VERSION ""

NS_ :

BS_:

BU_: CLU H_U CGW

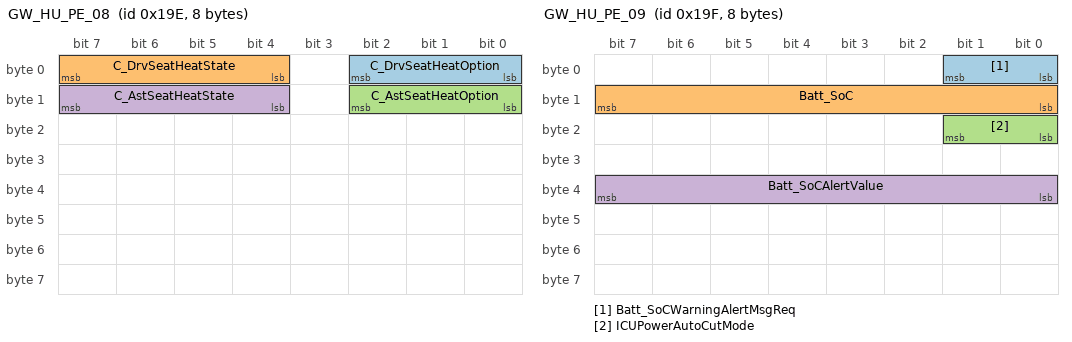
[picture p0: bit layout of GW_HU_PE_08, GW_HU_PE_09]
BO_ 414 GW_HU_PE_08: 8 CGW
 SG_ C_DrvSeatHeatOption : 2|3@0+ (1,0) [0|0] ""  H_U
 SG_ C_DrvSeatHeatState : 7|4@0+ (1,0) [0|0] ""  H_U
 SG_ C_AstSeatHeatOption : 10|3@0+ (1,0) [0|0] ""  H_U
 SG_ C_AstSeatHeatState : 15|4@0+ (1,0) [0|0] ""  H_U

BO_ 415 GW_HU_PE_09: 8 CGW
 SG_ Batt_SoCWarningAlertMsgReq : 1|2@0+ (1,0) [0|0] ""  H_U
 SG_ Batt_SoC : 15|8@0+ (1,0) [0|100] "%"  H_U
 SG_ ICUPowerAutoCutMode : 17|2@0+ (1,0) [0|3] ""  H_U
 SG_ Batt_SoCAlertValue : 39|8@0+ (1,0) [0|100] "%"  H_U

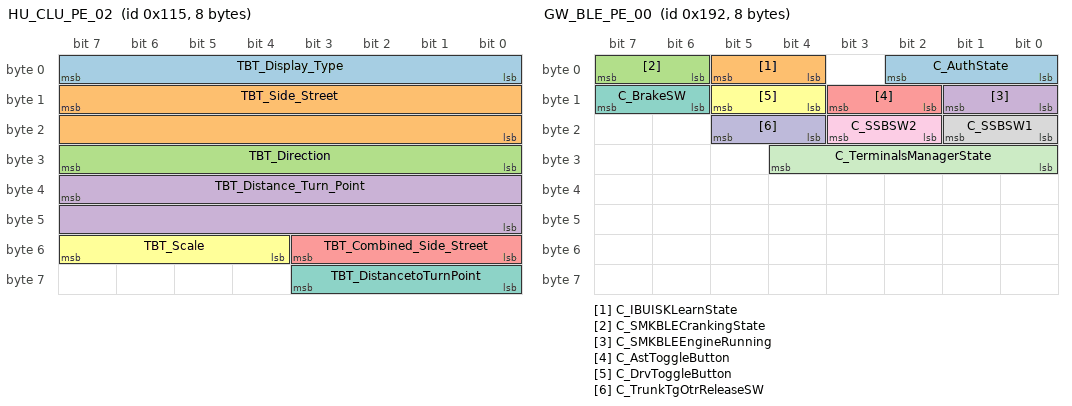
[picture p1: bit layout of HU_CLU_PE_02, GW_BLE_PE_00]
BO_ 277 HU_CLU_PE_02: 8 H_U
 SG_ TBT_Display_Type : 7|8@0+ (1,0) [0|0] ""  CLU
 SG_ TBT_Side_Street : 15|16@0+ (1,0) [0|0] ""  CLU
 SG_ TBT_Direction : 31|8@0+ (7.5,0) [0|352.5] "Degree"  CLU
 SG_ TBT_Distance_Turn_Point : 39|16@0+ (1,0) [0|0] "m"  CLU
 SG_ TBT_Combined_Side_Street : 51|4@0+ (1,0) [0|0] ""  CLU
 SG_ TBT_Scale : 55|4@0+ (1,0) [0|0] ""  CLU
 SG_ TBT_DistancetoTurnPoint : 59|4@0+ (1,0) [0|0] "times"  CLU

BO_ 413 GW_HU_PE_07: 8 CGW
 SG_ C_TSigLhSw : 37|2@0+ (1,0) [0|0] ""  H_U
 SG_ C_TSigRhSw : 39|2@0+ (1,0) [0|0] ""  H_U

BO_ 402 GW_BLE_PE_00: 8 CGW
 SG_ C_AuthState : 2|3@0+ (1,0) [0|0] ""  H_U
 SG_ C_IBUISKLearnState : 5|2@0+ (1,0) [0|0] ""  H_U
 SG_ C_SMKBLECrankingState : 7|2@0+ (1,0) [0|0] ""  H_U
 SG_ C_SMKBLEEngineRunning : 9|2@0+ (1,0) [0|0] ""  H_U
 SG_ C_AstToggleButton : 11|2@0+ (1,0) [0|0] ""  H_U
 SG_ C_DrvToggleButton : 13|2@0+ (1,0) [0|0] ""  H_U
 SG_ C_BrakeSW : 15|2@0+ (1,0) [0|0] ""  H_U
 SG_ C_SSBSW1 : 17|2@0+ (1,0) [0|0] ""  H_U
 SG_ C_SSBSW2 : 19|2@0+ (1,0) [0|0] ""  H_U
 SG_ C_TrunkTgOtrReleaseSW : 21|2@0+ (1,0) [0|0] ""  H_U
 SG_ C_TerminalsManagerState : 28|5@0+ (1,0) [0|0] ""  H_U

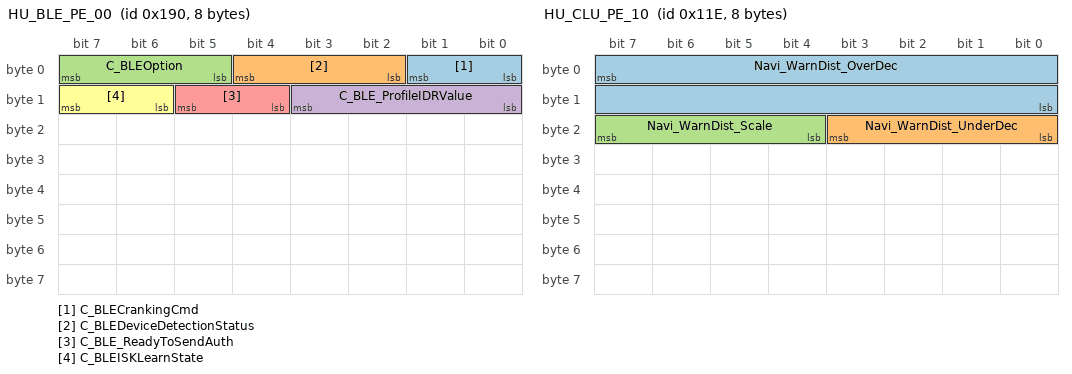
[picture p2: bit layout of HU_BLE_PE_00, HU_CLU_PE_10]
BO_ 400 HU_BLE_PE_00: 8 H_U
 SG_ C_BLECrankingCmd : 1|2@0+ (1,0) [0|0] ""  CGW
 SG_ C_BLEDeviceDetectionStatus : 4|3@0+ (1,0) [0|0] ""  CGW
 SG_ C_BLEOption : 7|3@0+ (1,0) [0|0] ""  CGW
 SG_ C_BLE_ProfileIDRValue : 11|4@0+ (1,0) [0|0] ""  CGW,CLU
 SG_ C_BLE_ReadyToSendAuth : 13|2@0+ (1,0) [0|0] ""  CGW
 SG_ C_BLEISKLearnState : 15|2@0+ (1,0) [0|0] ""  CGW

BO_ 286 HU_CLU_PE_10: 8 H_U
 SG_ Navi_WarnDist_OverDec : 7|16@0+ (1,0) [0|0] ""  CLU
 SG_ Navi_WarnDist_UnderDec : 19|4@0+ (1,0) [0|0] ""  CLU
 SG_ Navi_WarnDist_Scale : 23|4@0+ (1,0) [0|0] ""  CLU

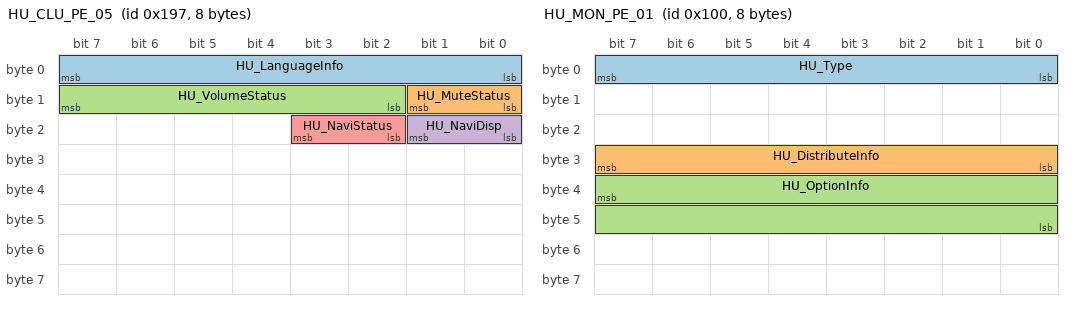
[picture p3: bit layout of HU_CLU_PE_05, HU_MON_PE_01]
BO_ 407 HU_CLU_PE_05: 8 H_U
 SG_ HU_LanguageInfo : 7|8@0+ (1,0) [0|0] ""  CGW,CLU
 SG_ HU_MuteStatus : 9|2@0+ (1,0) [0|0] ""  CLU
 SG_ HU_VolumeStatus : 15|6@0+ (1,0) [0|0] ""  CLU
 SG_ HU_NaviDisp : 17|2@0+ (1,0) [0|0] ""  CLU
 SG_ HU_NaviStatus : 19|2@0+ (1,0) [0|0] ""  CGW,CLU

BO_ 256 HU_MON_PE_01: 8 H_U
 SG_ HU_Type : 7|8@0+ (1,0) [0|0] ""  CGW,CLU
 SG_ HU_DistributeInfo : 31|8@0+ (1,0) [0|0] ""  CGW,CLU
 SG_ HU_OptionInfo : 39|16@0+ (1,0) [0|0] ""  CGW,CLU

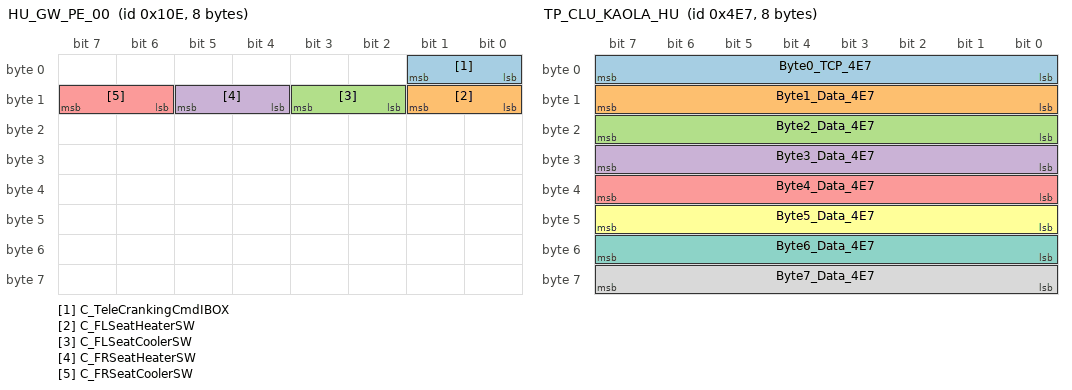
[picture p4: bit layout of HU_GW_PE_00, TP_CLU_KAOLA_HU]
BO_ 270 HU_GW_PE_00: 8 H_U
 SG_ C_TeleCrankingCmdIBOX : 1|2@0+ (1,0) [0|0] ""  CGW
 SG_ C_FLSeatHeaterSW : 9|2@0+ (1,0) [0|0] ""  CGW
 SG_ C_FLSeatCoolerSW : 11|2@0+ (1,0) [0|0] ""  CGW
 SG_ C_FRSeatHeaterSW : 13|2@0+ (1,0) [0|0] ""  CGW
 SG_ C_FRSeatCoolerSW : 15|2@0+ (1,0) [0|0] ""  CGW

BO_ 305 DATC_PE_02: 8 CGW
 SG_ DATC_DrTempDispC : 7|8@0+ (0.5,14) [15|32] "C"  H_U
 SG_ DATC_DrTempDispF : 23|8@0+ (1,56) [58|90] "F"  H_U

BO_ 1255 TP_CLU_KAOLA_HU: 8 CLU
 SG_ Byte0_TCP_4E7 : 7|8@0+ (1,0) [0|0] ""  H_U
 SG_ Byte1_Data_4E7 : 15|8@0+ (1,0) [0|0] ""  H_U
 SG_ Byte2_Data_4E7 : 23|8@0+ (1,0) [0|0] ""  H_U
 SG_ Byte3_Data_4E7 : 31|8@0+ (1,0) [0|0] ""  H_U
 SG_ Byte4_Data_4E7 : 39|8@0+ (1,0) [0|0] ""  H_U
 SG_ Byte5_Data_4E7 : 47|8@0+ (1,0) [0|0] ""  H_U
 SG_ Byte6_Data_4E7 : 55|8@0+ (1,0) [0|0] ""  H_U
 SG_ Byte7_Data_4E7 : 63|8@0+ (1,0) [0|0] ""  H_U

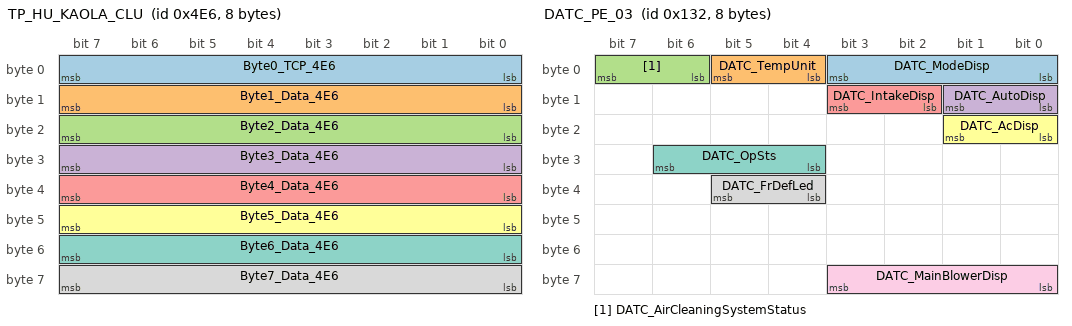
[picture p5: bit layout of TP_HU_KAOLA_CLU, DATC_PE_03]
BO_ 1254 TP_HU_KAOLA_CLU: 8 H_U
 SG_ Byte0_TCP_4E6 : 7|8@0+ (1,0) [0|0] ""  CLU
 SG_ Byte1_Data_4E6 : 15|8@0+ (1,0) [0|0] ""  CLU
 SG_ Byte2_Data_4E6 : 23|8@0+ (1,0) [0|0] ""  CLU
 SG_ Byte3_Data_4E6 : 31|8@0+ (1,0) [0|0] ""  CLU
 SG_ Byte4_Data_4E6 : 39|8@0+ (1,0) [0|0] ""  CLU
 SG_ Byte5_Data_4E6 : 47|8@0+ (1,0) [0|0] ""  CLU
 SG_ Byte6_Data_4E6 : 55|8@0+ (1,0) [0|0] ""  CLU
 SG_ Byte7_Data_4E6 : 63|8@0+ (1,0) [0|0] ""  CLU

BO_ 307 DATC_PE_04: 8 CGW
 SG_ DATC_SelfDiagDisp : 15|8@0+ (1,0) [0|0] ""  H_U
 SG_ DATC_Variant : 63|8@0+ (1,0) [0|0] ""  H_U

BO_ 306 DATC_PE_03: 8 CGW
 SG_ DATC_ModeDisp : 3|4@0+ (1,0) [0|0] ""  H_U
 SG_ DATC_TempUnit : 5|2@0+ (1,0) [0|0] ""  H_U
 SG_ DATC_AirCleaningSystemStatus : 7|2@0+ (1,0) [0|3] ""  H_U
 SG_ DATC_AutoDisp : 9|2@0+ (1,0) [0|0] ""  H_U
 SG_ DATC_IntakeDisp : 11|2@0+ (1,0) [0|0] ""  H_U
 SG_ DATC_AcDisp : 17|2@0+ (1,0) [0|0] ""  H_U
 SG_ DATC_OpSts : 30|3@0+ (1,0) [0|0] ""  H_U
 SG_ DATC_FrDefLed : 37|2@0+ (1,0) [0|0] ""  H_U
 SG_ DATC_MainBlowerDisp : 59|4@0+ (1,0) [0|0] ""  H_U

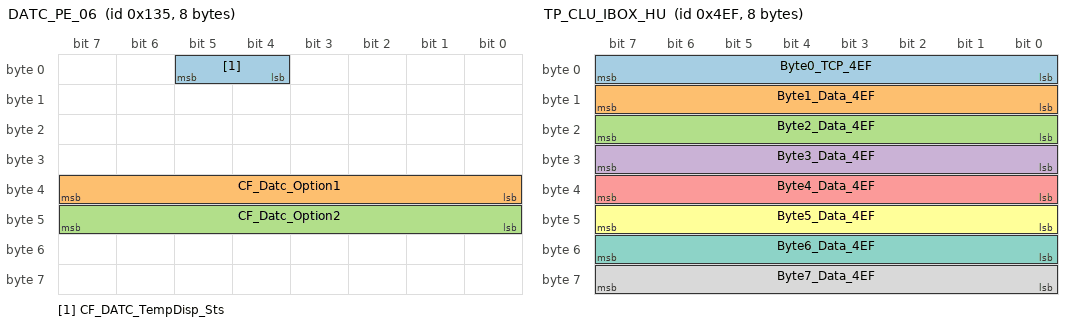
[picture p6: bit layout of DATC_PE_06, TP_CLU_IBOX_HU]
BO_ 309 DATC_PE_06: 8 CGW
 SG_ CF_DATC_TempDisp_Sts : 5|2@0+ (1,0) [0|0] ""  H_U
 SG_ CF_Datc_Option1 : 39|8@0+ (1,0) [0|0] ""  H_U
 SG_ CF_Datc_Option2 : 47|8@0+ (1,0) [0|0] ""  H_U

BO_ 1263 TP_CLU_IBOX_HU: 8 CLU
 SG_ Byte0_TCP_4EF : 7|8@0+ (1,0) [0|0] ""  H_U
 SG_ Byte1_Data_4EF : 15|8@0+ (1,0) [0|0] ""  H_U
 SG_ Byte2_Data_4EF : 23|8@0+ (1,0) [0|0] ""  H_U
 SG_ Byte3_Data_4EF : 31|8@0+ (1,0) [0|0] ""  H_U
 SG_ Byte4_Data_4EF : 39|8@0+ (1,0) [0|0] ""  H_U
 SG_ Byte5_Data_4EF : 47|8@0+ (1,0) [0|0] ""  H_U
 SG_ Byte6_Data_4EF : 55|8@0+ (1,0) [0|0] ""  H_U
 SG_ Byte7_Data_4EF : 63|8@0+ (1,0) [0|0] ""  H_U

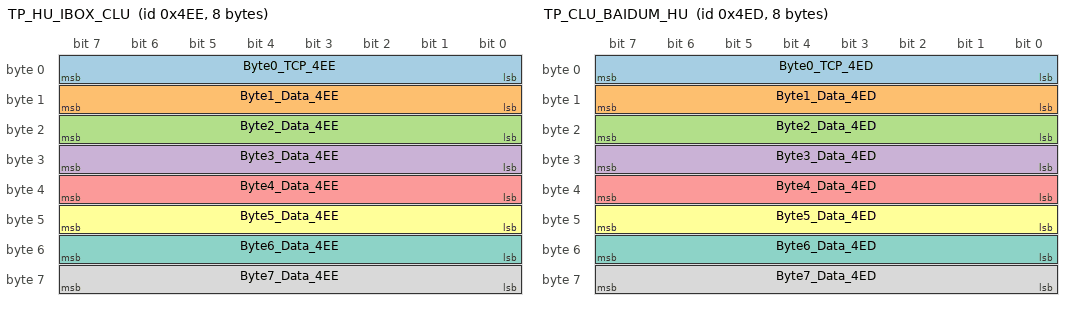
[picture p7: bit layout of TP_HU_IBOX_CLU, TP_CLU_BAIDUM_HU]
BO_ 1262 TP_HU_IBOX_CLU: 8 H_U
 SG_ Byte0_TCP_4EE : 7|8@0+ (1,0) [0|0] ""  CLU
 SG_ Byte1_Data_4EE : 15|8@0+ (1,0) [0|0] ""  CLU
 SG_ Byte2_Data_4EE : 23|8@0+ (1,0) [0|0] ""  CLU
 SG_ Byte3_Data_4EE : 31|8@0+ (1,0) [0|0] ""  CLU
 SG_ Byte4_Data_4EE : 39|8@0+ (1,0) [0|0] ""  CLU
 SG_ Byte5_Data_4EE : 47|8@0+ (1,0) [0|0] ""  CLU
 SG_ Byte6_Data_4EE : 55|8@0+ (1,0) [0|0] ""  CLU
 SG_ Byte7_Data_4EE : 63|8@0+ (1,0) [0|0] ""  CLU

BO_ 1261 TP_CLU_BAIDUM_HU: 8 CLU
 SG_ Byte0_TCP_4ED : 7|8@0+ (1,0) [0|0] ""  H_U
 SG_ Byte1_Data_4ED : 15|8@0+ (1,0) [0|0] ""  H_U
 SG_ Byte2_Data_4ED : 23|8@0+ (1,0) [0|0] ""  H_U
 SG_ Byte3_Data_4ED : 31|8@0+ (1,0) [0|0] ""  H_U
 SG_ Byte4_Data_4ED : 39|8@0+ (1,0) [0|0] ""  H_U
 SG_ Byte5_Data_4ED : 47|8@0+ (1,0) [0|0] ""  H_U
 SG_ Byte6_Data_4ED : 55|8@0+ (1,0) [0|0] ""  H_U
 SG_ Byte7_Data_4ED : 63|8@0+ (1,0) [0|0] ""  H_U

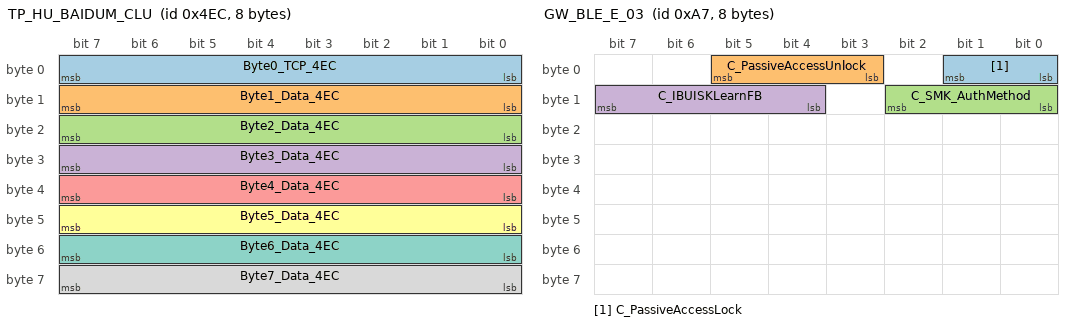
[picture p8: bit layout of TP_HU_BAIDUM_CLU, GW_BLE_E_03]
BO_ 1260 TP_HU_BAIDUM_CLU: 8 H_U
 SG_ Byte0_TCP_4EC : 7|8@0+ (1,0) [0|0] ""  CLU
 SG_ Byte1_Data_4EC : 15|8@0+ (1,0) [0|0] ""  CLU
 SG_ Byte2_Data_4EC : 23|8@0+ (1,0) [0|0] ""  CLU
 SG_ Byte3_Data_4EC : 31|8@0+ (1,0) [0|0] ""  CLU
 SG_ Byte4_Data_4EC : 39|8@0+ (1,0) [0|0] ""  CLU
 SG_ Byte5_Data_4EC : 47|8@0+ (1,0) [0|0] ""  CLU
 SG_ Byte6_Data_4EC : 55|8@0+ (1,0) [0|0] ""  CLU
 SG_ Byte7_Data_4EC : 63|8@0+ (1,0) [0|0] ""  CLU

BO_ 167 GW_BLE_E_03: 8 CGW
 SG_ C_PassiveAccessLock : 1|2@0+ (1,0) [0|0] ""  H_U
 SG_ C_PassiveAccessUnlock : 5|3@0+ (1,0) [0|0] ""  H_U
 SG_ C_SMK_AuthMethod : 10|3@0+ (1,0) [0|0] ""  H_U
 SG_ C_IBUISKLearnFB : 15|4@0+ (1,0) [0|0] ""  H_U

BO_ 166 GW_BLE_E_02: 8 CGW
 SG_ C_SMK_AuthReq : 2|3@0+ (1,0) [0|0] ""  H_U
 SG_ C_SMK_Random : 23|48@0+ (1,0) [0|0] ""  H_U

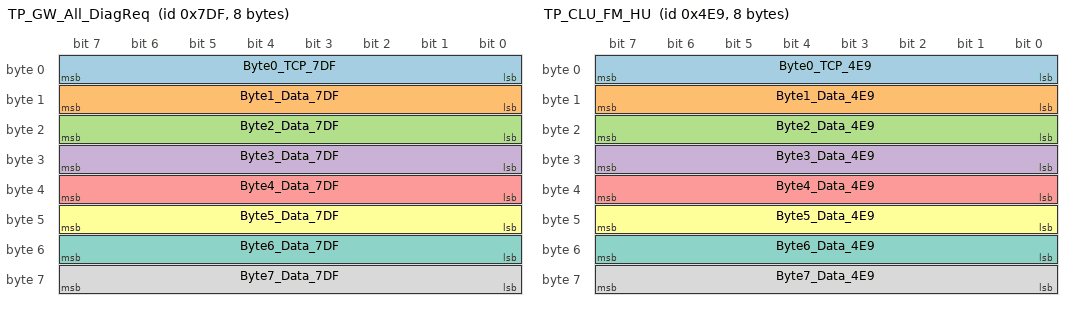
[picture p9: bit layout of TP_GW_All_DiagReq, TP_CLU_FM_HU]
BO_ 2015 TP_GW_All_DiagReq: 8 CGW
 SG_ Byte0_TCP_7DF : 7|8@0+ (1,0) [0|0] ""  CLU,H_U
 SG_ Byte1_Data_7DF : 15|8@0+ (1,0) [0|0] ""  CLU,H_U
 SG_ Byte2_Data_7DF : 23|8@0+ (1,0) [0|0] ""  CLU,H_U
 SG_ Byte3_Data_7DF : 31|8@0+ (1,0) [0|0] ""  CLU,H_U
 SG_ Byte4_Data_7DF : 39|8@0+ (1,0) [0|0] ""  CLU,H_U
 SG_ Byte5_Data_7DF : 47|8@0+ (1,0) [0|0] ""  CLU,H_U
 SG_ Byte6_Data_7DF : 55|8@0+ (1,0) [0|0] ""  CLU,H_U
 SG_ Byte7_Data_7DF : 63|8@0+ (1,0) [0|0] ""  CLU,H_U

BO_ 165 GW_BLE_E_01: 8 CGW
 SG_ C_SMK_Encrypted_Result2 : 7|64@0+ (1,0) [0|0] ""  H_U

BO_ 1257 TP_CLU_FM_HU: 8 CLU
 SG_ Byte0_TCP_4E9 : 7|8@0+ (1,0) [0|0] ""  H_U
 SG_ Byte1_Data_4E9 : 15|8@0+ (1,0) [0|0] ""  H_U
 SG_ Byte2_Data_4E9 : 23|8@0+ (1,0) [0|0] ""  H_U
 SG_ Byte3_Data_4E9 : 31|8@0+ (1,0) [0|0] ""  H_U
 SG_ Byte4_Data_4E9 : 39|8@0+ (1,0) [0|0] ""  H_U
 SG_ Byte5_Data_4E9 : 47|8@0+ (1,0) [0|0] ""  H_U
 SG_ Byte6_Data_4E9 : 55|8@0+ (1,0) [0|0] ""  H_U
 SG_ Byte7_Data_4E9 : 63|8@0+ (1,0) [0|0] ""  H_U

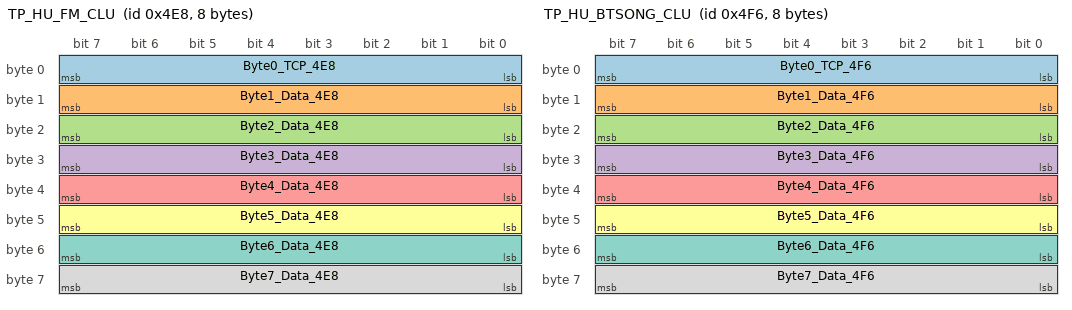
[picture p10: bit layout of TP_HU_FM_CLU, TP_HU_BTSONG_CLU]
BO_ 1256 TP_HU_FM_CLU: 8 H_U
 SG_ Byte0_TCP_4E8 : 7|8@0+ (1,0) [0|0] ""  CLU
 SG_ Byte1_Data_4E8 : 15|8@0+ (1,0) [0|0] ""  CLU
 SG_ Byte2_Data_4E8 : 23|8@0+ (1,0) [0|0] ""  CLU
 SG_ Byte3_Data_4E8 : 31|8@0+ (1,0) [0|0] ""  CLU
 SG_ Byte4_Data_4E8 : 39|8@0+ (1,0) [0|0] ""  CLU
 SG_ Byte5_Data_4E8 : 47|8@0+ (1,0) [0|0] ""  CLU
 SG_ Byte6_Data_4E8 : 55|8@0+ (1,0) [0|0] ""  CLU
 SG_ Byte7_Data_4E8 : 63|8@0+ (1,0) [0|0] ""  CLU

BO_ 164 GW_BLE_E_00: 8 CGW
 SG_ C_SMK_Encrypted_Result1 : 7|64@0+ (1,0) [0|0] ""  H_U

BO_ 1270 TP_HU_BTSONG_CLU: 8 H_U
 SG_ Byte0_TCP_4F6 : 7|8@0+ (1,0) [0|0] ""  CLU
 SG_ Byte1_Data_4F6 : 15|8@0+ (1,0) [0|0] ""  CLU
 SG_ Byte2_Data_4F6 : 23|8@0+ (1,0) [0|0] ""  CLU
 SG_ Byte3_Data_4F6 : 31|8@0+ (1,0) [0|0] ""  CLU
 SG_ Byte4_Data_4F6 : 39|8@0+ (1,0) [0|0] ""  CLU
 SG_ Byte5_Data_4F6 : 47|8@0+ (1,0) [0|0] ""  CLU
 SG_ Byte6_Data_4F6 : 55|8@0+ (1,0) [0|0] ""  CLU
 SG_ Byte7_Data_4F6 : 63|8@0+ (1,0) [0|0] ""  CLU

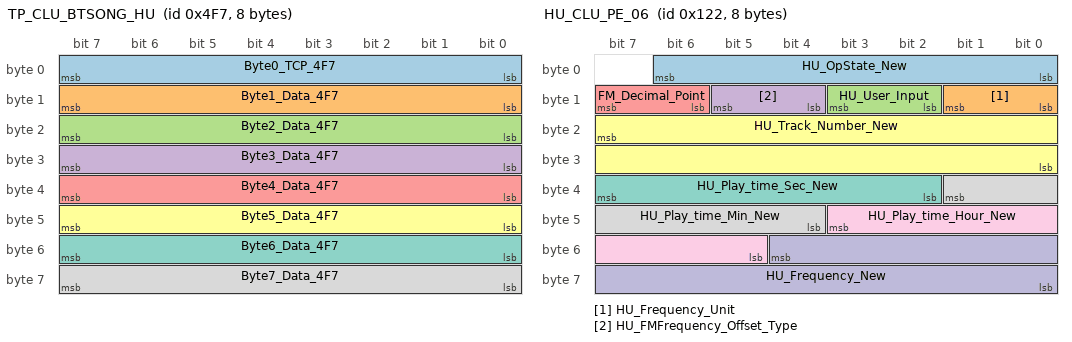
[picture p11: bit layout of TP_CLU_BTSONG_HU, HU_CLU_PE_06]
BO_ 1271 TP_CLU_BTSONG_HU: 8 CLU
 SG_ Byte0_TCP_4F7 : 7|8@0+ (1,0) [0|0] ""  H_U
 SG_ Byte1_Data_4F7 : 15|8@0+ (1,0) [0|0] ""  H_U
 SG_ Byte2_Data_4F7 : 23|8@0+ (1,0) [0|0] ""  H_U
 SG_ Byte3_Data_4F7 : 31|8@0+ (1,0) [0|0] ""  H_U
 SG_ Byte4_Data_4F7 : 39|8@0+ (1,0) [0|0] ""  H_U
 SG_ Byte5_Data_4F7 : 47|8@0+ (1,0) [0|0] ""  H_U
 SG_ Byte6_Data_4F7 : 55|8@0+ (1,0) [0|0] ""  H_U
 SG_ Byte7_Data_4F7 : 63|8@0+ (1,0) [0|0] ""  H_U

BO_ 290 HU_CLU_PE_06: 8 H_U
 SG_ HU_OpState_New : 6|7@0+ (1,0) [0|0] ""  CLU
 SG_ HU_Frequency_Unit : 9|2@0+ (1,0) [0|0] ""  CLU
 SG_ HU_User_Input : 11|2@0+ (1,0) [0|0] ""  CLU
 SG_ HU_FMFrequency_Offset_Type : 13|2@0+ (1,0) [0|0] ""  CLU
 SG_ FM_Decimal_Point : 15|2@0+ (1,0) [0|0] ""  CLU
 SG_ HU_Track_Number_New : 23|16@0+ (1,0) [0|0] ""  CLU
 SG_ HU_Play_time_Sec_New : 39|6@0+ (1,0) [0|0] ""  CLU
 SG_ HU_Play_time_Min_New : 33|6@0+ (1,0) [0|0] ""  CLU
 SG_ HU_Play_time_Hour_New : 43|7@0+ (1,0) [0|0] ""  CLU
 SG_ HU_Frequency_New : 52|13@0+ (1,0) [0|0] ""  CLU

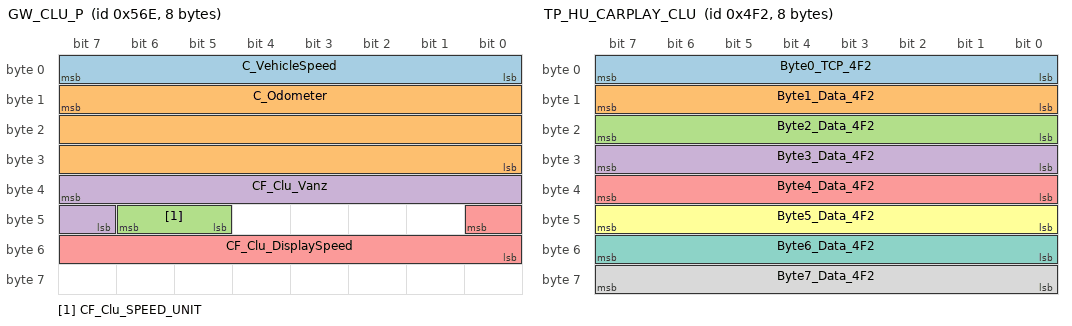
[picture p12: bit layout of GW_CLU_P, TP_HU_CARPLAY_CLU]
BO_ 1390 GW_CLU_P: 8 CGW
 SG_ C_VehicleSpeed : 7|8@0+ (1,0) [0|254] ""  H_U
 SG_ C_Odometer : 15|24@0+ (0.1,0) [0|1677721.4] ""  H_U
 SG_ CF_Clu_SPEED_UNIT : 46|2@0+ (1,0) [0|0] ""  H_U
 SG_ CF_Clu_Vanz : 39|9@0+ (0.5,0) [0|0] ""  H_U
 SG_ CF_Clu_DisplaySpeed : 40|9@0+ (1,0) [0|510] "km/h or MPH"  H_U

BO_ 291 HU_CLU_PE_07: 8 H_U
 SG_ NV_Display_TG : 31|2@0+ (1,0) [0|0] ""  CLU
 SG_ TBT_BarGraph100Level : 63|8@0+ (1,0) [0|100] "%"  CLU

BO_ 1266 TP_HU_CARPLAY_CLU: 8 H_U
 SG_ Byte0_TCP_4F2 : 7|8@0+ (1,0) [0|0] ""  CLU
 SG_ Byte1_Data_4F2 : 15|8@0+ (1,0) [0|0] ""  CLU
 SG_ Byte2_Data_4F2 : 23|8@0+ (1,0) [0|0] ""  CLU
 SG_ Byte3_Data_4F2 : 31|8@0+ (1,0) [0|0] ""  CLU
 SG_ Byte4_Data_4F2 : 39|8@0+ (1,0) [0|0] ""  CLU
 SG_ Byte5_Data_4F2 : 47|8@0+ (1,0) [0|0] ""  CLU
 SG_ Byte6_Data_4F2 : 55|8@0+ (1,0) [0|0] ""  CLU
 SG_ Byte7_Data_4F2 : 63|8@0+ (1,0) [0|0] ""  CLU

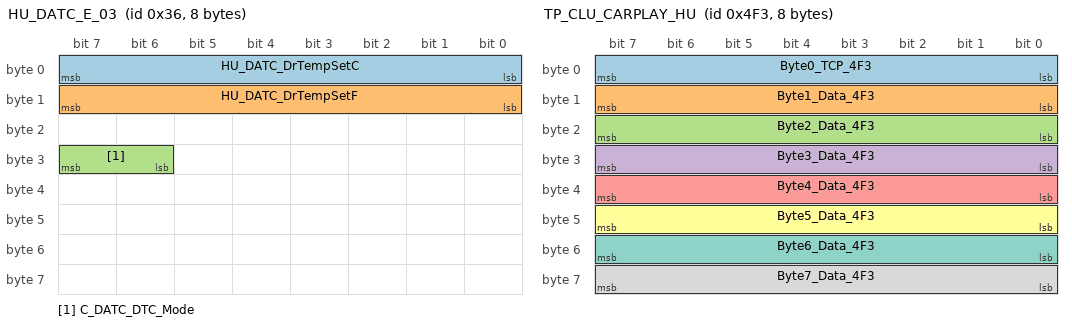
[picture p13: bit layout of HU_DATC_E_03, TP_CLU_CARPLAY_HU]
BO_ 54 HU_DATC_E_03: 8 H_U
 SG_ HU_DATC_DrTempSetC : 7|8@0+ (0.5,14) [15|32] "℃"  CGW,CLU
 SG_ HU_DATC_DrTempSetF : 15|8@0+ (1,56) [58|90] "℉"  CGW,CLU
 SG_ C_DATC_DTC_Mode : 31|2@0+ (1,0) [0|0] ""  CGW

BO_ 1267 TP_CLU_CARPLAY_HU: 8 CLU
 SG_ Byte0_TCP_4F3 : 7|8@0+ (1,0) [0|0] ""  H_U
 SG_ Byte1_Data_4F3 : 15|8@0+ (1,0) [0|0] ""  H_U
 SG_ Byte2_Data_4F3 : 23|8@0+ (1,0) [0|0] ""  H_U
 SG_ Byte3_Data_4F3 : 31|8@0+ (1,0) [0|0] ""  H_U
 SG_ Byte4_Data_4F3 : 39|8@0+ (1,0) [0|0] ""  H_U
 SG_ Byte5_Data_4F3 : 47|8@0+ (1,0) [0|0] ""  H_U
 SG_ Byte6_Data_4F3 : 55|8@0+ (1,0) [0|0] ""  H_U
 SG_ Byte7_Data_4F3 : 63|8@0+ (1,0) [0|0] ""  H_U

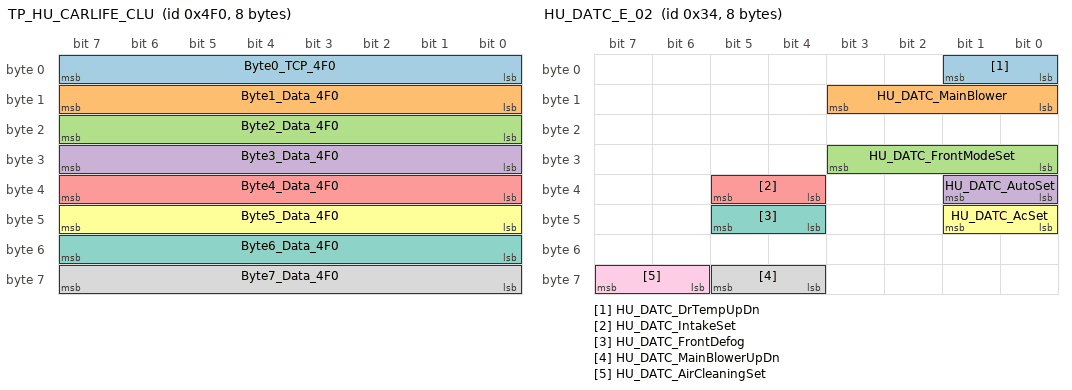
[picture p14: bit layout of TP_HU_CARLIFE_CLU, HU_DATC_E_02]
BO_ 1264 TP_HU_CARLIFE_CLU: 8 H_U
 SG_ Byte0_TCP_4F0 : 7|8@0+ (1,0) [0|0] ""  CLU
 SG_ Byte1_Data_4F0 : 15|8@0+ (1,0) [0|0] ""  CLU
 SG_ Byte2_Data_4F0 : 23|8@0+ (1,0) [0|0] ""  CLU
 SG_ Byte3_Data_4F0 : 31|8@0+ (1,0) [0|0] ""  CLU
 SG_ Byte4_Data_4F0 : 39|8@0+ (1,0) [0|0] ""  CLU
 SG_ Byte5_Data_4F0 : 47|8@0+ (1,0) [0|0] ""  CLU
 SG_ Byte6_Data_4F0 : 55|8@0+ (1,0) [0|0] ""  CLU
 SG_ Byte7_Data_4F0 : 63|8@0+ (1,0) [0|0] ""  CLU

BO_ 294 GW_RVM_PE_00: 8 CGW
 SG_ CAM_Status : 9|2@0+ (1,0) [0|0] ""  H_U

BO_ 52 HU_DATC_E_02: 8 H_U
 SG_ HU_DATC_DrTempUpDn : 1|2@0+ (1,0) [0|0] ""  CGW,CLU
 SG_ HU_DATC_MainBlower : 11|4@0+ (1,0) [0|0] ""  CGW,CLU
 SG_ HU_DATC_FrontModeSet : 27|4@0+ (1,0) [0|0] ""  CGW,CLU
 SG_ HU_DATC_AutoSet : 33|2@0+ (1,0) [0|0] ""  CGW,CLU
 SG_ HU_DATC_IntakeSet : 37|2@0+ (1,0) [0|0] ""  CGW,CLU
 SG_ HU_DATC_AcSet : 41|2@0+ (1,0) [0|0] ""  CGW,CLU
 SG_ HU_DATC_FrontDefog : 45|2@0+ (1,0) [0|0] ""  CGW,CLU
 SG_ HU_DATC_MainBlowerUpDn : 61|2@0+ (1,0) [0|0] ""  CGW,CLU
 SG_ HU_DATC_AirCleaningSet : 63|2@0+ (1,0) [0|0] ""  CGW,CLU

CM_ BO_ 305 "[PE] Periodic and On Event";
CM_ SG_ 305 DATC_DrTempDispC "Temperature of Driver seat (C)";
CM_ SG_ 305 DATC_DrTempDispF "Temperature of Driver seat (F)";
CM_ BO_ 306 "[PE] Periodic and On Event";
CM_ SG_ 306 DATC_ModeDisp "Display DATC Mode of Driver side



Basic Modes

- Defog : Defog

- Vent : Upper

- Def : Middle

- Floor : Lower



Mixed Modes

- Auto Defog : Defog + Auto 

- Max Defog : Defog + Seat



* Compatabilityfor old value table 

- Vent/Floor : same with old B/L 

- Defog/Floor : same with old MIX 

- Max Defog : same with old DEF";
CM_ SG_ 306 DATC_TempUnit "Unit of Temperature";
CM_ SG_ 306 DATC_AirCleaningSystemStatus "Air Cleaning System Operate Status";
CM_ SG_ 306 DATC_AutoDisp "Display AUTO";
CM_ SG_ 306 DATC_IntakeDisp "Display INTAKE";
CM_ SG_ 306 DATC_AcDisp "Display A/C";
CM_ SG_ 306 DATC_OpSts "Display DATC Operation Status";
CM_ SG_ 306 DATC_FrDefLed "Front Defo LED light status";
CM_ SG_ 306 DATC_MainBlowerDisp "Display Level of Main Blower";
CM_ BO_ 307 "[PE] Periodic and On Event";
CM_ SG_ 307 DATC_SelfDiagDisp "Inform HVAC Controller or Sensor error";
CM_ SG_ 307 DATC_Variant "Bit0 (FR CTRL) : 0 - ATC / 1 - MTC
Bit1~2 (Temp) : 00 - Single / 01 - Dual / 10 - 3 Zone / 11 - 4 Zone
Bit3~4 (Mode) : 00 - Single / 01 - Dual / 10 - 3 Zone / 11 - 4 Zone 
Bit5 (Rear Control) : 0 - (None or MTC) / 1 - ATC
Bit6 (RHD) : 0 - LHD / 1 - RHD
Bit7 (EU) : 0 - Others / 1 - EU";
CM_ BO_ 309 "[PE] Periodic and On Event";
CM_ SG_ 309 CF_DATC_TempDisp_Sts "This signal is an information display of the set temperature range of DATC.";
CM_ SG_ 309 CF_Datc_Option1 "This signal indicates Option of HEATER SYSTEM

Bit0 (ADS)? : 0 - Non ADS / 1 - ADS
 Bit1 (AQS) : 0 - Non AQS /? 1 ? AQS=
 Bit2 (MAX AC) : 0 - Non MAX AC / 1 - MAX AC
 Bit3 (SYNC) : 0 - Non SYNC /? 1 - SYNC 
 Bit4 (DUST) : 0 - Non AIR PURIFIER /? 1 - AIR PURIFIER 
 Bit5 : (Smart_Vent) : 0 - Non SMART VENT / 1 ? SMART VENT
 Bit6 : (CO2) : 0 - Non CO2 / 1 - CO2
 Bit7 : (REAR LOCK) : 0 - NON REAR LOCK / 1 ? REAR LOCK 
 0xFF : invalid";
CM_ SG_ 309 CF_Datc_Option2 "Bit0 (FRONT BLOWER) : 0 ? SINGLE BLOWER / 1 ? DUAL BLOWER
 Bit1 (FRONT AUTO ZONE) : 0 ? SINGLE AUTO / 1 - DUAL AUTO
 Bit2 (LCD / NON LCD TYPE) : 0- NON LCD / 1- LCD TYPE?
 Bit3 : Reserved 
 Bit4 : Reserved 
 Bit5 : Reserved 
 Bit6 : Reserved 
 Bit7 : Reserved
0xFF : Invalid";
CM_ BO_ 164 "[EC] On Event and On Change";
CM_ SG_ 164 C_SMK_Encrypted_Result1 "This signal is for a send encrypted result of IBU.";
CM_ BO_ 165 "[EC] On Event and On Change";
CM_ SG_ 165 C_SMK_Encrypted_Result2 "This signal is for a send encrypted result of IBU.";
CM_ BO_ 166 "[EC] On Event and On Change";
CM_ SG_ 166 C_SMK_AuthReq "Request BLE authentication";
CM_ SG_ 166 C_SMK_Random "Random number";
CM_ BO_ 167 "[EC] On Event and On Change";
CM_ SG_ 167 C_PassiveAccessLock "BLE passive lock command response";
CM_ SG_ 167 C_PassiveAccessUnlock "BLE passive unlock command response";
CM_ SG_ 167 C_SMK_AuthMethod "This signal is for a send Authentication result and authentication method.
- Fob, TP, Fingerprint, NFC, BLE";
CM_ SG_ 167 C_IBUISKLearnFB "This signal is Learning Feedback";
CM_ BO_ 402 "[PE] Periodic and On Event";
CM_ SG_ 402 C_AuthState "This signal is status of IBU auth";
CM_ SG_ 402 C_IBUISKLearnState "This signal is State of IBU Learning";
CM_ SG_ 402 C_SMKBLECrankingState "BLE cranking response";
CM_ SG_ 402 C_SMKBLEEngineRunning "This signal is state of engine running, for BLE engine start command.";
CM_ SG_ 402 C_AstToggleButton "This signal is for assist door handle button";
CM_ SG_ 402 C_DrvToggleButton "This signal is for driver door handle button.";
CM_ SG_ 402 C_BrakeSW "SMK+ Brake SW input state";
CM_ SG_ 402 C_SSBSW1 "StartStop button switch #1 status";
CM_ SG_ 402 C_SSBSW2 "StartStop button switch #2 status";
CM_ SG_ 402 C_TrunkTgOtrReleaseSW "Trunk/Tailgate Outter Release SW";
CM_ SG_ 402 C_TerminalsManagerState "Mirror value of TerminalsManager Stat";
CM_ BO_ 1390 "[P] Periodic";
CM_ SG_ 1390 C_VehicleSpeed "Information for Vehicle speed
* For ASD Option Vehicle, Use ASD_VehicleSpeed (@0x500) instead *";
CM_ SG_ 1390 C_Odometer "Information for Odometer in kilometer";
CM_ SG_ 1390 CF_Clu_SPEED_UNIT "This signal is unit of display speed in cluster";
CM_ SG_ 1390 CF_Clu_Vanz "This signal is display speed in cluster.";
CM_ SG_ 1390 CF_Clu_DisplaySpeed "The Display Speed which is indicated in the speedometer has to be sent to CGW, HUD. This signal should be sent in km/h or MPH according to the 'SPEED_UNIT' signal.  
SPEED_UNIT = 0 : [km/h]
SPEED_UNIT = 1 : [MPH]";
CM_ BO_ 413 "[PE] Periodic and On Event";
CM_ SG_ 413 C_TSigLhSw "Status of Left Turn Signal On/Off";
CM_ SG_ 413 C_TSigRhSw "Status of Right Turn Signal On/Off";
CM_ BO_ 414 "[PE] Periodic and On Event";
CM_ SG_ 414 C_DrvSeatHeatOption "Seat Option information for Remote Seat Heat/Vent control (Driver)";
CM_ SG_ 414 C_DrvSeatHeatState "Current Seat State information for Remote Seat Heat/Vent control (Driver)";
CM_ SG_ 414 C_AstSeatHeatOption "Seat Option information for Remote Seat Heat/Vent control (Passenger)";
CM_ SG_ 414 C_AstSeatHeatState "Current Seat State information for Remote Seat Heat/Vent control (Passenger)";
CM_ BO_ 415 "[PE] Periodic and On Event";
CM_ SG_ 415 Batt_SoCWarningAlertMsgReq "Determine if soc level is warning or alert.";
CM_ SG_ 415 Batt_SoC "State of Charge.";
CM_ SG_ 415 ICUPowerAutoCutMode "ICU Delivery Mode State";
CM_ SG_ 415 Batt_SoCAlertValue "Value of SoC alert level";
CM_ BO_ 294 "[PE] Periodic and On Event";
CM_ SG_ 294 CAM_Status "AHD(Analog High Definition) camera status for HU";
CM_ BO_ 2015 "[TP] TP Message";
CM_ SG_ 2015 Byte0_TCP_7DF "TP";
CM_ SG_ 2015 Byte1_Data_7DF "TP";
CM_ SG_ 2015 Byte2_Data_7DF "TP";
CM_ SG_ 2015 Byte3_Data_7DF "TP";
CM_ SG_ 2015 Byte4_Data_7DF "TP";
CM_ SG_ 2015 Byte5_Data_7DF "TP";
CM_ SG_ 2015 Byte6_Data_7DF "TP";
CM_ SG_ 2015 Byte7_Data_7DF "TP";
CM_ BO_ 1261 "[TP] TP Message";
CM_ SG_ 1261 Byte0_TCP_4ED "Contents releted with Baidu Music";
CM_ SG_ 1261 Byte1_Data_4ED "Contents releted with Baidu Music";
CM_ SG_ 1261 Byte2_Data_4ED "Contents releted with Baidu Music";
CM_ SG_ 1261 Byte3_Data_4ED "Contents releted with Baidu Music";
CM_ SG_ 1261 Byte4_Data_4ED "Contents releted with Baidu Music";
CM_ SG_ 1261 Byte5_Data_4ED "Contents releted with Baidu Music";
CM_ SG_ 1261 Byte6_Data_4ED "Contents releted with Baidu Music";
CM_ SG_ 1261 Byte7_Data_4ED "Contents releted with Baidu Music";
CM_ BO_ 1271 "[TP] TP Message";
CM_ BO_ 1267 "[TP] TP Message";
CM_ BO_ 1257 "[TP] TP Message";
CM_ SG_ 1257 Byte0_TCP_4E9 "TP from CLU to HU (FM Station Name)";
CM_ SG_ 1257 Byte1_Data_4E9 "TP from CLU to HU (FM Station Name)";
CM_ SG_ 1257 Byte2_Data_4E9 "TP from CLU to HU (FM Station Name)";
CM_ SG_ 1257 Byte3_Data_4E9 "TP from CLU to HU (FM Station Name)";
CM_ SG_ 1257 Byte4_Data_4E9 "TP from CLU to HU (FM Station Name)";
CM_ SG_ 1257 Byte5_Data_4E9 "TP from CLU to HU (FM Station Name)";
CM_ SG_ 1257 Byte6_Data_4E9 "TP from CLU to HU (FM Station Name)";
CM_ SG_ 1257 Byte7_Data_4E9 "TP from CLU to HU (FM Station Name)";
CM_ BO_ 1263 "[TP] TP Message";
CM_ SG_ 1263 Byte0_TCP_4EF "Flow Control message for TP_HU_IBOX_CLU";
CM_ SG_ 1263 Byte1_Data_4EF "Flow Control message for TP_HU_IBOX_CLU";
CM_ SG_ 1263 Byte2_Data_4EF "Flow Control message for TP_HU_IBOX_CLU";
CM_ SG_ 1263 Byte3_Data_4EF "Flow Control message for TP_HU_IBOX_CLU";
CM_ SG_ 1263 Byte4_Data_4EF "Flow Control message for TP_HU_IBOX_CLU";
CM_ SG_ 1263 Byte5_Data_4EF "Flow Control message for TP_HU_IBOX_CLU";
CM_ SG_ 1263 Byte6_Data_4EF "Flow Control message for TP_HU_IBOX_CLU";
CM_ SG_ 1263 Byte7_Data_4EF "Flow Control message for TP_HU_IBOX_CLU";
CM_ BO_ 1255 "[TP] TP Message";
CM_ SG_ 1255 Byte0_TCP_4E7 "Contents related with Kaola FM";
CM_ SG_ 1255 Byte1_Data_4E7 "Contents related with Kaola FM";
CM_ SG_ 1255 Byte2_Data_4E7 "Contents related with Kaola FM";
CM_ SG_ 1255 Byte3_Data_4E7 "Contents related with Kaola FM";
CM_ SG_ 1255 Byte4_Data_4E7 "Contents related with Kaola FM";
CM_ SG_ 1255 Byte5_Data_4E7 "Contents related with Kaola FM";
CM_ SG_ 1255 Byte6_Data_4E7 "Contents related with Kaola FM";
CM_ SG_ 1255 Byte7_Data_4E7 "Contents related with Kaola FM";
CM_ BO_ 400 "[PE] Periodic and On Event";
CM_ SG_ 400 C_BLECrankingCmd "For BLE Remote Cranking Command";
CM_ SG_ 400 C_BLEDeviceDetectionStatus "BLE Device Detection Status (Door Handle, SSB)";
CM_ SG_ 400 C_BLEOption "BLE Option Info(NFC, FP, BLE, etc)";
CM_ SG_ 400 C_BLE_ProfileIDRValue "This signal Indicate the Current detected Profile ID by BLE";
CM_ SG_ 400 C_BLE_ReadyToSendAuth "This signal is sent when BLE is ready to send Authentication data";
CM_ SG_ 400 C_BLEISKLearnState "This signal is State of BLE Learning";
CM_ BO_ 277 "[PE] Periodic and On Event";
CM_ SG_ 277 TBT_Display_Type "Information for NAVI TBT Display type";
CM_ SG_ 277 TBT_Side_Street "Information for whole directions of street
(Using according to display type definition)
15 directions (except backward) are assigned to each 15 bits";
CM_ SG_ 277 TBT_Direction "Information for direction defined at TBT_Display_Type
- 48 directions (7.5 deg. Interval)
- Vehicles following HUD/Cluster Interface Spec (ES-96560-22) use only 16 directions (22.5 deg. Interval)";
CM_ SG_ 277 TBT_Distance_Turn_Point "Remaining distance to turn point (over Decimal Point)";
CM_ SG_ 277 TBT_Combined_Side_Street "Information for direction of combined side street (in front of turn point)
(Using according to display type definition)";
CM_ SG_ 277 TBT_Scale "Information for Scale unit (m, km, mile, feet)";
CM_ SG_ 277 TBT_DistancetoTurnPoint "Information for remaining distance from turn point (under Decimal Point)";
CM_ BO_ 407 "[PE] Periodic and On Event";
CM_ SG_ 407 HU_LanguageInfo "Information for System Language (for Display Font)";
CM_ SG_ 407 HU_MuteStatus "Information for System Mute Display";
CM_ SG_ 407 HU_VolumeStatus "Information for AVN Volume";
CM_ SG_ 407 HU_NaviDisp "Information for Navi Display status on Front Monitor";
CM_ SG_ 407 HU_NaviStatus "Information for Navigation Status (Booting, Normal Operation, No SD card)
-AVN NAVI Transmission Signal";
CM_ BO_ 290 "[PE] Periodic and On Event";
CM_ SG_ 290 HU_OpState_New "Information for AV Operation mode";
CM_ SG_ 290 HU_Frequency_Unit "Information for Frequency unit display";
CM_ SG_ 290 HU_User_Input "User Input (Seek Up/Dn, Mode Change)
# Singnal Trigger Condition
1. DiscCD/MP3CD/VCD
 - Track Up/Dn (by SoftKey)
 - Track Up/Dn (by HardKey)
 - Song Change (by List)
 - Song Cjamge (by Tune Enter)
2. DVD (No TP)
 - Track Up/Dn (by SoftKey)
 - Track Up/Dn (by HardKey)
 - Song Change (by List)
 - Song Cjamge (by Tune Enter)
3. DMB/DAB
 - Track Up/Dn (by HardKey)
 - Song Change (by List)
 - Song Cjamge (by Tune Enter)
4. FM/AM/SXM
 - Track Up/Dn (by HardKey)
 - Song Change (by List)
5. ITM(FM/DAB)
 - Track Up/Dn (by HardKey)
 - Song Change (by List)
 - Song Cjamge (by Tune Enter)
6. USB Music/Video/My Music/JukeBox/iPod/Pandora
 - Track Up/Dn (by SoftKey)
 - Track Up/Dn (by HardKey)
 - Song Change (by List)
 - Song Cjamge (by Tune Enter)
7. Bluetooth Audio
 - Track Up/Dn (by SoftKey)
 - Track Up/Dn (by HardKey)
8. CarPlay/Android Auto
 - Track Up/Dn (by HardKey)";
CM_ SG_ 290 HU_FMFrequency_Offset_Type "Information for FM frequency offset type";
CM_ SG_ 290 FM_Decimal_Point "Information for Frequency decimal point";
CM_ SG_ 290 HU_Track_Number_New "Information for Number of Track / Chapter / Playlist";
CM_ SG_ 290 HU_Play_time_Sec_New "Information for Play time in Second unit";
CM_ SG_ 290 HU_Play_time_Min_New "Information for Play time in Minute unit";
CM_ SG_ 290 HU_Play_time_Hour_New "Information for Play time in Hour unit";
CM_ SG_ 290 HU_Frequency_New "Information for Radio Frequency";
CM_ BO_ 291 "[PE] Periodic and On Event";
CM_ SG_ 291 NV_Display_TG "Information for Toll Gate Display";
CM_ SG_ 291 TBT_BarGraph100Level "Information for Bar Graph Level (0 ~ 100%, 10% interval), 

if your system develop after 2012-09-10, you must not use TBT_Bar_Level(@0x115)";
CM_ BO_ 286 "[PE] Periodic and On Event";
CM_ SG_ 286 Navi_WarnDist_OverDec "Remaining distance to warning information (over decimal point)";
CM_ SG_ 286 Navi_WarnDist_UnderDec "Remaining distance to warning information (under decimal point)";
CM_ SG_ 286 Navi_WarnDist_Scale "Scale unit of warning distance";
CM_ BO_ 52 "[EC] On Event and On Change";
CM_ SG_ 52 HU_DATC_DrTempUpDn "Temperature control of Driver side";
CM_ SG_ 52 HU_DATC_MainBlower "Main Blower control";
CM_ SG_ 52 HU_DATC_FrontModeSet "DATC Mode control";
CM_ SG_ 52 HU_DATC_AutoSet "DATC Auto control";
CM_ SG_ 52 HU_DATC_IntakeSet "DATC Intake control";
CM_ SG_ 52 HU_DATC_AcSet "DATC A/C control";
CM_ SG_ 52 HU_DATC_FrontDefog "Front window Defog";
CM_ SG_ 52 HU_DATC_MainBlowerUpDn "Main Blower Up/Down control";
CM_ SG_ 52 HU_DATC_AirCleaningSet "Air Cleaning System set";
CM_ BO_ 54 "[EC] On Event and On Change";
CM_ SG_ 54 HU_DATC_DrTempSetC "In single type DATC, set temperature of front side directly(Centigrade).
In dual type DATC, set temperature of front left side directly(Centigrade).";
CM_ SG_ 54 HU_DATC_DrTempSetF "In single type DATC, set temperature of front side directly (Fahrenheit).
In dual type DATC, set temperature of front left side directly (Fahrenheit).";
CM_ SG_ 54 C_DATC_DTC_Mode "HU diagnosis request to DATC";
CM_ BO_ 270 "[PE] Periodic and On Event";
CM_ SG_ 270 C_TeleCrankingCmdIBOX "Command for Remote Cranking
(C_SMKTeleEngineRunning@0x15E is feedback signal)";
CM_ SG_ 270 C_FLSeatHeaterSW "HU touch command for seat heat control (For driver seat)";
CM_ SG_ 270 C_FLSeatCoolerSW "HU touch command for seat vent control (For driver seat)";
CM_ SG_ 270 C_FRSeatHeaterSW "HU touch command for seat heat control (For passenger seat)";
CM_ SG_ 270 C_FRSeatCoolerSW "HU touch command for seat vent control  (For passenger seat)";
CM_ BO_ 256 "[PE] Periodic and On Event";
CM_ SG_ 256 HU_Type "Information for H/U Platform type
- Integrated AVN 1.0 use different value depends on development company (Mobis:0x68/LG:0x70)
- Integrated AVN 1.0 Mobis is developed based on Display Audio
- Integrated AVN 1.0 LG is developed based on Compact AVN

Information for China OPIO Platform
- 0xFC: China OPIO w/o CLU interface (most of phase1)
- 0xFD: China OPIO w/CLU interface (parts of phase1, phase2)

Information for Audio Platform Type
- 0x43 : Audio 4.0 Value";
CM_ SG_ 256 HU_DistributeInfo "Region :Europe/North America/
Vehicle Type : RHD/LHD
Positionning information";
CM_ SG_ 256 HU_OptionInfo "Information of H/U functions";
CM_ BO_ 1260 "[TP] TP Message";
CM_ SG_ 1260 Byte0_TCP_4EC "Contents releted with Baidu Music";
CM_ SG_ 1260 Byte1_Data_4EC "Contents releted with Baidu Music";
CM_ SG_ 1260 Byte2_Data_4EC "Contents releted with Baidu Music";
CM_ SG_ 1260 Byte3_Data_4EC "Contents releted with Baidu Music";
CM_ SG_ 1260 Byte4_Data_4EC "Contents releted with Baidu Music";
CM_ SG_ 1260 Byte5_Data_4EC "Contents releted with Baidu Music";
CM_ SG_ 1260 Byte6_Data_4EC "Contents releted with Baidu Music";
CM_ SG_ 1260 Byte7_Data_4EC "Contents releted with Baidu Music";
CM_ BO_ 1270 "[TP] TP Message";
CM_ BO_ 1264 "[TP] TP Message";
CM_ BO_ 1266 "[TP] TP Message";
CM_ BO_ 1256 "[TP] TP Message";
CM_ SG_ 1256 Byte0_TCP_4E8 "TP from HU to CLU (FM Station Name)";
CM_ SG_ 1256 Byte1_Data_4E8 "TP from HU to CLU (FM Station Name)";
CM_ SG_ 1256 Byte2_Data_4E8 "TP from HU to CLU (FM Station Name)";
CM_ SG_ 1256 Byte3_Data_4E8 "TP from HU to CLU (FM Station Name)";
CM_ SG_ 1256 Byte4_Data_4E8 "TP from HU to CLU (FM Station Name)";
CM_ SG_ 1256 Byte5_Data_4E8 "TP from HU to CLU (FM Station Name)";
CM_ SG_ 1256 Byte6_Data_4E8 "TP from HU to CLU (FM Station Name)";
CM_ SG_ 1256 Byte7_Data_4E8 "TP from HU to CLU (FM Station Name)";
CM_ BO_ 1262 "[TP] TP Message";
CM_ BO_ 1262 "[TP] TP Message";
CM_ SG_ 1262 Byte0_TCP_4EE "Song Name, Artist, File Name, Play Time of iBox player";
CM_ SG_ 1262 Byte1_Data_4EE "Song Name, Artist, File Name, Play Time of iBox player";
CM_ SG_ 1262 Byte2_Data_4EE "Song Name, Artist, File Name, Play Time of iBox player";
CM_ SG_ 1262 Byte3_Data_4EE "Song Name, Artist, File Name, Play Time of iBox player";
CM_ SG_ 1262 Byte4_Data_4EE "Song Name, Artist, File Name, Play Time of iBox player";
CM_ SG_ 1262 Byte5_Data_4EE "Song Name, Artist, File Name, Play Time of iBox player";
CM_ SG_ 1262 Byte6_Data_4EE "Song Name, Artist, File Name, Play Time of iBox player";
CM_ SG_ 1262 Byte7_Data_4EE "Song Name, Artist, File Name, Play Time of iBox player";
CM_ BO_ 1254 "[TP] TP Message";
CM_ SG_ 1254 Byte0_TCP_4E6 "Contents related with Kaola FM";
CM_ SG_ 1254 Byte1_Data_4E6 "Contents related with Kaola FM";
CM_ SG_ 1254 Byte2_Data_4E6 "Contents related with Kaola FM";
CM_ SG_ 1254 Byte3_Data_4E6 "Contents related with Kaola FM";
CM_ SG_ 1254 Byte4_Data_4E6 "Contents related with Kaola FM";
CM_ SG_ 1254 Byte5_Data_4E6 "Contents related with Kaola FM";
CM_ SG_ 1254 Byte6_Data_4E6 "Contents related with Kaola FM";
CM_ SG_ 1254 Byte7_Data_4E6 "Contents related with Kaola FM";
BA_DEF_ SG_ "Gatewaysignal" ENUM "No","M-B","B-M","M-C","C-M","M-C-B" ;
BA_DEF_ SG_ "GenSigEnvVarType" ENUM "Int","Float","undef" ;
BA_DEF_ SG_ "GenSigSendType" ENUM "Cyclic","OnWrite","OnWriteWithRepetition","OnChange","OnChangeWithRepetition","IfActive","IfActiveWithRepetition","NoSigSendType" ;
BA_DEF_ SG_ "GenSigStartValue" INT 0 0 ;
BA_DEF_ SG_ "GwSigLatencyTime" INT 0 65535 ;
BA_DEF_ SG_ "GwSigMissingSourceType" ENUM "Undef","OldValue","DefaultValue","InitialValue" ;
BA_DEF_ SG_ "NmNetworkRequest" ENUM "No","Yes" ;
BA_DEF_ SG_ "NmNetworkRequestHoldingTime" INT 0 65535 ;
BA_DEF_ SG_ "Purpose" ENUM "<t.b.d.>","Function","Diagnostic","Development","NM" ;
BA_DEF_ SG_ "SignalCategory" HEX 10 15 ;
BA_DEF_ SG_ "TimeoutValue" STRING ;
BA_DEF_ SG_ "UpdateRateMax" INT 0 0 ;
BA_DEF_ SG_ "UpdateRateMin" INT 0 0 ;
BA_DEF_ SG_ "Validity" ENUM "B+","ACC","IGN1","IGN2" ;
BA_DEF_ BO_ "DiagRequest" ENUM "No","Yes" ;
BA_DEF_ BO_ "DiagResponse" ENUM "No","Yes" ;
BA_DEF_ BO_ "DiagState" ENUM "No","Yes" ;
BA_DEF_ BO_ "GenMsgCycleTime" INT 0 100000 ;
BA_DEF_ BO_ "GenMsgCycleTimeFast" INT 0 500 ;
BA_DEF_ BO_ "GenMsgDelayTime" INT 0 20 ;
BA_DEF_ BO_ "GenMsgEVName" STRING ;
BA_DEF_ BO_ "GenMsgILSupport" ENUM "No","Yes" ;
BA_DEF_ BO_ "GenMsgNrOfRepetition" INT 0 3 ;
BA_DEF_ BO_ "GenMsgSendType" ENUM "Cyclic","not_used","not_used","not_used","not_used","not_used","not_used","not_used","NoMsgSendType" ;
BA_DEF_ BO_ "GenMsgStartDelayTime" INT 0 2000 ;
BA_DEF_ BO_ "NmMessage" ENUM "No","Yes" ;
BA_DEF_ BO_ "RoutingType" ENUM "<n.a.>","Direct","Indirect" ;
BA_DEF_ BO_ "TpMessage" ENUM "No","Yes" ;
BA_DEF_ BO_ "TpTxIndex" INT 0 255 ;
BA_DEF_ BU_ "GenNodSleepTime" INT 1375 1650 ;
BA_DEF_ BU_ "ILUsed" ENUM "No","Yes" ;
BA_DEF_ BU_ "NmCAN" INT 1 2 ;
BA_DEF_ BU_ "NmNode" ENUM "No","Yes" ;
BA_DEF_ BU_ "NmStationAddress" HEX 0 255 ;
BA_DEF_ BU_ "NodeLayerModules" STRING ;
BA_DEF_ "Baudrate" INT 50000 500000 ;
BA_DEF_ "BusType" STRING ;
BA_DEF_ "GenEnvVarEndingDsp" STRING ;
BA_DEF_ "GenEnvVarEndingSnd" STRING ;
BA_DEF_ "GenEnvVarPrefix" STRING ;
BA_DEF_ "GenNWMApBusSleep" STRING ;
BA_DEF_ "GenNWMApCanNormal" STRING ;
BA_DEF_ "GenNWMApCanOff" STRING ;
BA_DEF_ "GenNWMApCanOn" STRING ;
BA_DEF_ "GenNWMApCanSleep" STRING ;
BA_DEF_ "GenNWMApCanWakeUp" STRING ;
BA_DEF_ "GenNWMGotoMode_Awake" STRING ;
BA_DEF_ "GenNWMGotoMode_BusSleep" STRING ;
BA_DEF_ "GenNWMSleepTime" INT 1375 1650 ;
BA_DEF_ "GenNWMTalkNM" STRING ;
BA_DEF_ "Manufacturer" STRING ;
BA_DEF_ "NmBaseAddress" HEX 0 2047 ;
BA_DEF_ "NmMessageCount" INT 0 128 ;
BA_DEF_ "NmType" STRING ;
BA_DEF_ "SamplePointMax" INT 50 85 ;
BA_DEF_ "SamplePointMin" INT 55 85 ;
BA_DEF_ "SyncJumpWidthMax" INT 1 8 ;
BA_DEF_ "SyncJumpWidthMin" INT 1 4 ;
BA_DEF_ "VersionDay" INT 1 31 ;
BA_DEF_ "VersionMonth" INT 1 12 ;
BA_DEF_ "VersionNumber" INT 0 999999 ;
BA_DEF_ "VersionWeek" INT 1 53 ;
BA_DEF_ "VersionYear" INT 0 9999 ;
BA_DEF_ SG_ "SigDescription" STRING ;
BA_DEF_ SG_ "Platform" STRING ;
BA_DEF_ SG_ "SigOldType" ENUM "No","Yes" ;
BA_DEF_REL_ BU_SG_REL_ "GenSigTimeoutTime" INT 0 7000 ;
BA_DEF_DEF_ "Gatewaysignal" "No" ;
BA_DEF_DEF_ "GenSigEnvVarType" "undef" ;
BA_DEF_DEF_ "GenSigSendType" "NoSigSendType" ;
BA_DEF_DEF_ "GenSigStartValue" 0 ;
BA_DEF_DEF_ "GwSigLatencyTime" 40 ;
BA_DEF_DEF_ "GwSigMissingSourceType" "Undef" ;
BA_DEF_DEF_ "NmNetworkRequest" "No" ;
BA_DEF_DEF_ "NmNetworkRequestHoldingTime" 0 ;
BA_DEF_DEF_ "Purpose" "<t.b.d.>" ;
BA_DEF_DEF_ "SignalCategory" 12 ;
BA_DEF_DEF_ "TimeoutValue" "" ;
BA_DEF_DEF_ "UpdateRateMax" 0 ;
BA_DEF_DEF_ "UpdateRateMin" 0 ;
BA_DEF_DEF_ "Validity" "ACC" ;
BA_DEF_DEF_ "DiagRequest" "No" ;
BA_DEF_DEF_ "DiagResponse" "No" ;
BA_DEF_DEF_ "DiagState" "No" ;
BA_DEF_DEF_ "GenMsgCycleTime" 0 ;
BA_DEF_DEF_ "GenMsgCycleTimeFast" 0 ;
BA_DEF_DEF_ "GenMsgDelayTime" 20 ;
BA_DEF_DEF_ "GenMsgEVName" "@Signame" ;
BA_DEF_DEF_ "GenMsgILSupport" "Yes" ;
BA_DEF_DEF_ "GenMsgNrOfRepetition" 0 ;
BA_DEF_DEF_ "GenMsgSendType" "NoMsgSendType" ;
BA_DEF_DEF_ "GenMsgStartDelayTime" 0 ;
BA_DEF_DEF_ "NmMessage" "No" ;
BA_DEF_DEF_ "RoutingType" "<n.a.>" ;
BA_DEF_DEF_ "TpMessage" "No" ;
BA_DEF_DEF_ "TpTxIndex" 0 ;
BA_DEF_DEF_ "GenNodSleepTime" 1500 ;
BA_DEF_DEF_ "ILUsed" "Yes" ;
BA_DEF_DEF_ "NmCAN" 1 ;
BA_DEF_DEF_ "NmNode" "Yes" ;
BA_DEF_DEF_ "NmStationAddress" 0 ;
BA_DEF_DEF_ "NodeLayerModules" "oseknm01.dll" ;
BA_DEF_DEF_ "Baudrate" 100000 ;
BA_DEF_DEF_ "BusType" "CAN" ;
BA_DEF_DEF_ "GenEnvVarEndingDsp" "Dsp_" ;
BA_DEF_DEF_ "GenEnvVarEndingSnd" "_" ;
BA_DEF_DEF_ "GenEnvVarPrefix" "Env" ;
BA_DEF_DEF_ "GenNWMApBusSleep" "ApplNmCanBusSleep()" ;
BA_DEF_DEF_ "GenNWMApCanNormal" "ApplNmCanNormal()" ;
BA_DEF_DEF_ "GenNWMApCanOff" "ApplCanOffline()" ;
BA_DEF_DEF_ "GenNWMApCanOn" "ApplCanOnline()" ;
BA_DEF_DEF_ "GenNWMApCanSleep" "ApplNmCanSleep()" ;
BA_DEF_DEF_ "GenNWMApCanWakeUp" "ApplCanWakeUp()" ;
BA_DEF_DEF_ "GenNWMGotoMode_Awake" "GotoMode_Awake()" ;
BA_DEF_DEF_ "GenNWMGotoMode_BusSleep" "GotoMode_BusSleep()" ;
BA_DEF_DEF_ "GenNWMSleepTime" 1500 ;
BA_DEF_DEF_ "GenNWMTalkNM" "TalkNM()" ;
BA_DEF_DEF_ "Manufacturer" "HMC" ;
BA_DEF_DEF_ "NmBaseAddress" 1024 ;
BA_DEF_DEF_ "NmMessageCount" 128 ;
BA_DEF_DEF_ "NmType" "Vector" ;
BA_DEF_DEF_ "SamplePointMax" 82 ;
BA_DEF_DEF_ "SamplePointMin" 75 ;
BA_DEF_DEF_ "SyncJumpWidthMax" 3 ;
BA_DEF_DEF_ "SyncJumpWidthMin" 2 ;
BA_DEF_DEF_ "VersionDay" 1 ;
BA_DEF_DEF_ "VersionMonth" 1 ;
BA_DEF_DEF_ "VersionNumber" 0 ;
BA_DEF_DEF_ "VersionWeek" 1 ;
BA_DEF_DEF_ "VersionYear" 2010 ;
BA_DEF_DEF_ "SigDescription" "" ;
BA_DEF_DEF_ "Platform" "Standard AVN 4.0,Standard Audio 3.0,Premium AVN 3.0" ;
BA_DEF_DEF_ "SigOldType" "No" ;
BA_DEF_DEF_REL_ "GenSigTimeoutTime" 700 ;
BA_ "VersionNumber" 180801;
BA_ "NmStationAddress" BU_ CGW 85;
BA_ "GenMsgSendType" BO_ 305 0;
BA_ "GenMsgCycleTime" BO_ 305 1000;
BA_ "GenMsgStartDelayTime" BO_ 305 480;
BA_ "NmStationAddress" BU_ H_U 64;
BA_REL_ "GenSigTimeoutTime" BU_SG_REL_ H_U SG_ 305 DATC_DrTempDispC 3500;
BA_ "SigDescription" SG_ 305 DATC_DrTempDispC "1. OLD Temp Display Ragne
 - KR/US/ME/CH
 (PHY MIN: 17.0, PHY MAX: 32.0)
 - EU :(PHY MIN: 15.0, PHY MAX: 30.0)
2. NEW Temp Display Ragne
- All Region :(PHY MIN: 15.0, PHY MAX: 32.0)";
BA_ "Platform" SG_ 305 DATC_DrTempDispC "";
BA_ "GenSigSendType" SG_ 305 DATC_DrTempDispC 3;
BA_ "GenSigStartValue" SG_ 305 DATC_DrTempDispC 255;
BA_ "Gatewaysignal" SG_ 305 DATC_DrTempDispC 4;
BA_ "SignalCategory" SG_ 305 DATC_DrTempDispC 13;
BA_ "TimeoutValue" SG_ 305 DATC_DrTempDispC "Old Value";
BA_ "Validity" SG_ 305 DATC_DrTempDispC 2;
BA_REL_ "GenSigTimeoutTime" BU_SG_REL_ H_U SG_ 305 DATC_DrTempDispF 3500;
BA_ "SigDescription" SG_ 305 DATC_DrTempDispF "1. OLD Temp Display Ragne
KR/US/ME/CH :(PHY MIN: 62, PHY MAX: 90)
EU :(PHY MIN: 60, PHY MAX: 88)
2. NEW Temp Display Ragne
- All Region :(PHY MIN: 58, PHY MAX: 92)";
BA_ "Platform" SG_ 305 DATC_DrTempDispF "";
BA_ "GenSigSendType" SG_ 305 DATC_DrTempDispF 3;
BA_ "GenSigStartValue" SG_ 305 DATC_DrTempDispF 255;
BA_ "Gatewaysignal" SG_ 305 DATC_DrTempDispF 4;
BA_ "SignalCategory" SG_ 305 DATC_DrTempDispF 13;
BA_ "TimeoutValue" SG_ 305 DATC_DrTempDispF "Old Value";
BA_ "Validity" SG_ 305 DATC_DrTempDispF 2;
BA_ "GenMsgSendType" BO_ 306 0;
BA_ "GenMsgCycleTime" BO_ 306 1000;
BA_ "GenMsgStartDelayTime" BO_ 306 470;
BA_REL_ "GenSigTimeoutTime" BU_SG_REL_ H_U SG_ 306 DATC_ModeDisp 3500;
BA_ "SigDescription" SG_ 306 DATC_ModeDisp "Basic Modes
- Defog : Defog
- Vent : Upper
- Def : Middle
- Floor : Lower

Mixed Modes
- Auto Defog : Defog + Auto 
- Max Defog : Defog + Seat

* Compatabilityfor old value table 
- Vent/Floor : same with old B/L 
- Defog/Floor : same with old MIX 
- Max Defog : same with old DEF";
BA_ "Platform" SG_ 306 DATC_ModeDisp "";
BA_ "GenSigSendType" SG_ 306 DATC_ModeDisp 3;
BA_ "GenSigStartValue" SG_ 306 DATC_ModeDisp 15;
BA_ "SignalCategory" SG_ 306 DATC_ModeDisp 13;
BA_ "TimeoutValue" SG_ 306 DATC_ModeDisp "Old Value";
BA_ "Validity" SG_ 306 DATC_ModeDisp 2;
BA_REL_ "GenSigTimeoutTime" BU_SG_REL_ H_U SG_ 306 DATC_TempUnit 3500;
BA_ "Platform" SG_ 306 DATC_TempUnit "";
BA_ "GenSigSendType" SG_ 306 DATC_TempUnit 3;
BA_ "GenSigStartValue" SG_ 306 DATC_TempUnit 3;
BA_ "SignalCategory" SG_ 306 DATC_TempUnit 13;
BA_ "TimeoutValue" SG_ 306 DATC_TempUnit "Old Value";
BA_ "Validity" SG_ 306 DATC_TempUnit 2;
BA_REL_ "GenSigTimeoutTime" BU_SG_REL_ H_U SG_ 306 DATC_AirCleaningSystemStatus 1000;
BA_ "Platform" SG_ 306 DATC_AirCleaningSystemStatus "";
BA_ "GenSigSendType" SG_ 306 DATC_AirCleaningSystemStatus 3;
BA_ "GenSigStartValue" SG_ 306 DATC_AirCleaningSystemStatus 3;
BA_ "Gatewaysignal" SG_ 306 DATC_AirCleaningSystemStatus 4;
BA_ "Validity" SG_ 306 DATC_AirCleaningSystemStatus 2;
BA_REL_ "GenSigTimeoutTime" BU_SG_REL_ H_U SG_ 306 DATC_AutoDisp 3500;
BA_ "Platform" SG_ 306 DATC_AutoDisp "";
BA_ "GenSigSendType" SG_ 306 DATC_AutoDisp 3;
BA_ "GenSigStartValue" SG_ 306 DATC_AutoDisp 3;
BA_ "SignalCategory" SG_ 306 DATC_AutoDisp 13;
BA_ "TimeoutValue" SG_ 306 DATC_AutoDisp "Old Value";
BA_ "Validity" SG_ 306 DATC_AutoDisp 2;
BA_REL_ "GenSigTimeoutTime" BU_SG_REL_ H_U SG_ 306 DATC_IntakeDisp 3500;
BA_ "Platform" SG_ 306 DATC_IntakeDisp "";
BA_ "GenSigSendType" SG_ 306 DATC_IntakeDisp 3;
BA_ "GenSigStartValue" SG_ 306 DATC_IntakeDisp 3;
BA_ "SignalCategory" SG_ 306 DATC_IntakeDisp 13;
BA_ "TimeoutValue" SG_ 306 DATC_IntakeDisp "Old Value";
BA_ "Validity" SG_ 306 DATC_IntakeDisp 2;
BA_REL_ "GenSigTimeoutTime" BU_SG_REL_ H_U SG_ 306 DATC_AcDisp 3500;
BA_ "Platform" SG_ 306 DATC_AcDisp "";
BA_ "GenSigSendType" SG_ 306 DATC_AcDisp 3;
BA_ "GenSigStartValue" SG_ 306 DATC_AcDisp 3;
BA_ "SignalCategory" SG_ 306 DATC_AcDisp 13;
BA_ "TimeoutValue" SG_ 306 DATC_AcDisp "Old Value";
BA_ "Validity" SG_ 306 DATC_AcDisp 2;
BA_REL_ "GenSigTimeoutTime" BU_SG_REL_ H_U SG_ 306 DATC_OpSts 3500;
BA_ "Platform" SG_ 306 DATC_OpSts "";
BA_ "GenSigSendType" SG_ 306 DATC_OpSts 3;
BA_ "GenSigStartValue" SG_ 306 DATC_OpSts 7;
BA_ "SignalCategory" SG_ 306 DATC_OpSts 13;
BA_ "TimeoutValue" SG_ 306 DATC_OpSts "Old Value";
BA_ "Validity" SG_ 306 DATC_OpSts 2;
BA_REL_ "GenSigTimeoutTime" BU_SG_REL_ H_U SG_ 306 DATC_FrDefLed 3500;
BA_ "Platform" SG_ 306 DATC_FrDefLed "";
BA_ "GenSigSendType" SG_ 306 DATC_FrDefLed 3;
BA_ "GenSigStartValue" SG_ 306 DATC_FrDefLed 3;
BA_ "SignalCategory" SG_ 306 DATC_FrDefLed 13;
BA_ "TimeoutValue" SG_ 306 DATC_FrDefLed "Old Value";
BA_ "Validity" SG_ 306 DATC_FrDefLed 2;
BA_REL_ "GenSigTimeoutTime" BU_SG_REL_ H_U SG_ 306 DATC_MainBlowerDisp 3500;
BA_ "Platform" SG_ 306 DATC_MainBlowerDisp "";
BA_ "GenSigSendType" SG_ 306 DATC_MainBlowerDisp 3;
BA_ "GenSigStartValue" SG_ 306 DATC_MainBlowerDisp 15;
BA_ "SignalCategory" SG_ 306 DATC_MainBlowerDisp 13;
BA_ "TimeoutValue" SG_ 306 DATC_MainBlowerDisp "Old Value";
BA_ "Validity" SG_ 306 DATC_MainBlowerDisp 2;
BA_ "GenMsgSendType" BO_ 307 0;
BA_ "GenMsgCycleTime" BO_ 307 200;
BA_ "GenMsgStartDelayTime" BO_ 307 160;
BA_REL_ "GenSigTimeoutTime" BU_SG_REL_ H_U SG_ 307 DATC_SelfDiagDisp 3500;
BA_ "Platform" SG_ 307 DATC_SelfDiagDisp "";
BA_ "GenSigSendType" SG_ 307 DATC_SelfDiagDisp 3;
BA_ "GenSigStartValue" SG_ 307 DATC_SelfDiagDisp 255;
BA_ "TimeoutValue" SG_ 307 DATC_SelfDiagDisp "Old Value";
BA_ "Validity" SG_ 307 DATC_SelfDiagDisp 2;
BA_REL_ "GenSigTimeoutTime" BU_SG_REL_ H_U SG_ 307 DATC_Variant 3500;
BA_ "SigDescription" SG_ 307 DATC_Variant "Bit0 (FR CTRL) : 0 - ATC / 1 - MTC
Bit1~2 (Temp) : 00 - Single / 01 - Dual / 10 - 3 Zone / 11 - 4 Zone
Bit3~4 (Mode) : 00 - Single / 01 - Dual / 10 - 3 Zone / 11 - 4 Zone 
Bit5 (Rear Control) : 0 - (None or MTC) / 1 - ATC
Bit6 (RHD) : 0 - LHD / 1 - RHD
Bit7 (EU) : 0 - Others / 1 - EU

*Harman AMP uses this signal for LHD/RHD information (JS Only)";
BA_ "Platform" SG_ 307 DATC_Variant "";
BA_ "GenSigSendType" SG_ 307 DATC_Variant 3;
BA_ "GenSigStartValue" SG_ 307 DATC_Variant 255;
BA_ "SignalCategory" SG_ 307 DATC_Variant 13;
BA_ "TimeoutValue" SG_ 307 DATC_Variant "Old Value";
BA_ "Validity" SG_ 307 DATC_Variant 2;
BA_ "GenMsgSendType" BO_ 309 0;
BA_ "GenMsgCycleTime" BO_ 309 200;
BA_ "GenMsgStartDelayTime" BO_ 309 110;
BA_ "Platform" SG_ 309 CF_DATC_TempDisp_Sts "Integrated AVN1.0 High,Integrated AVN1.0 Mid,Premium AVN 2.0";
BA_ "GenSigSendType" SG_ 309 CF_DATC_TempDisp_Sts 3;
BA_ "TimeoutValue" SG_ 309 CF_DATC_TempDisp_Sts "Invalid";
BA_ "Validity" SG_ 309 CF_DATC_TempDisp_Sts 2;
BA_REL_ "GenSigTimeoutTime" BU_SG_REL_ H_U SG_ 309 CF_Datc_Option1 1000;
BA_ "SigDescription" SG_ 309 CF_Datc_Option1 "Option of HEATER SYSTEM";
BA_ "Platform" SG_ 309 CF_Datc_Option1 "";
BA_ "GenSigSendType" SG_ 309 CF_Datc_Option1 3;
BA_ "GenSigStartValue" SG_ 309 CF_Datc_Option1 255;
BA_ "Gatewaysignal" SG_ 309 CF_Datc_Option1 4;
BA_ "TimeoutValue" SG_ 309 CF_Datc_Option1 "invalid";
BA_ "Validity" SG_ 309 CF_Datc_Option1 2;
BA_REL_ "GenSigTimeoutTime" BU_SG_REL_ H_U SG_ 309 CF_Datc_Option2 1000;
BA_ "SigDescription" SG_ 309 CF_Datc_Option2 "Option of HEATER SYSTEM";
BA_ "Platform" SG_ 309 CF_Datc_Option2 "";
BA_ "GenSigSendType" SG_ 309 CF_Datc_Option2 3;
BA_ "GenSigStartValue" SG_ 309 CF_Datc_Option2 255;
BA_ "Gatewaysignal" SG_ 309 CF_Datc_Option2 4;
BA_ "TimeoutValue" SG_ 309 CF_Datc_Option2 "invalid";
BA_ "Validity" SG_ 309 CF_Datc_Option2 2;
BA_REL_ "GenSigTimeoutTime" BU_SG_REL_ H_U SG_ 164 C_SMK_Encrypted_Result1 0;
BA_ "Platform" SG_ 164 C_SMK_Encrypted_Result1 "";
BA_ "GenSigSendType" SG_ 164 C_SMK_Encrypted_Result1 3;
BA_ "Gatewaysignal" SG_ 164 C_SMK_Encrypted_Result1 2;
BA_ "Validity" SG_ 164 C_SMK_Encrypted_Result1 0;
BA_REL_ "GenSigTimeoutTime" BU_SG_REL_ H_U SG_ 165 C_SMK_Encrypted_Result2 0;
BA_ "Platform" SG_ 165 C_SMK_Encrypted_Result2 "";
BA_ "GenSigSendType" SG_ 165 C_SMK_Encrypted_Result2 3;
BA_ "Gatewaysignal" SG_ 165 C_SMK_Encrypted_Result2 2;
BA_ "Validity" SG_ 165 C_SMK_Encrypted_Result2 0;
BA_REL_ "GenSigTimeoutTime" BU_SG_REL_ H_U SG_ 166 C_SMK_AuthReq 0;
BA_ "Platform" SG_ 166 C_SMK_AuthReq "";
BA_ "GenSigSendType" SG_ 166 C_SMK_AuthReq 3;
BA_ "Gatewaysignal" SG_ 166 C_SMK_AuthReq 2;
BA_ "Validity" SG_ 166 C_SMK_AuthReq 0;
BA_REL_ "GenSigTimeoutTime" BU_SG_REL_ H_U SG_ 166 C_SMK_Random 0;
BA_ "Platform" SG_ 166 C_SMK_Random "";
BA_ "GenSigSendType" SG_ 166 C_SMK_Random 3;
BA_ "Gatewaysignal" SG_ 166 C_SMK_Random 2;
BA_ "Validity" SG_ 166 C_SMK_Random 0;
BA_REL_ "GenSigTimeoutTime" BU_SG_REL_ H_U SG_ 167 C_PassiveAccessLock 0;
BA_ "Platform" SG_ 167 C_PassiveAccessLock "";
BA_ "GenSigSendType" SG_ 167 C_PassiveAccessLock 3;
BA_ "Gatewaysignal" SG_ 167 C_PassiveAccessLock 2;
BA_ "Validity" SG_ 167 C_PassiveAccessLock 0;
BA_REL_ "GenSigTimeoutTime" BU_SG_REL_ H_U SG_ 167 C_PassiveAccessUnlock 0;
BA_ "Platform" SG_ 167 C_PassiveAccessUnlock "";
BA_ "GenSigSendType" SG_ 167 C_PassiveAccessUnlock 3;
BA_ "Gatewaysignal" SG_ 167 C_PassiveAccessUnlock 2;
BA_ "Validity" SG_ 167 C_PassiveAccessUnlock 0;
BA_REL_ "GenSigTimeoutTime" BU_SG_REL_ H_U SG_ 167 C_SMK_AuthMethod 0;
BA_ "Platform" SG_ 167 C_SMK_AuthMethod "";
BA_ "GenSigSendType" SG_ 167 C_SMK_AuthMethod 3;
BA_ "Gatewaysignal" SG_ 167 C_SMK_AuthMethod 2;
BA_ "Validity" SG_ 167 C_SMK_AuthMethod 0;
BA_REL_ "GenSigTimeoutTime" BU_SG_REL_ H_U SG_ 167 C_IBUISKLearnFB 0;
BA_ "Platform" SG_ 167 C_IBUISKLearnFB "";
BA_ "GenSigSendType" SG_ 167 C_IBUISKLearnFB 3;
BA_ "Gatewaysignal" SG_ 167 C_IBUISKLearnFB 2;
BA_ "Validity" SG_ 167 C_IBUISKLearnFB 0;
BA_ "GenMsgSendType" BO_ 402 0;
BA_ "GenMsgCycleTime" BO_ 402 200;
BA_ "GenMsgStartDelayTime" BO_ 402 130;
BA_REL_ "GenSigTimeoutTime" BU_SG_REL_ H_U SG_ 402 C_AuthState 750;
BA_ "Platform" SG_ 402 C_AuthState "";
BA_ "GenSigSendType" SG_ 402 C_AuthState 3;
BA_ "Gatewaysignal" SG_ 402 C_AuthState 2;
BA_ "TimeoutValue" SG_ 402 C_AuthState "0x0";
BA_ "Validity" SG_ 402 C_AuthState 0;
BA_REL_ "GenSigTimeoutTime" BU_SG_REL_ H_U SG_ 402 C_IBUISKLearnState 750;
BA_ "Platform" SG_ 402 C_IBUISKLearnState "";
BA_ "GenSigSendType" SG_ 402 C_IBUISKLearnState 3;
BA_ "Gatewaysignal" SG_ 402 C_IBUISKLearnState 2;
BA_ "TimeoutValue" SG_ 402 C_IBUISKLearnState "0x2";
BA_ "Validity" SG_ 402 C_IBUISKLearnState 0;
BA_REL_ "GenSigTimeoutTime" BU_SG_REL_ H_U SG_ 402 C_SMKBLECrankingState 750;
BA_ "Platform" SG_ 402 C_SMKBLECrankingState "";
BA_ "GenSigSendType" SG_ 402 C_SMKBLECrankingState 3;
BA_ "Gatewaysignal" SG_ 402 C_SMKBLECrankingState 2;
BA_ "TimeoutValue" SG_ 402 C_SMKBLECrankingState "0x0";
BA_ "Validity" SG_ 402 C_SMKBLECrankingState 0;
BA_REL_ "GenSigTimeoutTime" BU_SG_REL_ H_U SG_ 402 C_SMKBLEEngineRunning 750;
BA_ "Platform" SG_ 402 C_SMKBLEEngineRunning "";
BA_ "GenSigSendType" SG_ 402 C_SMKBLEEngineRunning 3;
BA_ "Gatewaysignal" SG_ 402 C_SMKBLEEngineRunning 2;
BA_ "TimeoutValue" SG_ 402 C_SMKBLEEngineRunning "0x0";
BA_ "Validity" SG_ 402 C_SMKBLEEngineRunning 0;
BA_REL_ "GenSigTimeoutTime" BU_SG_REL_ H_U SG_ 402 C_AstToggleButton 750;
BA_ "Platform" SG_ 402 C_AstToggleButton "";
BA_ "GenSigSendType" SG_ 402 C_AstToggleButton 3;
BA_ "Gatewaysignal" SG_ 402 C_AstToggleButton 2;
BA_ "TimeoutValue" SG_ 402 C_AstToggleButton "0x0";
BA_ "Validity" SG_ 402 C_AstToggleButton 0;
BA_REL_ "GenSigTimeoutTime" BU_SG_REL_ H_U SG_ 402 C_DrvToggleButton 750;
BA_ "Platform" SG_ 402 C_DrvToggleButton "";
BA_ "GenSigSendType" SG_ 402 C_DrvToggleButton 3;
BA_ "Gatewaysignal" SG_ 402 C_DrvToggleButton 2;
BA_ "TimeoutValue" SG_ 402 C_DrvToggleButton "0x0";
BA_ "Validity" SG_ 402 C_DrvToggleButton 0;
BA_REL_ "GenSigTimeoutTime" BU_SG_REL_ H_U SG_ 402 C_BrakeSW 750;
BA_ "Platform" SG_ 402 C_BrakeSW "";
BA_ "GenSigSendType" SG_ 402 C_BrakeSW 3;
BA_ "Gatewaysignal" SG_ 402 C_BrakeSW 2;
BA_ "TimeoutValue" SG_ 402 C_BrakeSW "0x0";
BA_ "Validity" SG_ 402 C_BrakeSW 0;
BA_REL_ "GenSigTimeoutTime" BU_SG_REL_ H_U SG_ 402 C_SSBSW1 750;
BA_ "Platform" SG_ 402 C_SSBSW1 "";
BA_ "GenSigSendType" SG_ 402 C_SSBSW1 3;
BA_ "TimeoutValue" SG_ 402 C_SSBSW1 "0x0";
BA_ "Validity" SG_ 402 C_SSBSW1 0;
BA_REL_ "GenSigTimeoutTime" BU_SG_REL_ H_U SG_ 402 C_SSBSW2 750;
BA_ "Platform" SG_ 402 C_SSBSW2 "";
BA_ "GenSigSendType" SG_ 402 C_SSBSW2 3;
BA_ "Gatewaysignal" SG_ 402 C_SSBSW2 2;
BA_ "TimeoutValue" SG_ 402 C_SSBSW2 "0x0";
BA_ "Validity" SG_ 402 C_SSBSW2 0;
BA_REL_ "GenSigTimeoutTime" BU_SG_REL_ H_U SG_ 402 C_TrunkTgOtrReleaseSW 750;
BA_ "Platform" SG_ 402 C_TrunkTgOtrReleaseSW "";
BA_ "GenSigSendType" SG_ 402 C_TrunkTgOtrReleaseSW 3;
BA_ "Gatewaysignal" SG_ 402 C_TrunkTgOtrReleaseSW 2;
BA_ "TimeoutValue" SG_ 402 C_TrunkTgOtrReleaseSW "0x0";
BA_ "Validity" SG_ 402 C_TrunkTgOtrReleaseSW 0;
BA_REL_ "GenSigTimeoutTime" BU_SG_REL_ H_U SG_ 402 C_TerminalsManagerState 750;
BA_ "Platform" SG_ 402 C_TerminalsManagerState "";
BA_ "GenSigSendType" SG_ 402 C_TerminalsManagerState 3;
BA_ "Gatewaysignal" SG_ 402 C_TerminalsManagerState 2;
BA_ "TimeoutValue" SG_ 402 C_TerminalsManagerState "Old Value";
BA_ "Validity" SG_ 402 C_TerminalsManagerState 0;
BA_ "GenMsgSendType" BO_ 1390 0;
BA_ "GenMsgCycleTime" BO_ 1390 200;
BA_ "GenMsgStartDelayTime" BO_ 1390 110;
BA_ "Platform" SG_ 1390 C_VehicleSpeed "";
BA_ "GenSigStartValue" SG_ 1390 C_VehicleSpeed 255;
BA_ "Gatewaysignal" SG_ 1390 C_VehicleSpeed 4;
BA_ "SignalCategory" SG_ 1390 C_VehicleSpeed 13;
BA_ "TimeoutValue" SG_ 1390 C_VehicleSpeed "Old Value";
BA_ "Validity" SG_ 1390 C_VehicleSpeed 2;
BA_ "Platform" SG_ 1390 C_Odometer "";
BA_ "GenSigStartValue" SG_ 1390 C_Odometer 16777215;
BA_ "Gatewaysignal" SG_ 1390 C_Odometer 4;
BA_ "SignalCategory" SG_ 1390 C_Odometer 13;
BA_ "TimeoutValue" SG_ 1390 C_Odometer "Old Value";
BA_ "Validity" SG_ 1390 C_Odometer 2;
BA_ "Platform" SG_ 1390 CF_Clu_SPEED_UNIT "Compact AVN,DIS 2,Integrated AVN1.0 High,Integrated AVN1.0 Mid,Premium AVN 2.0,Standard AVN 4.0";
BA_ "GenSigStartValue" SG_ 1390 CF_Clu_SPEED_UNIT 3;
BA_ "Validity" SG_ 1390 CF_Clu_SPEED_UNIT 2;
BA_ "Platform" SG_ 1390 CF_Clu_Vanz "Compact AVN,DIS 2,Integrated AVN1.0 High,Integrated AVN1.0 Mid,Premium AVN 2.0,Standard AVN 4.0";
BA_ "GenSigStartValue" SG_ 1390 CF_Clu_Vanz 511;
BA_ "Validity" SG_ 1390 CF_Clu_Vanz 2;
BA_ "Purpose" SG_ 1390 CF_Clu_DisplaySpeed 1;
BA_ "Platform" SG_ 1390 CF_Clu_DisplaySpeed "";
BA_ "Gatewaysignal" SG_ 1390 CF_Clu_DisplaySpeed 4;
BA_ "TimeoutValue" SG_ 1390 CF_Clu_DisplaySpeed "0x1FF";
BA_ "Validity" SG_ 1390 CF_Clu_DisplaySpeed 2;
BA_ "NmStationAddress" BU_ CLU 77;
BA_ "GenMsgSendType" BO_ 413 0;
BA_ "GenMsgCycleTime" BO_ 413 200;
BA_ "GenMsgStartDelayTime" BO_ 413 160;
BA_ "Platform" SG_ 413 C_TSigLhSw "";
BA_ "GenSigSendType" SG_ 413 C_TSigLhSw 3;
BA_ "GenSigStartValue" SG_ 413 C_TSigLhSw 3;
BA_ "Gatewaysignal" SG_ 413 C_TSigLhSw 2;
BA_ "Platform" SG_ 413 C_TSigRhSw "";
BA_ "GenSigSendType" SG_ 413 C_TSigRhSw 3;
BA_ "GenSigStartValue" SG_ 413 C_TSigRhSw 3;
BA_ "Gatewaysignal" SG_ 413 C_TSigRhSw 2;
BA_ "GenMsgSendType" BO_ 414 0;
BA_ "GenMsgCycleTime" BO_ 414 200;
BA_ "GenMsgStartDelayTime" BO_ 414 130;
BA_REL_ "GenSigTimeoutTime" BU_SG_REL_ H_U SG_ 414 C_DrvSeatHeatOption 750;
BA_ "SigDescription" SG_ 414 C_DrvSeatHeatOption "Use for telematics service";
BA_ "Platform" SG_ 414 C_DrvSeatHeatOption "";
BA_ "GenSigSendType" SG_ 414 C_DrvSeatHeatOption 3;
BA_ "TimeoutValue" SG_ 414 C_DrvSeatHeatOption "0x7";
BA_ "Validity" SG_ 414 C_DrvSeatHeatOption 2;
BA_REL_ "GenSigTimeoutTime" BU_SG_REL_ H_U SG_ 414 C_DrvSeatHeatState 750;
BA_ "SigDescription" SG_ 414 C_DrvSeatHeatState "Use for telematics service";
BA_ "Platform" SG_ 414 C_DrvSeatHeatState "";
BA_ "GenSigSendType" SG_ 414 C_DrvSeatHeatState 3;
BA_ "TimeoutValue" SG_ 414 C_DrvSeatHeatState "0xF";
BA_ "Validity" SG_ 414 C_DrvSeatHeatState 2;
BA_REL_ "GenSigTimeoutTime" BU_SG_REL_ H_U SG_ 414 C_AstSeatHeatOption 750;
BA_ "SigDescription" SG_ 414 C_AstSeatHeatOption "Use for telematics service";
BA_ "Platform" SG_ 414 C_AstSeatHeatOption "";
BA_ "GenSigSendType" SG_ 414 C_AstSeatHeatOption 3;
BA_ "TimeoutValue" SG_ 414 C_AstSeatHeatOption "0x7";
BA_ "Validity" SG_ 414 C_AstSeatHeatOption 2;
BA_REL_ "GenSigTimeoutTime" BU_SG_REL_ H_U SG_ 414 C_AstSeatHeatState 750;
BA_ "SigDescription" SG_ 414 C_AstSeatHeatState "Use for telematics service";
BA_ "Platform" SG_ 414 C_AstSeatHeatState "";
BA_ "GenSigSendType" SG_ 414 C_AstSeatHeatState 3;
BA_ "TimeoutValue" SG_ 414 C_AstSeatHeatState "0xF";
BA_ "Validity" SG_ 414 C_AstSeatHeatState 2;
BA_ "GenMsgSendType" BO_ 415 0;
BA_ "GenMsgCycleTime" BO_ 415 1000;
BA_ "GenMsgStartDelayTime" BO_ 415 10;
BA_REL_ "GenSigTimeoutTime" BU_SG_REL_ H_U SG_ 415 Batt_SoCWarningAlertMsgReq 2500;
BA_ "Platform" SG_ 415 Batt_SoCWarningAlertMsgReq "";
BA_ "GenSigSendType" SG_ 415 Batt_SoCWarningAlertMsgReq 3;
BA_ "GenSigStartValue" SG_ 415 Batt_SoCWarningAlertMsgReq 3;
BA_ "TimeoutValue" SG_ 415 Batt_SoCWarningAlertMsgReq "Old Value";
BA_ "Validity" SG_ 415 Batt_SoCWarningAlertMsgReq 0;
BA_ "Purpose" SG_ 415 Batt_SoC 1;
BA_REL_ "GenSigTimeoutTime" BU_SG_REL_ H_U SG_ 415 Batt_SoC 2500;
BA_ "SigDescription" SG_ 415 Batt_SoC "This signal is Battery SOC from battery sensor.";
BA_ "Platform" SG_ 415 Batt_SoC "";
BA_ "GenSigSendType" SG_ 415 Batt_SoC 3;
BA_ "GenSigStartValue" SG_ 415 Batt_SoC 255;
BA_ "TimeoutValue" SG_ 415 Batt_SoC "Old Value";
BA_ "Validity" SG_ 415 Batt_SoC 0;
BA_ "Purpose" SG_ 415 ICUPowerAutoCutMode 1;
BA_REL_ "GenSigTimeoutTime" BU_SG_REL_ H_U SG_ 415 ICUPowerAutoCutMode 2500;
BA_ "Platform" SG_ 415 ICUPowerAutoCutMode "";
BA_ "GenSigSendType" SG_ 415 ICUPowerAutoCutMode 3;
BA_ "GenSigStartValue" SG_ 415 ICUPowerAutoCutMode 3;
BA_ "TimeoutValue" SG_ 415 ICUPowerAutoCutMode "Old Value";
BA_ "Validity" SG_ 415 ICUPowerAutoCutMode 0;
BA_ "Purpose" SG_ 415 Batt_SoCAlertValue 1;
BA_REL_ "GenSigTimeoutTime" BU_SG_REL_ H_U SG_ 415 Batt_SoCAlertValue 2500;
BA_ "SigDescription" SG_ 415 Batt_SoCAlertValue "This signal is Battery SOC from battery sensor.";
BA_ "Platform" SG_ 415 Batt_SoCAlertValue "";
BA_ "GenSigSendType" SG_ 415 Batt_SoCAlertValue 3;
BA_ "GenSigStartValue" SG_ 415 Batt_SoCAlertValue 255;
BA_ "TimeoutValue" SG_ 415 Batt_SoCAlertValue "Old Value";
BA_ "Validity" SG_ 415 Batt_SoCAlertValue 0;
BA_ "GenMsgSendType" BO_ 294 0;
BA_ "GenMsgCycleTime" BO_ 294 600;
BA_ "GenMsgStartDelayTime" BO_ 294 100;
BA_REL_ "GenSigTimeoutTime" BU_SG_REL_ H_U SG_ 294 CAM_Status 2100;
BA_ "SigDescription" SG_ 294 CAM_Status "This signal is used for AHD(Analog High Definition) camera function, and this function is only used on China OEM platform.";
BA_ "Platform" SG_ 294 CAM_Status "";
BA_ "GenSigSendType" SG_ 294 CAM_Status 3;
BA_ "Gatewaysignal" SG_ 294 CAM_Status 4;
BA_ "TimeoutValue" SG_ 294 CAM_Status "Old Value";
BA_ "Validity" SG_ 294 CAM_Status 2;
BA_ "DiagState" BO_ 2015 1;
BA_ "GenMsgILSupport" BO_ 2015 0;
BA_ "TpMessage" BO_ 2015 1;
BA_REL_ "GenSigTimeoutTime" BU_SG_REL_ CLU SG_ 2015 Byte0_TCP_7DF 0;
BA_REL_ "GenSigTimeoutTime" BU_SG_REL_ H_U SG_ 2015 Byte0_TCP_7DF 0;
BA_ "Platform" SG_ 2015 Byte0_TCP_7DF "";
BA_ "DiagState" BO_ 2015 1;
BA_ "GenMsgILSupport" BO_ 2015 0;
BA_ "TpMessage" BO_ 2015 1;
BA_REL_ "GenSigTimeoutTime" BU_SG_REL_ CLU SG_ 2015 Byte1_Data_7DF 0;
BA_REL_ "GenSigTimeoutTime" BU_SG_REL_ H_U SG_ 2015 Byte1_Data_7DF 0;
BA_ "Platform" SG_ 2015 Byte1_Data_7DF "";
BA_ "DiagState" BO_ 2015 1;
BA_ "GenMsgILSupport" BO_ 2015 0;
BA_ "TpMessage" BO_ 2015 1;
BA_REL_ "GenSigTimeoutTime" BU_SG_REL_ CLU SG_ 2015 Byte2_Data_7DF 0;
BA_REL_ "GenSigTimeoutTime" BU_SG_REL_ H_U SG_ 2015 Byte2_Data_7DF 0;
BA_ "Platform" SG_ 2015 Byte2_Data_7DF "";
BA_ "DiagState" BO_ 2015 1;
BA_ "GenMsgILSupport" BO_ 2015 0;
BA_ "TpMessage" BO_ 2015 1;
BA_REL_ "GenSigTimeoutTime" BU_SG_REL_ CLU SG_ 2015 Byte3_Data_7DF 0;
BA_REL_ "GenSigTimeoutTime" BU_SG_REL_ H_U SG_ 2015 Byte3_Data_7DF 0;
BA_ "Platform" SG_ 2015 Byte3_Data_7DF "";
BA_ "DiagState" BO_ 2015 1;
BA_ "GenMsgILSupport" BO_ 2015 0;
BA_ "TpMessage" BO_ 2015 1;
BA_REL_ "GenSigTimeoutTime" BU_SG_REL_ CLU SG_ 2015 Byte4_Data_7DF 0;
BA_REL_ "GenSigTimeoutTime" BU_SG_REL_ H_U SG_ 2015 Byte4_Data_7DF 0;
BA_ "Platform" SG_ 2015 Byte4_Data_7DF "";
BA_ "DiagState" BO_ 2015 1;
BA_ "GenMsgILSupport" BO_ 2015 0;
BA_ "TpMessage" BO_ 2015 1;
BA_REL_ "GenSigTimeoutTime" BU_SG_REL_ CLU SG_ 2015 Byte5_Data_7DF 0;
BA_REL_ "GenSigTimeoutTime" BU_SG_REL_ H_U SG_ 2015 Byte5_Data_7DF 0;
BA_ "Platform" SG_ 2015 Byte5_Data_7DF "";
BA_ "DiagState" BO_ 2015 1;
BA_ "GenMsgILSupport" BO_ 2015 0;
BA_ "TpMessage" BO_ 2015 1;
BA_REL_ "GenSigTimeoutTime" BU_SG_REL_ CLU SG_ 2015 Byte6_Data_7DF 0;
BA_REL_ "GenSigTimeoutTime" BU_SG_REL_ H_U SG_ 2015 Byte6_Data_7DF 0;
BA_ "Platform" SG_ 2015 Byte6_Data_7DF "";
BA_ "DiagState" BO_ 2015 1;
BA_ "GenMsgILSupport" BO_ 2015 0;
BA_ "TpMessage" BO_ 2015 1;
BA_REL_ "GenSigTimeoutTime" BU_SG_REL_ CLU SG_ 2015 Byte7_Data_7DF 0;
BA_REL_ "GenSigTimeoutTime" BU_SG_REL_ H_U SG_ 2015 Byte7_Data_7DF 0;
BA_ "Platform" SG_ 2015 Byte7_Data_7DF "";
BA_ "GenMsgILSupport" BO_ 1261 0;
BA_ "TpMessage" BO_ 1261 1;
BA_ "TpTxIndex" BO_ 1261 6;
BA_REL_ "GenSigTimeoutTime" BU_SG_REL_ H_U SG_ 1261 Byte0_TCP_4ED 0;
BA_ "Platform" SG_ 1261 Byte0_TCP_4ED "";
BA_ "GenMsgILSupport" BO_ 1261 0;
BA_ "TpMessage" BO_ 1261 1;
BA_ "TpTxIndex" BO_ 1261 6;
BA_REL_ "GenSigTimeoutTime" BU_SG_REL_ H_U SG_ 1261 Byte1_Data_4ED 0;
BA_ "Platform" SG_ 1261 Byte1_Data_4ED "";
BA_ "GenMsgILSupport" BO_ 1261 0;
BA_ "TpMessage" BO_ 1261 1;
BA_ "TpTxIndex" BO_ 1261 6;
BA_REL_ "GenSigTimeoutTime" BU_SG_REL_ H_U SG_ 1261 Byte2_Data_4ED 0;
BA_ "Platform" SG_ 1261 Byte2_Data_4ED "";
BA_ "GenMsgILSupport" BO_ 1261 0;
BA_ "TpMessage" BO_ 1261 1;
BA_ "TpTxIndex" BO_ 1261 6;
BA_REL_ "GenSigTimeoutTime" BU_SG_REL_ H_U SG_ 1261 Byte3_Data_4ED 0;
BA_ "Platform" SG_ 1261 Byte3_Data_4ED "";
BA_ "GenMsgILSupport" BO_ 1261 0;
BA_ "TpMessage" BO_ 1261 1;
BA_ "TpTxIndex" BO_ 1261 6;
BA_REL_ "GenSigTimeoutTime" BU_SG_REL_ H_U SG_ 1261 Byte4_Data_4ED 0;
BA_ "Platform" SG_ 1261 Byte4_Data_4ED "";
BA_ "GenMsgILSupport" BO_ 1261 0;
BA_ "TpMessage" BO_ 1261 1;
BA_ "TpTxIndex" BO_ 1261 6;
BA_REL_ "GenSigTimeoutTime" BU_SG_REL_ H_U SG_ 1261 Byte5_Data_4ED 0;
BA_ "Platform" SG_ 1261 Byte5_Data_4ED "";
BA_ "GenMsgILSupport" BO_ 1261 0;
BA_ "TpMessage" BO_ 1261 1;
BA_ "TpTxIndex" BO_ 1261 6;
BA_REL_ "GenSigTimeoutTime" BU_SG_REL_ H_U SG_ 1261 Byte6_Data_4ED 0;
BA_ "Platform" SG_ 1261 Byte6_Data_4ED "";
BA_ "GenMsgILSupport" BO_ 1261 0;
BA_ "TpMessage" BO_ 1261 1;
BA_ "TpTxIndex" BO_ 1261 6;
BA_REL_ "GenSigTimeoutTime" BU_SG_REL_ H_U SG_ 1261 Byte7_Data_4ED 0;
BA_ "Platform" SG_ 1261 Byte7_Data_4ED "";
BA_ "GenMsgILSupport" BO_ 1271 0;
BA_ "TpMessage" BO_ 1271 1;
BA_ "TpTxIndex" BO_ 1271 46;
BA_REL_ "GenSigTimeoutTime" BU_SG_REL_ H_U SG_ 1271 Byte0_TCP_4F7 0;
BA_ "Platform" SG_ 1271 Byte0_TCP_4F7 "";
BA_ "GenMsgILSupport" BO_ 1271 0;
BA_ "TpMessage" BO_ 1271 1;
BA_ "TpTxIndex" BO_ 1271 46;
BA_REL_ "GenSigTimeoutTime" BU_SG_REL_ H_U SG_ 1271 Byte1_Data_4F7 0;
BA_ "Platform" SG_ 1271 Byte1_Data_4F7 "";
BA_ "GenMsgILSupport" BO_ 1271 0;
BA_ "TpMessage" BO_ 1271 1;
BA_ "TpTxIndex" BO_ 1271 46;
BA_REL_ "GenSigTimeoutTime" BU_SG_REL_ H_U SG_ 1271 Byte2_Data_4F7 0;
BA_ "Platform" SG_ 1271 Byte2_Data_4F7 "";
BA_ "GenMsgILSupport" BO_ 1271 0;
BA_ "TpMessage" BO_ 1271 1;
BA_ "TpTxIndex" BO_ 1271 46;
BA_REL_ "GenSigTimeoutTime" BU_SG_REL_ H_U SG_ 1271 Byte3_Data_4F7 0;
BA_ "Platform" SG_ 1271 Byte3_Data_4F7 "";
BA_ "GenMsgILSupport" BO_ 1271 0;
BA_ "TpMessage" BO_ 1271 1;
BA_ "TpTxIndex" BO_ 1271 46;
BA_REL_ "GenSigTimeoutTime" BU_SG_REL_ H_U SG_ 1271 Byte4_Data_4F7 0;
BA_ "Platform" SG_ 1271 Byte4_Data_4F7 "";
BA_ "GenMsgILSupport" BO_ 1271 0;
BA_ "TpMessage" BO_ 1271 1;
BA_ "TpTxIndex" BO_ 1271 46;
BA_REL_ "GenSigTimeoutTime" BU_SG_REL_ H_U SG_ 1271 Byte5_Data_4F7 0;
BA_ "Platform" SG_ 1271 Byte5_Data_4F7 "";
BA_ "GenMsgILSupport" BO_ 1271 0;
BA_ "TpMessage" BO_ 1271 1;
BA_ "TpTxIndex" BO_ 1271 46;
BA_REL_ "GenSigTimeoutTime" BU_SG_REL_ H_U SG_ 1271 Byte6_Data_4F7 0;
BA_ "Platform" SG_ 1271 Byte6_Data_4F7 "";
BA_ "GenMsgILSupport" BO_ 1271 0;
BA_ "TpMessage" BO_ 1271 1;
BA_ "TpTxIndex" BO_ 1271 46;
BA_REL_ "GenSigTimeoutTime" BU_SG_REL_ H_U SG_ 1271 Byte7_Data_4F7 0;
BA_ "Platform" SG_ 1271 Byte7_Data_4F7 "";
BA_ "GenMsgILSupport" BO_ 1267 0;
BA_ "TpMessage" BO_ 1267 1;
BA_ "TpTxIndex" BO_ 1267 44;
BA_REL_ "GenSigTimeoutTime" BU_SG_REL_ H_U SG_ 1267 Byte0_TCP_4F3 0;
BA_ "Platform" SG_ 1267 Byte0_TCP_4F3 "";
BA_ "GenMsgILSupport" BO_ 1267 0;
BA_ "TpMessage" BO_ 1267 1;
BA_ "TpTxIndex" BO_ 1267 44;
BA_REL_ "GenSigTimeoutTime" BU_SG_REL_ H_U SG_ 1267 Byte1_Data_4F3 0;
BA_ "Platform" SG_ 1267 Byte1_Data_4F3 "";
BA_ "GenMsgILSupport" BO_ 1267 0;
BA_ "TpMessage" BO_ 1267 1;
BA_ "TpTxIndex" BO_ 1267 44;
BA_REL_ "GenSigTimeoutTime" BU_SG_REL_ H_U SG_ 1267 Byte2_Data_4F3 0;
BA_ "Platform" SG_ 1267 Byte2_Data_4F3 "";
BA_ "GenMsgILSupport" BO_ 1267 0;
BA_ "TpMessage" BO_ 1267 1;
BA_ "TpTxIndex" BO_ 1267 44;
BA_REL_ "GenSigTimeoutTime" BU_SG_REL_ H_U SG_ 1267 Byte3_Data_4F3 0;
BA_ "Platform" SG_ 1267 Byte3_Data_4F3 "";
BA_ "GenMsgILSupport" BO_ 1267 0;
BA_ "TpMessage" BO_ 1267 1;
BA_ "TpTxIndex" BO_ 1267 44;
BA_REL_ "GenSigTimeoutTime" BU_SG_REL_ H_U SG_ 1267 Byte4_Data_4F3 0;
BA_ "Platform" SG_ 1267 Byte4_Data_4F3 "";
BA_ "GenMsgILSupport" BO_ 1267 0;
BA_ "TpMessage" BO_ 1267 1;
BA_ "TpTxIndex" BO_ 1267 44;
BA_REL_ "GenSigTimeoutTime" BU_SG_REL_ H_U SG_ 1267 Byte5_Data_4F3 0;
BA_ "Platform" SG_ 1267 Byte5_Data_4F3 "";
BA_ "GenMsgILSupport" BO_ 1267 0;
BA_ "TpMessage" BO_ 1267 1;
BA_ "TpTxIndex" BO_ 1267 44;
BA_REL_ "GenSigTimeoutTime" BU_SG_REL_ H_U SG_ 1267 Byte6_Data_4F3 0;
BA_ "Platform" SG_ 1267 Byte6_Data_4F3 "";
BA_ "GenMsgILSupport" BO_ 1267 0;
BA_ "TpMessage" BO_ 1267 1;
BA_ "TpTxIndex" BO_ 1267 44;
BA_REL_ "GenSigTimeoutTime" BU_SG_REL_ H_U SG_ 1267 Byte7_Data_4F3 0;
BA_ "Platform" SG_ 1267 Byte7_Data_4F3 "";
BA_ "GenMsgILSupport" BO_ 1257 0;
BA_ "TpMessage" BO_ 1257 1;
BA_ "TpTxIndex" BO_ 1257 36;
BA_REL_ "GenSigTimeoutTime" BU_SG_REL_ H_U SG_ 1257 Byte0_TCP_4E9 0;
BA_ "Platform" SG_ 1257 Byte0_TCP_4E9 "";
BA_ "GenMsgILSupport" BO_ 1257 0;
BA_ "TpMessage" BO_ 1257 1;
BA_ "TpTxIndex" BO_ 1257 36;
BA_REL_ "GenSigTimeoutTime" BU_SG_REL_ H_U SG_ 1257 Byte1_Data_4E9 0;
BA_ "Platform" SG_ 1257 Byte1_Data_4E9 "";
BA_ "GenMsgILSupport" BO_ 1257 0;
BA_ "TpMessage" BO_ 1257 1;
BA_ "TpTxIndex" BO_ 1257 36;
BA_REL_ "GenSigTimeoutTime" BU_SG_REL_ H_U SG_ 1257 Byte2_Data_4E9 0;
BA_ "Platform" SG_ 1257 Byte2_Data_4E9 "";
BA_ "GenMsgILSupport" BO_ 1257 0;
BA_ "TpMessage" BO_ 1257 1;
BA_ "TpTxIndex" BO_ 1257 36;
BA_REL_ "GenSigTimeoutTime" BU_SG_REL_ H_U SG_ 1257 Byte3_Data_4E9 0;
BA_ "Platform" SG_ 1257 Byte3_Data_4E9 "";
BA_ "GenMsgILSupport" BO_ 1257 0;
BA_ "TpMessage" BO_ 1257 1;
BA_ "TpTxIndex" BO_ 1257 36;
BA_REL_ "GenSigTimeoutTime" BU_SG_REL_ H_U SG_ 1257 Byte4_Data_4E9 0;
BA_ "Platform" SG_ 1257 Byte4_Data_4E9 "";
BA_ "GenMsgILSupport" BO_ 1257 0;
BA_ "TpMessage" BO_ 1257 1;
BA_ "TpTxIndex" BO_ 1257 36;
BA_REL_ "GenSigTimeoutTime" BU_SG_REL_ H_U SG_ 1257 Byte5_Data_4E9 0;
BA_ "Platform" SG_ 1257 Byte5_Data_4E9 "";
BA_ "GenMsgILSupport" BO_ 1257 0;
BA_ "TpMessage" BO_ 1257 1;
BA_ "TpTxIndex" BO_ 1257 36;
BA_REL_ "GenSigTimeoutTime" BU_SG_REL_ H_U SG_ 1257 Byte6_Data_4E9 0;
BA_ "Platform" SG_ 1257 Byte6_Data_4E9 "";
BA_ "GenMsgILSupport" BO_ 1257 0;
BA_ "TpMessage" BO_ 1257 1;
BA_ "TpTxIndex" BO_ 1257 36;
BA_REL_ "GenSigTimeoutTime" BU_SG_REL_ H_U SG_ 1257 Byte7_Data_4E9 0;
BA_ "Platform" SG_ 1257 Byte7_Data_4E9 "";
BA_ "GenMsgILSupport" BO_ 1263 0;
BA_ "TpMessage" BO_ 1263 1;
BA_ "TpTxIndex" BO_ 1263 39;
BA_REL_ "GenSigTimeoutTime" BU_SG_REL_ H_U SG_ 1263 Byte0_TCP_4EF 0;
BA_ "Platform" SG_ 1263 Byte0_TCP_4EF "";
BA_ "GenMsgILSupport" BO_ 1263 0;
BA_ "TpMessage" BO_ 1263 1;
BA_ "TpTxIndex" BO_ 1263 39;
BA_REL_ "GenSigTimeoutTime" BU_SG_REL_ H_U SG_ 1263 Byte1_Data_4EF 0;
BA_ "Platform" SG_ 1263 Byte1_Data_4EF "";
BA_ "GenMsgILSupport" BO_ 1263 0;
BA_ "TpMessage" BO_ 1263 1;
BA_ "TpTxIndex" BO_ 1263 39;
BA_REL_ "GenSigTimeoutTime" BU_SG_REL_ H_U SG_ 1263 Byte2_Data_4EF 0;
BA_ "Platform" SG_ 1263 Byte2_Data_4EF "";
BA_ "GenMsgILSupport" BO_ 1263 0;
BA_ "TpMessage" BO_ 1263 1;
BA_ "TpTxIndex" BO_ 1263 39;
BA_REL_ "GenSigTimeoutTime" BU_SG_REL_ H_U SG_ 1263 Byte3_Data_4EF 0;
BA_ "Platform" SG_ 1263 Byte3_Data_4EF "";
BA_ "GenMsgILSupport" BO_ 1263 0;
BA_ "TpMessage" BO_ 1263 1;
BA_ "TpTxIndex" BO_ 1263 39;
BA_REL_ "GenSigTimeoutTime" BU_SG_REL_ H_U SG_ 1263 Byte4_Data_4EF 0;
BA_ "Platform" SG_ 1263 Byte4_Data_4EF "";
BA_ "GenMsgILSupport" BO_ 1263 0;
BA_ "TpMessage" BO_ 1263 1;
BA_ "TpTxIndex" BO_ 1263 39;
BA_REL_ "GenSigTimeoutTime" BU_SG_REL_ H_U SG_ 1263 Byte5_Data_4EF 0;
BA_ "Platform" SG_ 1263 Byte5_Data_4EF "";
BA_ "GenMsgILSupport" BO_ 1263 0;
BA_ "TpMessage" BO_ 1263 1;
BA_ "TpTxIndex" BO_ 1263 39;
BA_REL_ "GenSigTimeoutTime" BU_SG_REL_ H_U SG_ 1263 Byte6_Data_4EF 0;
BA_ "Platform" SG_ 1263 Byte6_Data_4EF "";
BA_ "GenMsgILSupport" BO_ 1263 0;
BA_ "TpMessage" BO_ 1263 1;
BA_ "TpTxIndex" BO_ 1263 39;
BA_REL_ "GenSigTimeoutTime" BU_SG_REL_ H_U SG_ 1263 Byte7_Data_4EF 0;
BA_ "Platform" SG_ 1263 Byte7_Data_4EF "";
BA_ "GenMsgILSupport" BO_ 1255 0;
BA_ "TpMessage" BO_ 1255 1;
BA_ "TpTxIndex" BO_ 1255 12;
BA_REL_ "GenSigTimeoutTime" BU_SG_REL_ H_U SG_ 1255 Byte0_TCP_4E7 0;
BA_ "Platform" SG_ 1255 Byte0_TCP_4E7 "";
BA_ "GenMsgILSupport" BO_ 1255 0;
BA_ "TpMessage" BO_ 1255 1;
BA_ "TpTxIndex" BO_ 1255 12;
BA_REL_ "GenSigTimeoutTime" BU_SG_REL_ H_U SG_ 1255 Byte1_Data_4E7 0;
BA_ "Platform" SG_ 1255 Byte1_Data_4E7 "";
BA_ "GenMsgILSupport" BO_ 1255 0;
BA_ "TpMessage" BO_ 1255 1;
BA_ "TpTxIndex" BO_ 1255 12;
BA_REL_ "GenSigTimeoutTime" BU_SG_REL_ H_U SG_ 1255 Byte2_Data_4E7 0;
BA_ "Platform" SG_ 1255 Byte2_Data_4E7 "";
BA_ "GenMsgILSupport" BO_ 1255 0;
BA_ "TpMessage" BO_ 1255 1;
BA_ "TpTxIndex" BO_ 1255 12;
BA_REL_ "GenSigTimeoutTime" BU_SG_REL_ H_U SG_ 1255 Byte3_Data_4E7 0;
BA_ "Platform" SG_ 1255 Byte3_Data_4E7 "";
BA_ "GenMsgILSupport" BO_ 1255 0;
BA_ "TpMessage" BO_ 1255 1;
BA_ "TpTxIndex" BO_ 1255 12;
BA_REL_ "GenSigTimeoutTime" BU_SG_REL_ H_U SG_ 1255 Byte4_Data_4E7 0;
BA_ "Platform" SG_ 1255 Byte4_Data_4E7 "";
BA_ "GenMsgILSupport" BO_ 1255 0;
BA_ "TpMessage" BO_ 1255 1;
BA_ "TpTxIndex" BO_ 1255 12;
BA_REL_ "GenSigTimeoutTime" BU_SG_REL_ H_U SG_ 1255 Byte5_Data_4E7 0;
BA_ "Platform" SG_ 1255 Byte5_Data_4E7 "";
BA_ "GenMsgILSupport" BO_ 1255 0;
BA_ "TpMessage" BO_ 1255 1;
BA_ "TpTxIndex" BO_ 1255 12;
BA_REL_ "GenSigTimeoutTime" BU_SG_REL_ H_U SG_ 1255 Byte6_Data_4E7 0;
BA_ "Platform" SG_ 1255 Byte6_Data_4E7 "";
BA_ "GenMsgILSupport" BO_ 1255 0;
BA_ "TpMessage" BO_ 1255 1;
BA_ "TpTxIndex" BO_ 1255 12;
BA_REL_ "GenSigTimeoutTime" BU_SG_REL_ H_U SG_ 1255 Byte7_Data_4E7 0;
BA_ "Platform" SG_ 1255 Byte7_Data_4E7 "";
BA_ "GenMsgSendType" BO_ 400 0;
BA_ "GenMsgCycleTime" BO_ 400 200;
BA_ "GenMsgStartDelayTime" BO_ 400 110;
BA_REL_ "GenSigTimeoutTime" BU_SG_REL_ CGW SG_ 400 C_BLECrankingCmd 750;
BA_ "Platform" SG_ 400 C_BLECrankingCmd "";
BA_ "GenSigSendType" SG_ 400 C_BLECrankingCmd 3;
BA_ "Gatewaysignal" SG_ 400 C_BLECrankingCmd 1;
BA_ "TimeoutValue" SG_ 400 C_BLECrankingCmd "0x3";
BA_ "Validity" SG_ 400 C_BLECrankingCmd 0;
BA_REL_ "GenSigTimeoutTime" BU_SG_REL_ CGW SG_ 400 C_BLEDeviceDetectionStatus 750;
BA_ "Platform" SG_ 400 C_BLEDeviceDetectionStatus "";
BA_ "GenSigSendType" SG_ 400 C_BLEDeviceDetectionStatus 3;
BA_ "Gatewaysignal" SG_ 400 C_BLEDeviceDetectionStatus 1;
BA_ "TimeoutValue" SG_ 400 C_BLEDeviceDetectionStatus "0x7";
BA_ "Validity" SG_ 400 C_BLEDeviceDetectionStatus 0;
BA_REL_ "GenSigTimeoutTime" BU_SG_REL_ CGW SG_ 400 C_BLEOption 750;
BA_ "Platform" SG_ 400 C_BLEOption "";
BA_ "GenSigSendType" SG_ 400 C_BLEOption 3;
BA_ "Gatewaysignal" SG_ 400 C_BLEOption 1;
BA_ "TimeoutValue" SG_ 400 C_BLEOption "0x7";
BA_ "Validity" SG_ 400 C_BLEOption 0;
BA_REL_ "GenSigTimeoutTime" BU_SG_REL_ CGW SG_ 400 C_BLE_ProfileIDRValue 750;
BA_REL_ "GenSigTimeoutTime" BU_SG_REL_ CLU SG_ 400 C_BLE_ProfileIDRValue 750;
BA_ "Platform" SG_ 400 C_BLE_ProfileIDRValue "";
BA_ "GenSigSendType" SG_ 400 C_BLE_ProfileIDRValue 3;
BA_ "Gatewaysignal" SG_ 400 C_BLE_ProfileIDRValue 1;
BA_ "TimeoutValue" SG_ 400 C_BLE_ProfileIDRValue "0xF";
BA_ "Validity" SG_ 400 C_BLE_ProfileIDRValue 0;
BA_REL_ "GenSigTimeoutTime" BU_SG_REL_ CGW SG_ 400 C_BLE_ReadyToSendAuth 750;
BA_ "Platform" SG_ 400 C_BLE_ReadyToSendAuth "";
BA_ "GenSigSendType" SG_ 400 C_BLE_ReadyToSendAuth 3;
BA_ "Gatewaysignal" SG_ 400 C_BLE_ReadyToSendAuth 1;
BA_ "TimeoutValue" SG_ 400 C_BLE_ReadyToSendAuth "0x0";
BA_ "Validity" SG_ 400 C_BLE_ReadyToSendAuth 0;
BA_REL_ "GenSigTimeoutTime" BU_SG_REL_ CGW SG_ 400 C_BLEISKLearnState 750;
BA_ "Platform" SG_ 400 C_BLEISKLearnState "";
BA_ "GenSigSendType" SG_ 400 C_BLEISKLearnState 3;
BA_ "Gatewaysignal" SG_ 400 C_BLEISKLearnState 1;
BA_ "TimeoutValue" SG_ 400 C_BLEISKLearnState "0x2";
BA_ "Validity" SG_ 400 C_BLEISKLearnState 0;
BA_ "GenMsgSendType" BO_ 277 0;
BA_ "GenMsgCycleTime" BO_ 277 200;
BA_ "GenMsgCycleTimeFast" BO_ 277 40;
BA_ "GenMsgNrOfRepetition" BO_ 277 3;
BA_ "GenMsgStartDelayTime" BO_ 277 170;
BA_REL_ "GenSigTimeoutTime" BU_SG_REL_ CLU SG_ 277 TBT_Display_Type 750;
BA_ "SigDescription" SG_ 277 TBT_Display_Type "Signal value table description abbreviation reference
C : Center
R : Right
M : Middle
L : Left
WP : Way Point";
BA_ "Platform" SG_ 277 TBT_Display_Type "";
BA_ "GenSigSendType" SG_ 277 TBT_Display_Type 4;
BA_ "GenSigStartValue" SG_ 277 TBT_Display_Type 255;
BA_ "NmNetworkRequest" SG_ 277 TBT_Display_Type 1;
BA_ "TimeoutValue" SG_ 277 TBT_Display_Type "Old Value";
BA_ "Platform" SG_ 277 TBT_Side_Street "";
BA_ "GenSigSendType" SG_ 277 TBT_Side_Street 4;
BA_ "GenSigStartValue" SG_ 277 TBT_Side_Street 65535;
BA_ "NmNetworkRequest" SG_ 277 TBT_Side_Street 1;
BA_ "TimeoutValue" SG_ 277 TBT_Side_Street "Old value";
BA_ "Platform" SG_ 277 TBT_Direction "";
BA_ "GenSigSendType" SG_ 277 TBT_Direction 4;
BA_ "GenSigStartValue" SG_ 277 TBT_Direction 255;
BA_ "NmNetworkRequest" SG_ 277 TBT_Direction 1;
BA_ "TimeoutValue" SG_ 277 TBT_Direction "Old value";
BA_ "Platform" SG_ 277 TBT_Distance_Turn_Point "";
BA_ "GenSigSendType" SG_ 277 TBT_Distance_Turn_Point 4;
BA_ "GenSigStartValue" SG_ 277 TBT_Distance_Turn_Point 65535;
BA_ "NmNetworkRequest" SG_ 277 TBT_Distance_Turn_Point 1;
BA_ "TimeoutValue" SG_ 277 TBT_Distance_Turn_Point "Old value";
BA_ "Platform" SG_ 277 TBT_Combined_Side_Street "";
BA_ "GenSigSendType" SG_ 277 TBT_Combined_Side_Street 4;
BA_ "GenSigStartValue" SG_ 277 TBT_Combined_Side_Street 15;
BA_ "NmNetworkRequest" SG_ 277 TBT_Combined_Side_Street 1;
BA_ "TimeoutValue" SG_ 277 TBT_Combined_Side_Street "Old value";
BA_ "Platform" SG_ 277 TBT_Scale "";
BA_ "GenSigSendType" SG_ 277 TBT_Scale 4;
BA_ "GenSigStartValue" SG_ 277 TBT_Scale 15;
BA_ "NmNetworkRequest" SG_ 277 TBT_Scale 1;
BA_ "TimeoutValue" SG_ 277 TBT_Scale "Old value";
BA_ "Platform" SG_ 277 TBT_DistancetoTurnPoint "";
BA_ "GenSigSendType" SG_ 277 TBT_DistancetoTurnPoint 4;
BA_ "GenSigStartValue" SG_ 277 TBT_DistancetoTurnPoint 15;
BA_ "NmNetworkRequest" SG_ 277 TBT_DistancetoTurnPoint 1;
BA_ "TimeoutValue" SG_ 277 TBT_DistancetoTurnPoint "Old value";
BA_ "GenMsgSendType" BO_ 407 0;
BA_ "GenMsgCycleTime" BO_ 407 1000;
BA_ "GenMsgCycleTimeFast" BO_ 407 40;
BA_ "GenMsgNrOfRepetition" BO_ 407 3;
BA_ "GenMsgStartDelayTime" BO_ 407 560;
BA_REL_ "GenSigTimeoutTime" BU_SG_REL_ CGW SG_ 407 HU_LanguageInfo 3500;
BA_REL_ "GenSigTimeoutTime" BU_SG_REL_ CLU SG_ 407 HU_LanguageInfo 3500;
BA_ "SigDescription" SG_ 407 HU_LanguageInfo "Hungarian (0x1C) 수정 (For AE)";
BA_ "Platform" SG_ 407 HU_LanguageInfo "";
BA_ "GenSigSendType" SG_ 407 HU_LanguageInfo 4;
BA_ "GenSigStartValue" SG_ 407 HU_LanguageInfo 255;
BA_ "NmNetworkRequest" SG_ 407 HU_LanguageInfo 1;
BA_ "TimeoutValue" SG_ 407 HU_LanguageInfo "Old Value";
BA_REL_ "GenSigTimeoutTime" BU_SG_REL_ CLU SG_ 407 HU_MuteStatus 3500;
BA_ "Platform" SG_ 407 HU_MuteStatus "";
BA_ "GenSigSendType" SG_ 407 HU_MuteStatus 4;
BA_ "GenSigStartValue" SG_ 407 HU_MuteStatus 3;
BA_ "NmNetworkRequest" SG_ 407 HU_MuteStatus 1;
BA_ "TimeoutValue" SG_ 407 HU_MuteStatus "Old Value";
BA_REL_ "GenSigTimeoutTime" BU_SG_REL_ CLU SG_ 407 HU_VolumeStatus 3500;
BA_ "Platform" SG_ 407 HU_VolumeStatus "";
BA_ "GenSigSendType" SG_ 407 HU_VolumeStatus 4;
BA_ "GenSigStartValue" SG_ 407 HU_VolumeStatus 63;
BA_ "NmNetworkRequest" SG_ 407 HU_VolumeStatus 1;
BA_ "TimeoutValue" SG_ 407 HU_VolumeStatus "Old Value";
BA_REL_ "GenSigTimeoutTime" BU_SG_REL_ CLU SG_ 407 HU_NaviDisp 3500;
BA_ "Platform" SG_ 407 HU_NaviDisp "";
BA_ "GenSigSendType" SG_ 407 HU_NaviDisp 4;
BA_ "GenSigStartValue" SG_ 407 HU_NaviDisp 3;
BA_ "NmNetworkRequest" SG_ 407 HU_NaviDisp 1;
BA_ "TimeoutValue" SG_ 407 HU_NaviDisp "Old Value";
BA_REL_ "GenSigTimeoutTime" BU_SG_REL_ CGW SG_ 407 HU_NaviStatus 3500;
BA_REL_ "GenSigTimeoutTime" BU_SG_REL_ CLU SG_ 407 HU_NaviStatus 3500;
BA_ "Platform" SG_ 407 HU_NaviStatus "";
BA_ "GenSigSendType" SG_ 407 HU_NaviStatus 4;
BA_ "GenSigStartValue" SG_ 407 HU_NaviStatus 3;
BA_ "Gatewaysignal" SG_ 407 HU_NaviStatus 5;
BA_ "NmNetworkRequest" SG_ 407 HU_NaviStatus 1;
BA_ "TimeoutValue" SG_ 407 HU_NaviStatus "Old Value";
BA_ "GenMsgSendType" BO_ 290 0;
BA_ "GenMsgCycleTime" BO_ 290 200;
BA_ "GenMsgCycleTimeFast" BO_ 290 40;
BA_ "GenMsgNrOfRepetition" BO_ 290 3;
BA_ "GenMsgStartDelayTime" BO_ 290 180;
BA_REL_ "GenSigTimeoutTime" BU_SG_REL_ CLU SG_ 290 HU_OpState_New 2000;
BA_ "Platform" SG_ 290 HU_OpState_New "";
BA_ "GenSigSendType" SG_ 290 HU_OpState_New 4;
BA_ "GenSigStartValue" SG_ 290 HU_OpState_New 127;
BA_ "NmNetworkRequest" SG_ 290 HU_OpState_New 1;
BA_ "TimeoutValue" SG_ 290 HU_OpState_New "0x7F";
BA_ "Platform" SG_ 290 HU_Frequency_Unit "";
BA_ "GenSigSendType" SG_ 290 HU_Frequency_Unit 3;
BA_ "GenSigStartValue" SG_ 290 HU_Frequency_Unit 3;
BA_ "Platform" SG_ 290 HU_User_Input "Compact AVN,D-Audio,Economic Audio 3.0,Integrated AVN1.0 High,Integrated AVN1.0 Mid,Premium AVN 2.0,Standard AVN 4.0,Standard Audio 3.0,Standard Audio 4.0";
BA_ "GenSigSendType" SG_ 290 HU_User_Input 3;
BA_ "TimeoutValue" SG_ 290 HU_User_Input "Invalid";
BA_REL_ "GenSigTimeoutTime" BU_SG_REL_ CLU SG_ 290 HU_FMFrequency_Offset_Type 2000;
BA_ "SigDescription" SG_ 290 HU_FMFrequency_Offset_Type "Case 1) Offset Type==1(8750) : 'HU_Frequency_New' signal offset value is 8750

Case 2) Offset Type==2(6000) : 'HU_Frequency_New' signal offset value is 6000
 - In case FM frequency minimum value is less than 8750, offset type 2 is applied. (Brazil, Japan, etc...)";
BA_ "Platform" SG_ 290 HU_FMFrequency_Offset_Type "D-Audio,Integrated AVN1.0 High,Integrated AVN1.0 Mid,Premium AVN 2.0,Standard Audio 4.0";
BA_ "GenSigSendType" SG_ 290 HU_FMFrequency_Offset_Type 3;
BA_ "TimeoutValue" SG_ 290 HU_FMFrequency_Offset_Type "Invalid";
BA_ "Platform" SG_ 290 FM_Decimal_Point "";
BA_ "GenSigSendType" SG_ 290 FM_Decimal_Point 4;
BA_ "GenSigStartValue" SG_ 290 FM_Decimal_Point 3;
BA_ "NmNetworkRequest" SG_ 290 FM_Decimal_Point 1;
BA_ "TimeoutValue" SG_ 290 FM_Decimal_Point "0x3";
BA_ "Platform" SG_ 290 HU_Track_Number_New "";
BA_ "GenSigSendType" SG_ 290 HU_Track_Number_New 4;
BA_ "GenSigStartValue" SG_ 290 HU_Track_Number_New 65535;
BA_ "NmNetworkRequest" SG_ 290 HU_Track_Number_New 1;
BA_ "TimeoutValue" SG_ 290 HU_Track_Number_New "0xFFFF";
BA_ "Platform" SG_ 290 HU_Play_time_Sec_New "";
BA_ "GenSigSendType" SG_ 290 HU_Play_time_Sec_New 4;
BA_ "GenSigStartValue" SG_ 290 HU_Play_time_Sec_New 63;
BA_ "NmNetworkRequest" SG_ 290 HU_Play_time_Sec_New 1;
BA_ "TimeoutValue" SG_ 290 HU_Play_time_Sec_New "0x3F";
BA_ "Platform" SG_ 290 HU_Play_time_Min_New "";
BA_ "GenSigSendType" SG_ 290 HU_Play_time_Min_New 4;
BA_ "GenSigStartValue" SG_ 290 HU_Play_time_Min_New 63;
BA_ "NmNetworkRequest" SG_ 290 HU_Play_time_Min_New 1;
BA_ "TimeoutValue" SG_ 290 HU_Play_time_Min_New "0x3F";
BA_ "Platform" SG_ 290 HU_Play_time_Hour_New "";
BA_ "GenSigSendType" SG_ 290 HU_Play_time_Hour_New 4;
BA_ "GenSigStartValue" SG_ 290 HU_Play_time_Hour_New 127;
BA_ "NmNetworkRequest" SG_ 290 HU_Play_time_Hour_New 1;
BA_ "TimeoutValue" SG_ 290 HU_Play_time_Hour_New "0x7F";
BA_REL_ "GenSigTimeoutTime" BU_SG_REL_ CLU SG_ 290 HU_Frequency_New 2000;
BA_ "SigDescription" SG_ 290 HU_Frequency_New "AM : Frequency = Signal value (ignore Decimal_Point value)
FM : Frequency = (Signal value (in decimal) + Offset Type) / 100
Case 1) 'HU_FMFrequency_Offset_Type'==8750 (Hex==0x0)
            : 'HU_Frequency_New' signal offset value is 8750
Case 2) 'HU_FMFrequency_Offset_Type'==6000 (Hex==0x1)
            : 'HU_Frequency_New' signal offset value is 6000";
BA_ "Platform" SG_ 290 HU_Frequency_New "D-Audio,Integrated AVN1.0 High,Integrated AVN1.0 Mid,Premium AVN 2.0,Standard Audio 4.0";
BA_ "GenSigSendType" SG_ 290 HU_Frequency_New 4;
BA_ "GenSigStartValue" SG_ 290 HU_Frequency_New 8191;
BA_ "NmNetworkRequest" SG_ 290 HU_Frequency_New 1;
BA_ "TimeoutValue" SG_ 290 HU_Frequency_New "0x1FFF";
BA_ "GenMsgSendType" BO_ 291 0;
BA_ "GenMsgCycleTime" BO_ 291 200;
BA_ "GenMsgCycleTimeFast" BO_ 291 40;
BA_ "GenMsgNrOfRepetition" BO_ 291 3;
BA_ "GenMsgStartDelayTime" BO_ 291 170;
BA_ "Platform" SG_ 291 NV_Display_TG "";
BA_ "GenSigSendType" SG_ 291 NV_Display_TG 4;
BA_ "GenSigStartValue" SG_ 291 NV_Display_TG 3;
BA_ "NmNetworkRequest" SG_ 291 NV_Display_TG 1;
BA_REL_ "GenSigTimeoutTime" BU_SG_REL_ CLU SG_ 291 TBT_BarGraph100Level 750;
BA_ "Platform" SG_ 291 TBT_BarGraph100Level "";
BA_ "GenSigSendType" SG_ 291 TBT_BarGraph100Level 3;
BA_ "GenSigStartValue" SG_ 291 TBT_BarGraph100Level 255;
BA_ "TimeoutValue" SG_ 291 TBT_BarGraph100Level "old vaule";
BA_ "Validity" SG_ 291 TBT_BarGraph100Level 2;
BA_ "GenMsgSendType" BO_ 286 0;
BA_ "GenMsgCycleTime" BO_ 286 200;
BA_ "GenMsgStartDelayTime" BO_ 286 190;
BA_ "Platform" SG_ 286 Navi_WarnDist_OverDec "Compact AVN,DIS 2,Integrated AVN1.0 High,Integrated AVN1.0 Mid,Premium AVN 2.0,Standard AVN 4.0";
BA_ "GenSigSendType" SG_ 286 Navi_WarnDist_OverDec 3;
BA_ "GenSigStartValue" SG_ 286 Navi_WarnDist_OverDec 65535;
BA_ "TimeoutValue" SG_ 286 Navi_WarnDist_OverDec "Old value";
BA_ "Platform" SG_ 286 Navi_WarnDist_UnderDec "Compact AVN,DIS 2,Integrated AVN1.0 High,Integrated AVN1.0 Mid,Premium AVN 2.0,Standard AVN 4.0";
BA_ "GenSigSendType" SG_ 286 Navi_WarnDist_UnderDec 3;
BA_ "GenSigStartValue" SG_ 286 Navi_WarnDist_UnderDec 15;
BA_ "TimeoutValue" SG_ 286 Navi_WarnDist_UnderDec "Old value";
BA_ "Platform" SG_ 286 Navi_WarnDist_Scale "Compact AVN,DIS 2,Integrated AVN1.0 High,Integrated AVN1.0 Mid,Premium AVN 2.0,Standard AVN 4.0";
BA_ "GenSigSendType" SG_ 286 Navi_WarnDist_Scale 3;
BA_ "GenSigStartValue" SG_ 286 Navi_WarnDist_Scale 15;
BA_ "TimeoutValue" SG_ 286 Navi_WarnDist_Scale "Old value";
BA_REL_ "GenSigTimeoutTime" BU_SG_REL_ CGW SG_ 52 HU_DATC_DrTempUpDn 0;
BA_REL_ "GenSigTimeoutTime" BU_SG_REL_ CLU SG_ 52 HU_DATC_DrTempUpDn 0;
BA_ "Platform" SG_ 52 HU_DATC_DrTempUpDn "";
BA_ "GenSigSendType" SG_ 52 HU_DATC_DrTempUpDn 3;
BA_ "GenSigStartValue" SG_ 52 HU_DATC_DrTempUpDn 3;
BA_ "Gatewaysignal" SG_ 52 HU_DATC_DrTempUpDn 3;
BA_ "Validity" SG_ 52 HU_DATC_DrTempUpDn 2;
BA_REL_ "GenSigTimeoutTime" BU_SG_REL_ CGW SG_ 52 HU_DATC_MainBlower 0;
BA_REL_ "GenSigTimeoutTime" BU_SG_REL_ CLU SG_ 52 HU_DATC_MainBlower 0;
BA_ "Platform" SG_ 52 HU_DATC_MainBlower "";
BA_ "GenSigSendType" SG_ 52 HU_DATC_MainBlower 3;
BA_ "GenSigStartValue" SG_ 52 HU_DATC_MainBlower 15;
BA_ "Gatewaysignal" SG_ 52 HU_DATC_MainBlower 3;
BA_ "Validity" SG_ 52 HU_DATC_MainBlower 2;
BA_REL_ "GenSigTimeoutTime" BU_SG_REL_ CGW SG_ 52 HU_DATC_FrontModeSet 0;
BA_REL_ "GenSigTimeoutTime" BU_SG_REL_ CLU SG_ 52 HU_DATC_FrontModeSet 0;
BA_ "Platform" SG_ 52 HU_DATC_FrontModeSet "";
BA_ "GenSigSendType" SG_ 52 HU_DATC_FrontModeSet 3;
BA_ "GenSigStartValue" SG_ 52 HU_DATC_FrontModeSet 15;
BA_ "Gatewaysignal" SG_ 52 HU_DATC_FrontModeSet 3;
BA_ "Validity" SG_ 52 HU_DATC_FrontModeSet 2;
BA_REL_ "GenSigTimeoutTime" BU_SG_REL_ CGW SG_ 52 HU_DATC_AutoSet 0;
BA_REL_ "GenSigTimeoutTime" BU_SG_REL_ CLU SG_ 52 HU_DATC_AutoSet 0;
BA_ "Platform" SG_ 52 HU_DATC_AutoSet "";
BA_ "GenSigSendType" SG_ 52 HU_DATC_AutoSet 3;
BA_ "GenSigStartValue" SG_ 52 HU_DATC_AutoSet 3;
BA_ "Gatewaysignal" SG_ 52 HU_DATC_AutoSet 3;
BA_ "Validity" SG_ 52 HU_DATC_AutoSet 2;
BA_REL_ "GenSigTimeoutTime" BU_SG_REL_ CGW SG_ 52 HU_DATC_IntakeSet 0;
BA_REL_ "GenSigTimeoutTime" BU_SG_REL_ CLU SG_ 52 HU_DATC_IntakeSet 0;
BA_ "Platform" SG_ 52 HU_DATC_IntakeSet "";
BA_ "GenSigSendType" SG_ 52 HU_DATC_IntakeSet 3;
BA_ "GenSigStartValue" SG_ 52 HU_DATC_IntakeSet 3;
BA_ "Gatewaysignal" SG_ 52 HU_DATC_IntakeSet 3;
BA_ "Validity" SG_ 52 HU_DATC_IntakeSet 2;
BA_REL_ "GenSigTimeoutTime" BU_SG_REL_ CGW SG_ 52 HU_DATC_AcSet 0;
BA_REL_ "GenSigTimeoutTime" BU_SG_REL_ CLU SG_ 52 HU_DATC_AcSet 0;
BA_ "Platform" SG_ 52 HU_DATC_AcSet "";
BA_ "GenSigSendType" SG_ 52 HU_DATC_AcSet 3;
BA_ "GenSigStartValue" SG_ 52 HU_DATC_AcSet 3;
BA_ "Gatewaysignal" SG_ 52 HU_DATC_AcSet 3;
BA_ "Validity" SG_ 52 HU_DATC_AcSet 2;
BA_REL_ "GenSigTimeoutTime" BU_SG_REL_ CGW SG_ 52 HU_DATC_FrontDefog 0;
BA_REL_ "GenSigTimeoutTime" BU_SG_REL_ CLU SG_ 52 HU_DATC_FrontDefog 0;
BA_ "Platform" SG_ 52 HU_DATC_FrontDefog "";
BA_ "GenSigSendType" SG_ 52 HU_DATC_FrontDefog 3;
BA_ "GenSigStartValue" SG_ 52 HU_DATC_FrontDefog 3;
BA_ "Gatewaysignal" SG_ 52 HU_DATC_FrontDefog 3;
BA_ "Validity" SG_ 52 HU_DATC_FrontDefog 2;
BA_REL_ "GenSigTimeoutTime" BU_SG_REL_ CGW SG_ 52 HU_DATC_MainBlowerUpDn 0;
BA_REL_ "GenSigTimeoutTime" BU_SG_REL_ CLU SG_ 52 HU_DATC_MainBlowerUpDn 0;
BA_ "Platform" SG_ 52 HU_DATC_MainBlowerUpDn "";
BA_ "GenSigSendType" SG_ 52 HU_DATC_MainBlowerUpDn 3;
BA_ "GenSigStartValue" SG_ 52 HU_DATC_MainBlowerUpDn 3;
BA_ "Validity" SG_ 52 HU_DATC_MainBlowerUpDn 2;
BA_REL_ "GenSigTimeoutTime" BU_SG_REL_ CGW SG_ 52 HU_DATC_AirCleaningSet 0;
BA_REL_ "GenSigTimeoutTime" BU_SG_REL_ CLU SG_ 52 HU_DATC_AirCleaningSet 0;
BA_ "Platform" SG_ 52 HU_DATC_AirCleaningSet "";
BA_ "GenSigSendType" SG_ 52 HU_DATC_AirCleaningSet 3;
BA_ "GenSigStartValue" SG_ 52 HU_DATC_AirCleaningSet 3;
BA_ "Validity" SG_ 52 HU_DATC_AirCleaningSet 2;
BA_REL_ "GenSigTimeoutTime" BU_SG_REL_ CGW SG_ 54 HU_DATC_DrTempSetC 0;
BA_REL_ "GenSigTimeoutTime" BU_SG_REL_ CLU SG_ 54 HU_DATC_DrTempSetC 0;
BA_ "Platform" SG_ 54 HU_DATC_DrTempSetC "";
BA_ "GenSigSendType" SG_ 54 HU_DATC_DrTempSetC 3;
BA_ "GenSigStartValue" SG_ 54 HU_DATC_DrTempSetC 255;
BA_ "Validity" SG_ 54 HU_DATC_DrTempSetC 2;
BA_REL_ "GenSigTimeoutTime" BU_SG_REL_ CGW SG_ 54 HU_DATC_DrTempSetF 0;
BA_REL_ "GenSigTimeoutTime" BU_SG_REL_ CLU SG_ 54 HU_DATC_DrTempSetF 0;
BA_ "Platform" SG_ 54 HU_DATC_DrTempSetF "";
BA_ "GenSigSendType" SG_ 54 HU_DATC_DrTempSetF 3;
BA_ "GenSigStartValue" SG_ 54 HU_DATC_DrTempSetF 255;
BA_ "Validity" SG_ 54 HU_DATC_DrTempSetF 2;
BA_REL_ "GenSigTimeoutTime" BU_SG_REL_ CGW SG_ 54 C_DATC_DTC_Mode 0;
BA_ "SigDescription" SG_ 54 C_DATC_DTC_Mode "This signal is only used on China OEM platform";
BA_ "Platform" SG_ 54 C_DATC_DTC_Mode "";
BA_ "GenSigSendType" SG_ 54 C_DATC_DTC_Mode 3;
BA_ "GenSigStartValue" SG_ 54 C_DATC_DTC_Mode 3;
BA_ "Validity" SG_ 54 C_DATC_DTC_Mode 2;
BA_ "GenMsgSendType" BO_ 270 0;
BA_ "GenMsgCycleTime" BO_ 270 200;
BA_ "GenMsgCycleTimeFast" BO_ 270 40;
BA_ "GenMsgNrOfRepetition" BO_ 270 3;
BA_ "GenMsgStartDelayTime" BO_ 270 100;
BA_REL_ "GenSigTimeoutTime" BU_SG_REL_ CGW SG_ 270 C_TeleCrankingCmdIBOX 1500;
BA_ "SigDescription" SG_ 270 C_TeleCrankingCmdIBOX "Remote COntrol Message";
BA_ "Platform" SG_ 270 C_TeleCrankingCmdIBOX "";
BA_ "GenSigSendType" SG_ 270 C_TeleCrankingCmdIBOX 4;
BA_ "GenSigStartValue" SG_ 270 C_TeleCrankingCmdIBOX 3;
BA_ "Gatewaysignal" SG_ 270 C_TeleCrankingCmdIBOX 1;
BA_ "NmNetworkRequest" SG_ 270 C_TeleCrankingCmdIBOX 1;
BA_ "NmNetworkRequestHoldingTime" SG_ 270 C_TeleCrankingCmdIBOX 2;
BA_ "TimeoutValue" SG_ 270 C_TeleCrankingCmdIBOX "0x0";
BA_ "Validity" SG_ 270 C_TeleCrankingCmdIBOX 0;
BA_REL_ "GenSigTimeoutTime" BU_SG_REL_ CGW SG_ 270 C_FLSeatHeaterSW 1500;
BA_ "Platform" SG_ 270 C_FLSeatHeaterSW "";
BA_ "GenSigSendType" SG_ 270 C_FLSeatHeaterSW 3;
BA_ "Gatewaysignal" SG_ 270 C_FLSeatHeaterSW 1;
BA_ "TimeoutValue" SG_ 270 C_FLSeatHeaterSW "0x0";
BA_ "Validity" SG_ 270 C_FLSeatHeaterSW 2;
BA_REL_ "GenSigTimeoutTime" BU_SG_REL_ CGW SG_ 270 C_FLSeatCoolerSW 1500;
BA_ "Platform" SG_ 270 C_FLSeatCoolerSW "";
BA_ "GenSigSendType" SG_ 270 C_FLSeatCoolerSW 3;
BA_ "Gatewaysignal" SG_ 270 C_FLSeatCoolerSW 1;
BA_ "TimeoutValue" SG_ 270 C_FLSeatCoolerSW "0x0";
BA_ "Validity" SG_ 270 C_FLSeatCoolerSW 2;
BA_REL_ "GenSigTimeoutTime" BU_SG_REL_ CGW SG_ 270 C_FRSeatHeaterSW 1500;
BA_ "Platform" SG_ 270 C_FRSeatHeaterSW "";
BA_ "GenSigSendType" SG_ 270 C_FRSeatHeaterSW 3;
BA_ "Gatewaysignal" SG_ 270 C_FRSeatHeaterSW 1;
BA_ "TimeoutValue" SG_ 270 C_FRSeatHeaterSW "0x0";
BA_ "Validity" SG_ 270 C_FRSeatHeaterSW 2;
BA_REL_ "GenSigTimeoutTime" BU_SG_REL_ CGW SG_ 270 C_FRSeatCoolerSW 1500;
BA_ "Platform" SG_ 270 C_FRSeatCoolerSW "";
BA_ "GenSigSendType" SG_ 270 C_FRSeatCoolerSW 3;
BA_ "Gatewaysignal" SG_ 270 C_FRSeatCoolerSW 1;
BA_ "TimeoutValue" SG_ 270 C_FRSeatCoolerSW "0x0";
BA_ "Validity" SG_ 270 C_FRSeatCoolerSW 2;
BA_ "GenMsgSendType" BO_ 256 0;
BA_ "GenMsgCycleTime" BO_ 256 2000;
BA_ "GenMsgCycleTimeFast" BO_ 256 40;
BA_ "GenMsgNrOfRepetition" BO_ 256 3;
BA_ "GenMsgStartDelayTime" BO_ 256 610;
BA_REL_ "GenSigTimeoutTime" BU_SG_REL_ CGW SG_ 256 HU_Type 3500;
BA_REL_ "GenSigTimeoutTime" BU_SG_REL_ CLU SG_ 256 HU_Type 3500;
BA_ "Platform" SG_ 256 HU_Type "Compact AVN,D-Audio,DIS 2,Economic Audio 3.0,Integrated AVN1.0 High,Integrated AVN1.0 Mid,Premium AVN 2.0,Standard AVN 4.0,Standard Audio 3.0,Standard Audio 4.0,UVO3 (D-Audio Kia)";
BA_ "GenSigSendType" SG_ 256 HU_Type 4;
BA_ "GenSigStartValue" SG_ 256 HU_Type 255;
BA_ "NmNetworkRequest" SG_ 256 HU_Type 1;
BA_ "TimeoutValue" SG_ 256 HU_Type "0xFF";
BA_REL_ "GenSigTimeoutTime" BU_SG_REL_ CGW SG_ 256 HU_DistributeInfo 3500;
BA_REL_ "GenSigTimeoutTime" BU_SG_REL_ CLU SG_ 256 HU_DistributeInfo 3500;
BA_ "Platform" SG_ 256 HU_DistributeInfo "";
BA_ "GenSigSendType" SG_ 256 HU_DistributeInfo 4;
BA_ "GenSigStartValue" SG_ 256 HU_DistributeInfo 255;
BA_ "NmNetworkRequest" SG_ 256 HU_DistributeInfo 1;
BA_ "TimeoutValue" SG_ 256 HU_DistributeInfo "0xFF";
BA_REL_ "GenSigTimeoutTime" BU_SG_REL_ CGW SG_ 256 HU_OptionInfo 3500;
BA_REL_ "GenSigTimeoutTime" BU_SG_REL_ CLU SG_ 256 HU_OptionInfo 3500;
BA_ "SigDescription" SG_ 256 HU_OptionInfo "Bit0 : Navi (0: Not Support / 1: Support)
Bit1 : USM (0: Not Support / 1: Support)
Bit2 : TMS (0: Not Support / 1: Support)
Bit3 : Multi Profile (0: Not Support(No Profile or Single Profile)  / 1: Support)
Bit4 : Camera Guideline (0: Displayed by Camera / 1: Displayed by H/U)
Bit5~Bit14 : Reserved
Bit15 : 1 Invalid";
BA_ "Platform" SG_ 256 HU_OptionInfo "";
BA_ "GenSigSendType" SG_ 256 HU_OptionInfo 3;
BA_ "TimeoutValue" SG_ 256 HU_OptionInfo "0x8000";
BA_ "GenMsgILSupport" BO_ 1260 0;
BA_ "TpMessage" BO_ 1260 1;
BA_ "TpTxIndex" BO_ 1260 6;
BA_REL_ "GenSigTimeoutTime" BU_SG_REL_ CLU SG_ 1260 Byte0_TCP_4EC 0;
BA_ "Platform" SG_ 1260 Byte0_TCP_4EC "";
BA_ "GenMsgILSupport" BO_ 1260 0;
BA_ "TpMessage" BO_ 1260 1;
BA_ "TpTxIndex" BO_ 1260 6;
BA_REL_ "GenSigTimeoutTime" BU_SG_REL_ CLU SG_ 1260 Byte1_Data_4EC 0;
BA_ "Platform" SG_ 1260 Byte1_Data_4EC "";
BA_ "GenMsgILSupport" BO_ 1260 0;
BA_ "TpMessage" BO_ 1260 1;
BA_ "TpTxIndex" BO_ 1260 6;
BA_REL_ "GenSigTimeoutTime" BU_SG_REL_ CLU SG_ 1260 Byte2_Data_4EC 0;
BA_ "Platform" SG_ 1260 Byte2_Data_4EC "";
BA_ "GenMsgILSupport" BO_ 1260 0;
BA_ "TpMessage" BO_ 1260 1;
BA_ "TpTxIndex" BO_ 1260 6;
BA_REL_ "GenSigTimeoutTime" BU_SG_REL_ CLU SG_ 1260 Byte3_Data_4EC 0;
BA_ "Platform" SG_ 1260 Byte3_Data_4EC "";
BA_ "GenMsgILSupport" BO_ 1260 0;
BA_ "TpMessage" BO_ 1260 1;
BA_ "TpTxIndex" BO_ 1260 6;
BA_REL_ "GenSigTimeoutTime" BU_SG_REL_ CLU SG_ 1260 Byte4_Data_4EC 0;
BA_ "Platform" SG_ 1260 Byte4_Data_4EC "";
BA_ "GenMsgILSupport" BO_ 1260 0;
BA_ "TpMessage" BO_ 1260 1;
BA_ "TpTxIndex" BO_ 1260 6;
BA_REL_ "GenSigTimeoutTime" BU_SG_REL_ CLU SG_ 1260 Byte5_Data_4EC 0;
BA_ "Platform" SG_ 1260 Byte5_Data_4EC "";
BA_ "GenMsgILSupport" BO_ 1260 0;
BA_ "TpMessage" BO_ 1260 1;
BA_ "TpTxIndex" BO_ 1260 6;
BA_REL_ "GenSigTimeoutTime" BU_SG_REL_ CLU SG_ 1260 Byte6_Data_4EC 0;
BA_ "Platform" SG_ 1260 Byte6_Data_4EC "";
BA_ "GenMsgILSupport" BO_ 1260 0;
BA_ "TpMessage" BO_ 1260 1;
BA_ "TpTxIndex" BO_ 1260 6;
BA_REL_ "GenSigTimeoutTime" BU_SG_REL_ CLU SG_ 1260 Byte7_Data_4EC 0;
BA_ "Platform" SG_ 1260 Byte7_Data_4EC "";
BA_ "GenMsgILSupport" BO_ 1270 0;
BA_ "TpMessage" BO_ 1270 1;
BA_ "TpTxIndex" BO_ 1270 46;
BA_REL_ "GenSigTimeoutTime" BU_SG_REL_ CLU SG_ 1270 Byte0_TCP_4F6 0;
BA_ "Platform" SG_ 1270 Byte0_TCP_4F6 "";
BA_ "GenMsgILSupport" BO_ 1270 0;
BA_ "TpMessage" BO_ 1270 1;
BA_ "TpTxIndex" BO_ 1270 46;
BA_REL_ "GenSigTimeoutTime" BU_SG_REL_ CLU SG_ 1270 Byte1_Data_4F6 0;
BA_ "Platform" SG_ 1270 Byte1_Data_4F6 "";
BA_ "GenMsgILSupport" BO_ 1270 0;
BA_ "TpMessage" BO_ 1270 1;
BA_ "TpTxIndex" BO_ 1270 46;
BA_REL_ "GenSigTimeoutTime" BU_SG_REL_ CLU SG_ 1270 Byte2_Data_4F6 0;
BA_ "Platform" SG_ 1270 Byte2_Data_4F6 "";
BA_ "GenMsgILSupport" BO_ 1270 0;
BA_ "TpMessage" BO_ 1270 1;
BA_ "TpTxIndex" BO_ 1270 46;
BA_REL_ "GenSigTimeoutTime" BU_SG_REL_ CLU SG_ 1270 Byte3_Data_4F6 0;
BA_ "Platform" SG_ 1270 Byte3_Data_4F6 "";
BA_ "GenMsgILSupport" BO_ 1270 0;
BA_ "TpMessage" BO_ 1270 1;
BA_ "TpTxIndex" BO_ 1270 46;
BA_REL_ "GenSigTimeoutTime" BU_SG_REL_ CLU SG_ 1270 Byte4_Data_4F6 0;
BA_ "Platform" SG_ 1270 Byte4_Data_4F6 "";
BA_ "GenMsgILSupport" BO_ 1270 0;
BA_ "TpMessage" BO_ 1270 1;
BA_ "TpTxIndex" BO_ 1270 46;
BA_REL_ "GenSigTimeoutTime" BU_SG_REL_ CLU SG_ 1270 Byte5_Data_4F6 0;
BA_ "Platform" SG_ 1270 Byte5_Data_4F6 "";
BA_ "GenMsgILSupport" BO_ 1270 0;
BA_ "TpMessage" BO_ 1270 1;
BA_ "TpTxIndex" BO_ 1270 46;
BA_REL_ "GenSigTimeoutTime" BU_SG_REL_ CLU SG_ 1270 Byte6_Data_4F6 0;
BA_ "Platform" SG_ 1270 Byte6_Data_4F6 "";
BA_ "GenMsgILSupport" BO_ 1270 0;
BA_ "TpMessage" BO_ 1270 1;
BA_ "TpTxIndex" BO_ 1270 46;
BA_REL_ "GenSigTimeoutTime" BU_SG_REL_ CLU SG_ 1270 Byte7_Data_4F6 0;
BA_ "Platform" SG_ 1270 Byte7_Data_4F6 "";
BA_ "GenMsgILSupport" BO_ 1264 0;
BA_ "TpMessage" BO_ 1264 1;
BA_ "TpTxIndex" BO_ 1264 38;
BA_REL_ "GenSigTimeoutTime" BU_SG_REL_ CLU SG_ 1264 Byte0_TCP_4F0 0;
BA_ "Platform" SG_ 1264 Byte0_TCP_4F0 "";
BA_ "GenMsgILSupport" BO_ 1264 0;
BA_ "TpMessage" BO_ 1264 1;
BA_ "TpTxIndex" BO_ 1264 38;
BA_REL_ "GenSigTimeoutTime" BU_SG_REL_ CLU SG_ 1264 Byte1_Data_4F0 0;
BA_ "Platform" SG_ 1264 Byte1_Data_4F0 "";
BA_ "GenMsgILSupport" BO_ 1264 0;
BA_ "TpMessage" BO_ 1264 1;
BA_ "TpTxIndex" BO_ 1264 38;
BA_REL_ "GenSigTimeoutTime" BU_SG_REL_ CLU SG_ 1264 Byte2_Data_4F0 0;
BA_ "Platform" SG_ 1264 Byte2_Data_4F0 "";
BA_ "GenMsgILSupport" BO_ 1264 0;
BA_ "TpMessage" BO_ 1264 1;
BA_ "TpTxIndex" BO_ 1264 38;
BA_REL_ "GenSigTimeoutTime" BU_SG_REL_ CLU SG_ 1264 Byte3_Data_4F0 0;
BA_ "Platform" SG_ 1264 Byte3_Data_4F0 "";
BA_ "GenMsgILSupport" BO_ 1264 0;
BA_ "TpMessage" BO_ 1264 1;
BA_ "TpTxIndex" BO_ 1264 38;
BA_REL_ "GenSigTimeoutTime" BU_SG_REL_ CLU SG_ 1264 Byte4_Data_4F0 0;
BA_ "Platform" SG_ 1264 Byte4_Data_4F0 "";
BA_ "GenMsgILSupport" BO_ 1264 0;
BA_ "TpMessage" BO_ 1264 1;
BA_ "TpTxIndex" BO_ 1264 38;
BA_REL_ "GenSigTimeoutTime" BU_SG_REL_ CLU SG_ 1264 Byte5_Data_4F0 0;
BA_ "Platform" SG_ 1264 Byte5_Data_4F0 "";
BA_ "GenMsgILSupport" BO_ 1264 0;
BA_ "TpMessage" BO_ 1264 1;
BA_ "TpTxIndex" BO_ 1264 38;
BA_REL_ "GenSigTimeoutTime" BU_SG_REL_ CLU SG_ 1264 Byte6_Data_4F0 0;
BA_ "Platform" SG_ 1264 Byte6_Data_4F0 "";
BA_ "GenMsgILSupport" BO_ 1264 0;
BA_ "TpMessage" BO_ 1264 1;
BA_ "TpTxIndex" BO_ 1264 38;
BA_REL_ "GenSigTimeoutTime" BU_SG_REL_ CLU SG_ 1264 Byte7_Data_4F0 0;
BA_ "Platform" SG_ 1264 Byte7_Data_4F0 "";
BA_ "GenMsgILSupport" BO_ 1266 0;
BA_ "TpMessage" BO_ 1266 1;
BA_ "TpTxIndex" BO_ 1266 44;
BA_REL_ "GenSigTimeoutTime" BU_SG_REL_ CLU SG_ 1266 Byte0_TCP_4F2 0;
BA_ "Platform" SG_ 1266 Byte0_TCP_4F2 "";
BA_ "GenMsgILSupport" BO_ 1266 0;
BA_ "TpMessage" BO_ 1266 1;
BA_ "TpTxIndex" BO_ 1266 44;
BA_REL_ "GenSigTimeoutTime" BU_SG_REL_ CLU SG_ 1266 Byte1_Data_4F2 0;
BA_ "Platform" SG_ 1266 Byte1_Data_4F2 "";
BA_ "GenMsgILSupport" BO_ 1266 0;
BA_ "TpMessage" BO_ 1266 1;
BA_ "TpTxIndex" BO_ 1266 44;
BA_REL_ "GenSigTimeoutTime" BU_SG_REL_ CLU SG_ 1266 Byte2_Data_4F2 0;
BA_ "Platform" SG_ 1266 Byte2_Data_4F2 "";
BA_ "GenMsgILSupport" BO_ 1266 0;
BA_ "TpMessage" BO_ 1266 1;
BA_ "TpTxIndex" BO_ 1266 44;
BA_REL_ "GenSigTimeoutTime" BU_SG_REL_ CLU SG_ 1266 Byte3_Data_4F2 0;
BA_ "Platform" SG_ 1266 Byte3_Data_4F2 "";
BA_ "GenMsgILSupport" BO_ 1266 0;
BA_ "TpMessage" BO_ 1266 1;
BA_ "TpTxIndex" BO_ 1266 44;
BA_REL_ "GenSigTimeoutTime" BU_SG_REL_ CLU SG_ 1266 Byte4_Data_4F2 0;
BA_ "Platform" SG_ 1266 Byte4_Data_4F2 "";
BA_ "GenMsgILSupport" BO_ 1266 0;
BA_ "TpMessage" BO_ 1266 1;
BA_ "TpTxIndex" BO_ 1266 44;
BA_REL_ "GenSigTimeoutTime" BU_SG_REL_ CLU SG_ 1266 Byte5_Data_4F2 0;
BA_ "Platform" SG_ 1266 Byte5_Data_4F2 "";
BA_ "GenMsgILSupport" BO_ 1266 0;
BA_ "TpMessage" BO_ 1266 1;
BA_ "TpTxIndex" BO_ 1266 44;
BA_REL_ "GenSigTimeoutTime" BU_SG_REL_ CLU SG_ 1266 Byte6_Data_4F2 0;
BA_ "Platform" SG_ 1266 Byte6_Data_4F2 "";
BA_ "GenMsgILSupport" BO_ 1266 0;
BA_ "TpMessage" BO_ 1266 1;
BA_ "TpTxIndex" BO_ 1266 44;
BA_REL_ "GenSigTimeoutTime" BU_SG_REL_ CLU SG_ 1266 Byte7_Data_4F2 0;
BA_ "Platform" SG_ 1266 Byte7_Data_4F2 "";
BA_ "GenMsgILSupport" BO_ 1256 0;
BA_ "TpMessage" BO_ 1256 1;
BA_ "TpTxIndex" BO_ 1256 36;
BA_REL_ "GenSigTimeoutTime" BU_SG_REL_ CLU SG_ 1256 Byte0_TCP_4E8 0;
BA_ "Platform" SG_ 1256 Byte0_TCP_4E8 "";
BA_ "GenMsgILSupport" BO_ 1256 0;
BA_ "TpMessage" BO_ 1256 1;
BA_ "TpTxIndex" BO_ 1256 36;
BA_REL_ "GenSigTimeoutTime" BU_SG_REL_ CLU SG_ 1256 Byte1_Data_4E8 0;
BA_ "Platform" SG_ 1256 Byte1_Data_4E8 "";
BA_ "GenMsgILSupport" BO_ 1256 0;
BA_ "TpMessage" BO_ 1256 1;
BA_ "TpTxIndex" BO_ 1256 36;
BA_REL_ "GenSigTimeoutTime" BU_SG_REL_ CLU SG_ 1256 Byte2_Data_4E8 0;
BA_ "Platform" SG_ 1256 Byte2_Data_4E8 "";
BA_ "GenMsgILSupport" BO_ 1256 0;
BA_ "TpMessage" BO_ 1256 1;
BA_ "TpTxIndex" BO_ 1256 36;
BA_REL_ "GenSigTimeoutTime" BU_SG_REL_ CLU SG_ 1256 Byte3_Data_4E8 0;
BA_ "Platform" SG_ 1256 Byte3_Data_4E8 "";
BA_ "GenMsgILSupport" BO_ 1256 0;
BA_ "TpMessage" BO_ 1256 1;
BA_ "TpTxIndex" BO_ 1256 36;
BA_REL_ "GenSigTimeoutTime" BU_SG_REL_ CLU SG_ 1256 Byte4_Data_4E8 0;
BA_ "Platform" SG_ 1256 Byte4_Data_4E8 "";
BA_ "GenMsgILSupport" BO_ 1256 0;
BA_ "TpMessage" BO_ 1256 1;
BA_ "TpTxIndex" BO_ 1256 36;
BA_REL_ "GenSigTimeoutTime" BU_SG_REL_ CLU SG_ 1256 Byte5_Data_4E8 0;
BA_ "Platform" SG_ 1256 Byte5_Data_4E8 "";
BA_ "GenMsgILSupport" BO_ 1256 0;
BA_ "TpMessage" BO_ 1256 1;
BA_ "TpTxIndex" BO_ 1256 36;
BA_REL_ "GenSigTimeoutTime" BU_SG_REL_ CLU SG_ 1256 Byte6_Data_4E8 0;
BA_ "Platform" SG_ 1256 Byte6_Data_4E8 "";
BA_ "GenMsgILSupport" BO_ 1256 0;
BA_ "TpMessage" BO_ 1256 1;
BA_ "TpTxIndex" BO_ 1256 36;
BA_REL_ "GenSigTimeoutTime" BU_SG_REL_ CLU SG_ 1256 Byte7_Data_4E8 0;
BA_ "Platform" SG_ 1256 Byte7_Data_4E8 "";
BA_ "GenMsgILSupport" BO_ 1262 0;
BA_ "TpMessage" BO_ 1262 1;
BA_ "TpTxIndex" BO_ 1262 39;
BA_REL_ "GenSigTimeoutTime" BU_SG_REL_ CLU SG_ 1262 Byte0_TCP_4EE 0;
BA_ "Platform" SG_ 1262 Byte0_TCP_4EE "";
BA_ "GenMsgILSupport" BO_ 1262 0;
BA_ "TpMessage" BO_ 1262 1;
BA_ "TpTxIndex" BO_ 1262 39;
BA_REL_ "GenSigTimeoutTime" BU_SG_REL_ CLU SG_ 1262 Byte1_Data_4EE 0;
BA_ "Platform" SG_ 1262 Byte1_Data_4EE "";
BA_ "GenMsgILSupport" BO_ 1262 0;
BA_ "TpMessage" BO_ 1262 1;
BA_ "TpTxIndex" BO_ 1262 39;
BA_REL_ "GenSigTimeoutTime" BU_SG_REL_ CLU SG_ 1262 Byte2_Data_4EE 0;
BA_ "Platform" SG_ 1262 Byte2_Data_4EE "";
BA_ "GenMsgILSupport" BO_ 1262 0;
BA_ "TpMessage" BO_ 1262 1;
BA_ "TpTxIndex" BO_ 1262 39;
BA_REL_ "GenSigTimeoutTime" BU_SG_REL_ CLU SG_ 1262 Byte3_Data_4EE 0;
BA_ "Platform" SG_ 1262 Byte3_Data_4EE "";
BA_ "GenMsgILSupport" BO_ 1262 0;
BA_ "TpMessage" BO_ 1262 1;
BA_ "TpTxIndex" BO_ 1262 39;
BA_REL_ "GenSigTimeoutTime" BU_SG_REL_ CLU SG_ 1262 Byte4_Data_4EE 0;
BA_ "Platform" SG_ 1262 Byte4_Data_4EE "";
BA_ "GenMsgILSupport" BO_ 1262 0;
BA_ "TpMessage" BO_ 1262 1;
BA_ "TpTxIndex" BO_ 1262 39;
BA_REL_ "GenSigTimeoutTime" BU_SG_REL_ CLU SG_ 1262 Byte5_Data_4EE 0;
BA_ "Platform" SG_ 1262 Byte5_Data_4EE "";
BA_ "GenMsgILSupport" BO_ 1262 0;
BA_ "TpMessage" BO_ 1262 1;
BA_ "TpTxIndex" BO_ 1262 39;
BA_REL_ "GenSigTimeoutTime" BU_SG_REL_ CLU SG_ 1262 Byte6_Data_4EE 0;
BA_ "Platform" SG_ 1262 Byte6_Data_4EE "";
BA_ "GenMsgILSupport" BO_ 1262 0;
BA_ "TpMessage" BO_ 1262 1;
BA_ "TpTxIndex" BO_ 1262 39;
BA_REL_ "GenSigTimeoutTime" BU_SG_REL_ CLU SG_ 1262 Byte7_Data_4EE 0;
BA_ "Platform" SG_ 1262 Byte7_Data_4EE "";
BA_ "GenMsgILSupport" BO_ 1254 0;
BA_ "TpMessage" BO_ 1254 1;
BA_ "TpTxIndex" BO_ 1254 12;
BA_REL_ "GenSigTimeoutTime" BU_SG_REL_ CLU SG_ 1254 Byte0_TCP_4E6 0;
BA_ "Platform" SG_ 1254 Byte0_TCP_4E6 "";
BA_ "GenMsgILSupport" BO_ 1254 0;
BA_ "TpMessage" BO_ 1254 1;
BA_ "TpTxIndex" BO_ 1254 12;
BA_REL_ "GenSigTimeoutTime" BU_SG_REL_ CLU SG_ 1254 Byte1_Data_4E6 0;
BA_ "Platform" SG_ 1254 Byte1_Data_4E6 "";
BA_ "GenMsgILSupport" BO_ 1254 0;
BA_ "TpMessage" BO_ 1254 1;
BA_ "TpTxIndex" BO_ 1254 12;
BA_REL_ "GenSigTimeoutTime" BU_SG_REL_ CLU SG_ 1254 Byte2_Data_4E6 0;
BA_ "Platform" SG_ 1254 Byte2_Data_4E6 "";
BA_ "GenMsgILSupport" BO_ 1254 0;
BA_ "TpMessage" BO_ 1254 1;
BA_ "TpTxIndex" BO_ 1254 12;
BA_REL_ "GenSigTimeoutTime" BU_SG_REL_ CLU SG_ 1254 Byte3_Data_4E6 0;
BA_ "Platform" SG_ 1254 Byte3_Data_4E6 "";
BA_ "GenMsgILSupport" BO_ 1254 0;
BA_ "TpMessage" BO_ 1254 1;
BA_ "TpTxIndex" BO_ 1254 12;
BA_REL_ "GenSigTimeoutTime" BU_SG_REL_ CLU SG_ 1254 Byte4_Data_4E6 0;
BA_ "Platform" SG_ 1254 Byte4_Data_4E6 "";
BA_ "GenMsgILSupport" BO_ 1254 0;
BA_ "TpMessage" BO_ 1254 1;
BA_ "TpTxIndex" BO_ 1254 12;
BA_REL_ "GenSigTimeoutTime" BU_SG_REL_ CLU SG_ 1254 Byte5_Data_4E6 0;
BA_ "Platform" SG_ 1254 Byte5_Data_4E6 "";
BA_ "GenMsgILSupport" BO_ 1254 0;
BA_ "TpMessage" BO_ 1254 1;
BA_ "TpTxIndex" BO_ 1254 12;
BA_REL_ "GenSigTimeoutTime" BU_SG_REL_ CLU SG_ 1254 Byte6_Data_4E6 0;
BA_ "Platform" SG_ 1254 Byte6_Data_4E6 "";
BA_ "GenMsgILSupport" BO_ 1254 0;
BA_ "TpMessage" BO_ 1254 1;
BA_ "TpTxIndex" BO_ 1254 12;
BA_REL_ "GenSigTimeoutTime" BU_SG_REL_ CLU SG_ 1254 Byte7_Data_4E6 0;
BA_ "Platform" SG_ 1254 Byte7_Data_4E6 "";
VAL_ 305 DATC_DrTempDispC 0 "Off (Blank display)" 1 "LO" 2 "PHY=(HEX*0.5 + 14)" 3 "PHY=(HEX*0.5 + 14)" 4 "PHY=(HEX*0.5 + 14)" 5 "PHY=(HEX*0.5 + 14)" 6 "PHY=(HEX*0.5 + 14)" 7 "PHY=(HEX*0.5 + 14)" 8 "PHY=(HEX*0.5 + 14)" 9 "PHY=(HEX*0.5 + 14)" 10 "PHY=(HEX*0.5 + 14)" 11 "PHY=(HEX*0.5 + 14)" 12 "PHY=(HEX*0.5 + 14)" 13 "PHY=(HEX*0.5 + 14)" 14 "PHY=(HEX*0.5 + 14)" 15 "PHY=(HEX*0.5 + 14)" 16 "PHY=(HEX*0.5 + 14)" 17 "PHY=(HEX*0.5 + 14)" 18 "PHY=(HEX*0.5 + 14)" 19 "PHY=(HEX*0.5 + 14)" 20 "PHY=(HEX*0.5 + 14)" 21 "PHY=(HEX*0.5 + 14)" 22 "PHY=(HEX*0.5 + 14)" 23 "PHY=(HEX*0.5 + 14)" 24 "PHY=(HEX*0.5 + 14)" 25 "PHY=(HEX*0.5 + 14)" 26 "PHY=(HEX*0.5 + 14)" 27 "PHY=(HEX*0.5 + 14)" 28 "PHY=(HEX*0.5 + 14)" 29 "PHY=(HEX*0.5 + 14)" 30 "PHY=(HEX*0.5 + 14)" 31 "PHY=(HEX*0.5 + 14)" 32 "PHY=(HEX*0.5 + 14)" 33 "PHY=(HEX*0.5 + 14)" 34 "PHY=(HEX*0.5 + 14)" 35 "PHY=(HEX*0.5 + 14)" 36 "PHY=(HEX*0.5 + 14)" 37 "0x25~0xFD:reserved" 253 "0x25~0xFD:reserved" 254 "HI" 255 "Invalid" ;
VAL_ 305 DATC_DrTempDispF 0 "Off (Blank display)" 1 "LO" 2 "PHY=HEX*1+56" 3 "PHY=HEX*1+56" 4 "PHY=HEX*1+56" 5 "PHY=HEX*1+56" 6 "PHY=HEX*1+56" 7 "PHY=HEX*1+56" 8 "PHY=HEX*1+56" 9 "PHY=HEX*1+56" 10 "PHY=HEX*1+56" 11 "PHY=HEX*1+56" 12 "PHY=HEX*1+56" 13 "PHY=HEX*1+56" 14 "PHY=HEX*1+56" 15 "PHY=HEX*1+56" 16 "PHY=HEX*1+56" 17 "PHY=HEX*1+56" 18 "PHY=HEX*1+56" 19 "PHY=HEX*1+56" 20 "PHY=HEX*1+56" 21 "PHY=HEX*1+56" 22 "PHY=HEX*1+56" 23 "PHY=HEX*1+56" 24 "PHY=HEX*1+56" 25 "PHY=HEX*1+56" 26 "PHY=HEX*1+56" 27 "PHY=HEX*1+56" 28 "PHY=HEX*1+56" 29 "PHY=HEX*1+56" 30 "PHY=HEX*1+56" 31 "PHY=HEX*1+56" 32 "PHY=HEX*1+56" 33 "PHY=HEX*1+56" 34 "PHY=HEX*1+56" 35 "PHY=HEX*1+56" 36 "PHY=HEX*1+56" 37 "0x25~0xFD:reserved" 253 "0x25~0xFD:reserved" 254 "HI" 255 "Invalid" ;
VAL_ 306 DATC_ModeDisp 0 "Off" 1 "VENT" 2 "B/L" 3 "FLOOR" 4 "MIX" 5 "DEF" 6 "AUTO DEFOG" 7 "7MODE DEF VENT" 8 "7MODE DEF FLOOR" 9 "7MODE DEF VENT FLOOR" 10 "7MODE DEF" 11 "Reserved" 12 "Reserved" 13 "Reserved" 14 "Reserved" 15 "Invalid" ;
VAL_ 306 DATC_TempUnit 0 "Off" 1 "Centigrade" 2 "Fahrenheit" 3 "invalid" ;
VAL_ 306 DATC_AirCleaningSystemStatus 0 "Air Cleaning System Off" 1 "Air Cleaning System On" 2 "Air Cleaning System Not Support" 3 "Invalid" ;
VAL_ 306 DATC_AutoDisp 0 "AUTO Off" 1 "AUTO On" 2 "reserved" 3 "Invalid" ;
VAL_ 306 DATC_IntakeDisp 0 "REC OFF(FRE ON)" 1 "REC ON" 2 "reserved" 3 "Invalid" ;
VAL_ 306 DATC_AcDisp 0 "AC OFF" 1 "AC ON" 2 "reserved" 3 "Invalid" ;
VAL_ 306 DATC_OpSts 0 "DATC Off (Power Down)" 1 "DATC Normal" 2 "DATC System Off (Blower Off)" 3 "DATC Self Diagnosis" 4 "Not Used" 5 "reserved" 6 "reserved" 7 "Inavalid" ;
VAL_ 306 DATC_FrDefLed 0 "Off" 1 "On" 2 "Reserved" 3 "Invalid" ;
VAL_ 306 DATC_MainBlowerDisp 0 "Off" 1 "0 level" 2 "1 level" 3 "2 level" 4 "3 level" 5 "4 level" 6 "5 level" 7 "6 level" 8 "7 level" 9 "8 level" 10 "reserved" 11 "reserved" 12 "reserved" 13 "reserved" 14 "reserved" 15 "Invalid" ;
VAL_ 307 DATC_SelfDiagDisp 0 "OFF (Blank Display)" 1 "0x1~0xFE:Error Code Value(0~253)" 254 "0x1~0xFE:Error Code Value(0~253)" 255 "Invalid" ;
VAL_ 307 DATC_Variant 0 "0x0~0xFF:REFER TO COMMENT" 255 "0x0~0xFF:REFER TO COMMENT" ;
VAL_ 309 CF_DATC_TempDisp_Sts 0 "OLD Set Temp Display Range" 1 "NEW Set Temp Display Range" 2 "Not Used" 3 "Invalid" ;
VAL_ 166 C_SMK_AuthReq 0 "None" 1 "Auth Request" 2 "Reserved" 3 "Reserved" 4 "Reserved" 5 "Reserved" 6 "Reserved" 7 "Invalid" ;
VAL_ 167 C_PassiveAccessLock 0 "None" 1 "Lock" 2 "PassiveTrunkLock" 3 "Invalid" ;
VAL_ 167 C_PassiveAccessUnlock 0 "None" 1 "UnLock" 2 "Unlock only DRV Door" 3 "PIC_Key_Reminder" 4 "Reserved" 5 "Reserved" 6 "Reserved" 7 "Invalid" ;
VAL_ 167 C_SMK_AuthMethod 0 "Non Auth" 1 "Auth by FOB" 2 "Auth by TP" 3 "Auth By FP" 4 "Auth By NFC" 5 "Auth Fail" 6 "Auth By BLE(CHINA)" 7 "Invalid" ;
VAL_ 167 C_IBUISKLearnFB 0 "Defulat(Normal)" 1 "Positive" 2 "Mismatch ISK" 3 "Mismatch RN" 4 "Save Failed ISK" 5 "Time Out" 6 "Reserved" 7 "Reserved" 8 "Reserved" 9 "Reserved" 10 "Reserved" 11 "Reserved" 12 "Reserved" 13 "Reserved" 14 "Reserved" 15 "Invalid" ;
VAL_ 402 C_AuthState 0 "No Auth" 1 "Preauthentication" 2 "Authentication" 3 "Fast Restart" 4 "Reserved" 5 "Reserved" 6 "Reserved" 7 "Invalid" ;
VAL_ 402 C_IBUISKLearnState 0 "Default(Normal)" 1 "Learning" 2 "Invalid" 3 "Reserved" ;
VAL_ 402 C_SMKBLECrankingState 0 "Normal Mode" 1 "BLE Cranking Mode" 2 "Reserved" 3 "Invalid" ;
VAL_ 402 C_SMKBLEEngineRunning 0 "Off" 1 "BLE Running" 2 "Reserved" 3 "Invalid" ;
VAL_ 402 C_AstToggleButton 0 "Off" 1 "On" 2 "Reserved" 3 "Invalid" ;
VAL_ 402 C_DrvToggleButton 0 "Off" 1 "On" 2 "Reserved" 3 "Invalid" ;
VAL_ 402 C_BrakeSW 0 "Off" 1 "On" 2 "Reserved" 3 "Invalid" ;
VAL_ 402 C_SSBSW1 0 "Released" 1 "Pressed" 2 "Reserved" 3 "Invalid" ;
VAL_ 402 C_SSBSW2 0 "Released" 1 "Pressed" 2 "Reserved" 3 "Invalid" ;
VAL_ 402 C_TrunkTgOtrReleaseSW 0 "Off" 1 "On" 2 "Reserved" 3 "Invalid" ;
VAL_ 402 C_TerminalsManagerState 0 "Off" 1 "OFF_TO_START" 16 "ENGINE_RUNNING" 31 "Invalid" 2 "WAIT_ESCL_UNLOCK_ACC" 3 "ACC" 4 "ACC_SEARCH" 5 "ACC_TO_START" 6 "IGN" 7 "IGN_SEARCH" 8 "WAIT_ESCL_UNLOCK_OFF_TO_START" 9 "WAIT_ESCL_UNLOCK_START" 10 "WAIT_IGN1_ACC" 11 "WAIT_IGN1_ACC_SEARCH" 12 "WAIT_IGN1_ACC_TO_START" 13 "WAIT_IGN1_UNLOCK_OFF_TO_START" 14 "WAIT_IGN1_UNLOCK_START" 15 "START" ;
VAL_ 1390 C_VehicleSpeed 0 "0x0~0xFE:Km_h" 254 "0x0~0xFE:Km_h" 255 "Error" ;
VAL_ 1390 C_Odometer 0 "0x0~0xFFFFFE:1677721.4" 16777214 "0x0~0xFFFFFE:1677721.4" 16777215 "Error" ;
VAL_ 1390 CF_Clu_SPEED_UNIT 0 "kph" 1 "mph" 2 "reserved" 3 "invalid" ;
VAL_ 1390 CF_Clu_Vanz 0 "0x0~0x1FE:speed" 510 "0x0~0x1FE:speed" 511 "invalid" ;
VAL_ 1390 CF_Clu_DisplaySpeed 0 "0x0~0x1FE:Speed" 510 "0x0~0x1FE:Speed" 511 "Error" ;
VAL_ 413 C_TSigLhSw 0 "Off" 1 "On" 2 "reserved" 3 "Invalid" ;
VAL_ 413 C_TSigRhSw 0 "Off" 1 "On" 2 "reserved" 3 "Invalid" ;
VAL_ 414 C_DrvSeatHeatOption 0 "Init" 1 "Heat Only 2Step" 2 "Heat Only 3Step" 3 "Vent Only 2Step" 4 "Vent Only 3Step" 5 "Heat and Vent 2Step" 6 "Heat and Vent 3Step" 7 "Invalid" ;
VAL_ 414 C_DrvSeatHeatState 0 "Init" 1 "Unused" 2 "Seat Heat&Vent OFF" 3 "Seat_Vent_Low" 4 "Seat_Vent_Mid" 5 "Seat_Vent_High" 6 "Seat_Heat_Low" 7 "Seat_Heat_Mid" 8 "Seat_Heat_High" 9 "Unused" 10 "Unused" 11 "Unused" 12 "Unused" 13 "Unused" 14 "Unused" 15 "Invalid" ;
VAL_ 414 C_AstSeatHeatOption 0 "Init" 1 "Heat Only 2Step" 2 "Heat Only 3Step" 3 "Vent Only 2Step" 4 "Vent Only 3Step" 5 "Heat and Vent 2Step" 6 "Heat and Vent 3Step" 7 "Invalid" ;
VAL_ 414 C_AstSeatHeatState 0 "Init" 1 "Unused" 2 "Seat Heat&Vent OFF" 3 "Seat_Vent_Low" 4 "Seat_Vent_Mid" 5 "Seat_Vent_High" 6 "Seat_Heat_Low" 7 "Seat_Heat_Mid" 8 "Seat_Heat_High" 9 "Unused" 10 "Unused" 11 "Unused" 12 "Unused" 13 "Unused" 14 "Unused" 15 "Invalid" ;
VAL_ 415 Batt_SoCWarningAlertMsgReq 0 "Default" 1 "Alert" 2 "Warning" 3 "Invalid" ;
VAL_ 415 Batt_SoC 0 "0x0~0x64:0~100%" 100 "0x0~0x64:0~100%" 101 "0x65~0xFE:reserved" 254 "0x65~0xFE:reserved" 255 "Invalid" ;
VAL_ 415 ICUPowerAutoCutMode 0 "Factory Mode" 1 "Dealer Mode" 2 "Customer Mode" 3 "Invaild" ;
VAL_ 415 Batt_SoCAlertValue 0 "0x0~0x64:0 ~ 100%" 100 "0x0~0x64:0 ~ 100%" 101 "0x65~0xFE:Reserved" 254 "0x65~0xFE:Reserved" 255 "Invaild" ;
VAL_ 294 CAM_Status 0 "Normal" 1 "Fault" 2 "Reserved" 3 "Invalid" ;
VAL_ 400 C_BLECrankingCmd 0 "Default" 1 "Cranking" 2 "Stop" 3 "Invalid" ;
VAL_ 400 C_BLEDeviceDetectionStatus 0 "Not Detected" 1 "Detected" 2 "Detected" 3 "Detected" 4 "Detected" 5 "Detected" 6 "Detected" 7 "Invalid" ;
VAL_ 400 C_BLEOption 0 "None" 1 "NFC Option" 2 "FP Option" 3 "BLE Option" 4 "Reserved" 5 "Reserved" 6 "Reserved" 7 "Invalid" ;
VAL_ 400 C_BLE_ProfileIDRValue 0 "Default" 1 "Guest" 2 "Profile1" 3 "Profile2" 4 "Reserved" 5 "Reserved" 6 "Reserved" 7 "Reserved" 8 "Reserved" 9 "Reserved" 10 "Reserved" 11 "Reserved" 12 "Reserved" 13 "Reserved" 14 "Reserved" 15 "Invalid" ;
VAL_ 400 C_BLE_ReadyToSendAuth 0 "None" 1 "Ready to Send data" 2 "Reserved" 3 "Invalid" ;
VAL_ 400 C_BLEISKLearnState 0 "Default(Normal)" 1 "Learning" 2 "Invalid" 3 "Reserved" ;
VAL_ 277 TBT_Display_Type 0 "No Symbol" 1 "No info" 16 "Turn Combination2" 17 "Exit-R" 18 "Exit-L" 19 "Exit Combination1-R" 20 "Exit Combination1-L" 21 "Exit Combination2-R" 22 "Exit Combination2-L" 23 "Srv Road-R" 24 "Srv Road-L" 25 "Fork-2" 26 "Fork-3" 27 "Roundabout Trs-R" 28 "Roundabout Trs-L" 29 "Square Trs-R" 30 "Square Trs-L" 31 "U turn" 2 "Direction to Dest" 32 "Exit Roundabout Trs-R" 33 "Exit Roundabout Trs-L" 34 "Prepare Turn" 35 "Prepare Roundabout" 36 "Prepare Exit" 37 "Prepare Square" 38 "Prepare U Turn" 39 "Exit Ramp Up-R" 40 "Exit Ramp Down-R" 41 "Exit Ramp Up-L" 42 "Exit Ramp Down-L" 43 "Overpass-R" 44 "Overpass-L" 45 "Underpass-R" 46 "Underpass-L" 47 "Schematic Diagram" 3 "Arrived" 4 "Near Dest" 64 "No Direction" 65 "Straight" 66 "Turn 1 oclock" 67 "Turn-R" 68 "Turn 4 oclock" 69 "Turn 8 oclock" 70 "Turn-L" 71 "Turn 11 oclock" 72 "U Turn-L" 73 "U Turn-R" 74 "P Turn-L" 75 "P Turn-R" 76 "Permitted Turn-L" 5 "Arrived Dest Off Map" 80 "Aside Overpass-C" 81 "Aside Overpass-R" 82 "Aside Overpass-L" 83 "Aside Underpass-C" 84 "Aside Underpass-R" 85 "Aside Underpass-L" 86 "Into Overpass-C" 87 "Into Overpass-R" 88 "Into Overpass-L" 89 "Into Underpass-C" 90 "Into Underpass-R" 91 "Into Underpass-L" 6 "OffRoad" 96 "Roundabout(R12)" 97 "Roundabout(R1~R11)" 98 "Roundabout(R1~R11)" 99 "Roundabout(R1~R11)" 100 "Roundabout(R1~R11)" 101 "Roundabout(R1~R11)" 102 "Roundabout(R1~R11)" 103 "Roundabout(R1~R11)" 104 "Roundabout(R1~R11)" 105 "Roundabout(R1~R11)" 106 "Roundabout(R1~R11)" 107 "Roundabout(R1~R11)" 7 "Off Map" 112 "Dest-C" 113 "Dest-R" 114 "Dest-L" 115 "WP1-C" 116 "WP1-R" 117 "WP1-L" 118 "WP2-C" 119 "WP2-R" 120 "WP2-L" 121 "WP3-C" 122 "WP3-R" 123 "WP3-L" 124 "WP4-C" 125 "WP4-R" 126 "WP4-L" 8 "No Route(Compass)" 128 "WP5-C" 129 "WP5-L" 130 "WP5-R" 131 "WP6-C" 132 "WP6-L" 133 "WP6-R" 134 "WP7-C" 135 "WP7-L" 136 "WP7-R" 137 "walk to Dest" 138 "walk to WP1" 139 "walk to WP2" 140 "walk to WP3" 141 "walk to WP4" 9 "Calc Route" 144 "Fork-2-R" 145 "Fork-2-L" 146 "Fork-SR Straight" 147 "Fork-SR-R" 148 "Fork-SL Straight" 149 "Fork-SL-L" 10 "Recalc Route" 160 "FWY Entrance-C" 161 "FWY Entrance-R" 162 "FWY Entrance-L" 163 "FWY Exit-C" 164 "FWY Exit-R" 165 "FWY Exit-L" 166 "CHWY Entrance-C" 167 "CHWY Entrance-R" 168 "CHWY Entrance-L" 169 "CHWY Exit-C" 170 "CHWY Exit-R" 171 "CHWY Exit-L" 172 "MainRoad Entrance-C" 173 "MainRoad Entrance-R" 174 "MainRoad Entrance-L" 11 "Follow Street" 176 "Ferry" 177 "Tunnel" 178 "Toll" 179 "IC" 180 "JC" 181 "SA" 182 "PA" 183 "SA Entrance" 184 "Coin Toll" 185 "JC Exit-C" 186 "JC Exit-R" 187 "JC Exit-L" 12 "Change Lane" 192 "Roundabout(L12)" 193 "Roundabout(L1~L11)" 194 "Roundabout(L1~L11)" 195 "Roundabout(L1~L11)" 196 "Roundabout(L1~L11)" 197 "Roundabout(L1~L11)" 198 "Roundabout(L1~L11)" 199 "Roundabout(L1~L11)" 200 "Roundabout(L1~L11)" 201 "Roundabout(L1~L11)" 202 "Roundabout(L1~L11)" 203 "Roundabout(L1~L11)" 204 "Enter roundabout" 205 "Exit roundabout" 206 "most-L of line" 207 "most-R of line" 13 "Turn" 208 "M of line" 209 "most-L of 3 normal/JCT/SAPA" 210 "most-R of 3 normal/JCT/SAPA" 211 "Enter ferry" 212 "Exit ferry" 213 "8 direction L front-L" 214 "8 direction L front-R" 215 "8 direction R front-L" 216 "8 direction R front-R" 217 "Go Straight Conditions" 218 "M of 3 normal/JCT/SAPA" 219 "Starting Point" 220 "IC 2 on L straight walk IC" 221 "IC 2 on the R straight walk IC" 222 "Normal/JCT/SAPA 2 on L straight line" 223 "Normal/JCT/SAPA 2 on R straight line" 14 "Turn On Main Road" 224 "Normal/JCT/SAPA 3 on L straight line" 225 "Normal/JCT/SAPA 3 on M straight line" 226 "Normal/JCT/SAPA 3 on R straight line" 227 "IC 3 on L side of IC" 228 "IC 3 on M side of IC" 229 "IC 3 on R side of IC" 230 "IC 3 on L straight line" 231 "IC 3 on M straight line" 232 "IC 3 on R straight line" 233 "8 direction straight L" 234 "8 direction straight R" 235 "8 direction on the most L straight line" 236 "8 direction on M straight line" 237 "8 direction on the most R straight line" 238 "8 direction turn L, then L" 239 "8 direction turn L, then R" 15 "Turn Combination1" 240 "8 direction turn L, then the most L" 241 "8 direction turn L, then M" 242 "8 direction turn L, then the most R" 243 "8 direction turn R, then L" 244 "8 direction turn R, then R" 245 "8 direction turn R, then the most L" 246 "8 direction turn R, then M" 247 "8 direction turn R, then the most R" 248 "8 direction turn around, then L" 249 "8 direction turn around, then R" 250 "8 direction turn around, then the most L" 251 "8 direction turn around, then M" 252 "8 direction turn around, then the most R" 253 "Reserved" 254 "Reserved" 255 "Invalid" ;
VAL_ 277 TBT_Side_Street 65535 "Invalid" ;
VAL_ 277 TBT_Direction 0 "Increase value (0~352.5 deg.)" 1 "Increase value (0~352.5 deg.)" 2 "Increase value (0~352.5 deg.)" 3 "Increase value (0~352.5 deg.)" 4 "Increase value (0~352.5 deg.)" 5 "Increase value (0~352.5 deg.)" 6 "Increase value (0~352.5 deg.)" 7 "Increase value (0~352.5 deg.)" 8 "Increase value (0~352.5 deg.)" 9 "Increase value (0~352.5 deg.)" 10 "Increase value (0~352.5 deg.)" 11 "Increase value (0~352.5 deg.)" 12 "Increase value (0~352.5 deg.)" 13 "Increase value (0~352.5 deg.)" 14 "Increase value (0~352.5 deg.)" 15 "Increase value (0~352.5 deg.)" 16 "Increase value (0~352.5 deg.)" 17 "Increase value (0~352.5 deg.)" 18 "Increase value (0~352.5 deg.)" 19 "Increase value (0~352.5 deg.)" 20 "Increase value (0~352.5 deg.)" 21 "Increase value (0~352.5 deg.)" 22 "Increase value (0~352.5 deg.)" 23 "Increase value (0~352.5 deg.)" 24 "Increase value (0~352.5 deg.)" 25 "Increase value (0~352.5 deg.)" 26 "Increase value (0~352.5 deg.)" 27 "Increase value (0~352.5 deg.)" 28 "Increase value (0~352.5 deg.)" 29 "Increase value (0~352.5 deg.)" 30 "Increase value (0~352.5 deg.)" 31 "Increase value (0~352.5 deg.)" 32 "Increase value (0~352.5 deg.)" 33 "Increase value (0~352.5 deg.)" 34 "Increase value (0~352.5 deg.)" 35 "Increase value (0~352.5 deg.)" 36 "Increase value (0~352.5 deg.)" 37 "Increase value (0~352.5 deg.)" 38 "Increase value (0~352.5 deg.)" 39 "Increase value (0~352.5 deg.)" 40 "Increase value (0~352.5 deg.)" 41 "Increase value (0~352.5 deg.)" 42 "Increase value (0~352.5 deg.)" 43 "Increase value (0~352.5 deg.)" 44 "Increase value (0~352.5 deg.)" 45 "Increase value (0~352.5 deg.)" 46 "Increase value (0~352.5 deg.)" 47 "Increase value (0~352.5 deg.)" 255 "Invalid" ;
VAL_ 277 TBT_Distance_Turn_Point 0 "0" 1 "0x0001~0xFFFE:distance" 65534 "0x0001~0xFFFE:distance" 65535 "Invalid" ;
VAL_ 277 TBT_Combined_Side_Street 0 "No Combined" 1 "Right Combined" 2 "Left combined" 3 "Bothside" 4 "Reserved" 5 "Reserved" 6 "Reserved" 7 "Reserved" 8 "Reserved" 9 "Reserved" 10 "Reserved" 11 "Reserved" 12 "Reserved" 13 "Reserved" 14 "Reserved" 15 "Invalid" ;
VAL_ 277 TBT_Scale 0 "Meter" 1 "Kilometer" 2 "Mile" 3 "Feet" 4 "yard" 15 "Invalid" ;
VAL_ 277 TBT_DistancetoTurnPoint 0 "0" 1 "number of tuning point" 2 "number of tuning point" 3 "number of tuning point" 4 "number of tuning point" 5 "number of tuning point" 6 "number of tuning point" 7 "number of tuning point" 8 "number of tuning point" 9 "number of tuning point" 10 "Reserved" 11 "Reserved" 12 "Reserved" 13 "Reserved" 14 "Reserved" 15 "Invalid" ;
VAL_ 407 HU_LanguageInfo 0 "Off" 1 "Korea" 2 "English(US)" 3 "English(UK)" 4 "Simplified chinese" 5 "Traditional chinese" 6 "French(EU)" 7 "Spanish(EU)" 8 "Arabic" 9 "Czech" 10 "Danish" 11 "German" 12 "Italian" 13 "Dutch" 14 "Polish" 15 "Portuguese" 16 "Russain" 17 "Slovak" 18 "Swedish" 19 "Turkish" 20 "French(US)" 21 "Spanish(US)" 22 "English(India)" 23 "Norwegian" 24 "Finnish" 25 "Indonesian" 26 "Brazilian Portuguese" 27 "Malay" 28 "Hungarian" 29 "English (Australia)" 30 "Japanese" 31 "0x1F~0xFE:reserved" 254 "0x1F~0xFE:reserved" 255 "Invalid" ;
VAL_ 407 HU_MuteStatus 0 "Off" 1 "Mute On" 2 "reserved" 3 "Invalid" ;
VAL_ 407 HU_VolumeStatus 63 "Invalid" ;
VAL_ 407 HU_NaviDisp 0 "Non_Navi" 1 "Navi" 2 "reserved" 3 "Invalid" ;
VAL_ 407 HU_NaviStatus 0 "Booting" 1 "Normal Operation" 2 "No SD Card(Map)" 3 "Invalid" ;
VAL_ 290 HU_OpState_New 0 "Initial" 1 "iBox App" 2 "Reserved" 3 "Reserved" 4 "Reserved" 5 "Reserved" 6 "ZUNE" 7 "Juke Box" 8 "Bluetooth Audio" 9 "Reserved" 10 "AV OFF" 11 "AV PowerOFF" 12 "MY music (ripping)" 13 "Internet Radio(Pandora)" 14 "Internet Radio(Kaola FM)" 15 "JukeBox-video" 16 "Aha Radio" 17 "FM" 18 "FM1" 19 "FM2" 20 "AM" 21 "Reserved" 22 "Reserved" 23 "Reserved" 24 "FMA" 25 "AMA" 26 "Emergency Call" 27 "ACN" 28 "Center Call" 29 "Hyundai Emergency Services" 30 "Kia Emergency Services" 31 "Reserved" 32 "Reserved" 33 "FM(HD)" 34 "FM1(HD)" 35 "FM2(HD)" 36 "AM(HD)" 37 "FMA_OLD(Use 0x18)" 38 "AMA_OLD(Use 0x19)" 39 "Reserved" 40 "Reserved" 41 "Reserved" 42 "Mozen Incoming call" 43 "Mozen Active call" 44 "Mozen Hangup" 45 "Mozen outgoing call" 46 "Reserved" 47 "Reserved" 48 "Reserved" 49 "SXM" 50 "XM1" 51 "XM2" 52 "XM3" 53 "Reserved" 54 "DAB" 55 "DAB1" 56 "DAB2" 57 "DAB3" 58 "Reserved" 59 "SXM Receiving" 60 "SXM Signal Weak" 61 "Reserved" 62 "DAB Receiving" 63 "DAB Signal Weak" 64 "Reserved" 65 "DMB1 TV" 66 "ISDB-T" 67 "Reserved" 68 "Reserved" 69 "DMB TV" 70 "DMB Radio" 71 "DMB Searching" 72 "Reserved" 73 "Reserved" 74 "Reserved" 75 "DMB Receiving" 76 "DMB Signal Weak" 77 "Reserved" 78 "Reserved" 79 "Reserved" 80 "CD" 81 "CD Audio" 82 "CD MP3" 83 "Mixed CD (Audio)" 84 "DVD" 85 "Reserved" 86 "Reserved" 87 "Reserved" 88 "Reserved" 89 "Disc reading" 90 "Mirror Link" 91 "Car Life" 92 "Reserved" 93 "READING CD" 94 "LOADING CD" 95 "Reserved" 96 "Loading" 97 "iPod" 98 "USB" 99 "AUX(Use 0x6B 0x6C Instead)" 100 "USB Video" 101 "USB Music" 102 "Rear USB Video" 103 "Rear USB Audio" 104 "IPOD Reading" 105 "USB Reading" 106 "Reading Media" 107 "AUX-audio" 108 "AUX-video" 109 "Reserved" 110 "CarPlay" 111 "Android Auto" 112 "Reserved" 113 "Incoming call" 114 "Active call" 115 "Hangup" 116 "Last Call" 117 "Reserved" 118 "Reserved" 119 "Reserved" 120 "Reserved" 121 "Reserved" 122 "BlueLink Mode" 123 "MOZEN Mode for cubis -T" 124 "RSA" 125 "Baidu Music" 126 "QQ Music" 127 "Invalid" ;
VAL_ 290 HU_Frequency_Unit 0 "Off (Not Display)" 1 "On (Display)" 2 "Reserved" 3 "Invalid" ;
VAL_ 290 HU_User_Input 0 "Off" 1 "User Input" 2 "Reserved" 3 "Invalid" ;
VAL_ 290 HU_FMFrequency_Offset_Type 0 "Offset Type 1(8750)" 1 "Offset Type 2(6000)" 2 "Reserved" 3 "Invalid" ;
VAL_ 290 FM_Decimal_Point 0 "Off" 1 "1 Digit under point" 2 "2 Digits under point" 3 "Invalid" ;
VAL_ 290 HU_Track_Number_New 0 "0x0~0x327:Track No." 807 "0x0~0x327:Track No." 65535 "Invalid" ;
VAL_ 290 HU_Play_time_Sec_New 0 "0~59 sec." 1 "0~59 sec." 2 "0~59 sec." 3 "0~59 sec." 4 "0~59 sec." 5 "0~59 sec." 6 "0~59 sec." 7 "0~59 sec." 8 "0~59 sec." 9 "0~59 sec." 10 "0~59 sec." 11 "0~59 sec." 12 "0~59 sec." 13 "0~59 sec." 14 "0~59 sec." 15 "0~59 sec." 16 "0~59 sec." 17 "0~59 sec." 18 "0~59 sec." 19 "0~59 sec." 20 "0~59 sec." 21 "0~59 sec." 22 "0~59 sec." 23 "0~59 sec." 24 "0~59 sec." 25 "0~59 sec." 26 "0~59 sec." 27 "0~59 sec." 28 "0~59 sec." 29 "0~59 sec." 30 "0~59 sec." 31 "0~59 sec." 32 "0~59 sec." 33 "0~59 sec." 34 "0~59 sec." 35 "0~59 sec." 36 "0~59 sec." 37 "0~59 sec." 38 "0~59 sec." 39 "0~59 sec." 40 "0~59 sec." 41 "0~59 sec." 42 "0~59 sec." 43 "0~59 sec." 44 "0~59 sec." 45 "0~59 sec." 46 "0~59 sec." 47 "0~59 sec." 48 "0~59 sec." 49 "0~59 sec." 50 "0~59 sec." 51 "0~59 sec." 52 "0~59 sec." 53 "0~59 sec." 54 "0~59 sec." 55 "0~59 sec." 56 "0~59 sec." 57 "0~59 sec." 58 "0~59 sec." 59 "0~59 sec." 63 "Invalid" ;
VAL_ 290 HU_Play_time_Min_New 0 "0~59 min." 1 "0~59 min." 2 "0~59 min." 3 "0~59 min." 4 "0~59 min." 5 "0~59 min." 6 "0~59 min." 7 "0~59 min." 8 "0~59 min." 9 "0~59 min." 10 "0~59 min." 11 "0~59 min." 12 "0~59 min." 13 "0~59 min." 14 "0~59 min." 15 "0~59 min." 16 "0~59 min." 17 "0~59 min." 18 "0~59 min." 19 "0~59 min." 20 "0~59 min." 21 "0~59 min." 22 "0~59 min." 23 "0~59 min." 24 "0~59 min." 25 "0~59 min." 26 "0~59 min." 27 "0~59 min." 28 "0~59 min." 29 "0~59 min." 30 "0~59 min." 31 "0~59 min." 32 "0~59 min." 33 "0~59 min." 34 "0~59 min." 35 "0~59 min." 36 "0~59 min." 37 "0~59 min." 38 "0~59 min." 39 "0~59 min." 40 "0~59 min." 41 "0~59 min." 42 "0~59 min." 43 "0~59 min." 44 "0~59 min." 45 "0~59 min." 46 "0~59 min." 47 "0~59 min." 48 "0~59 min." 49 "0~59 min." 50 "0~59 min." 51 "0~59 min." 52 "0~59 min." 53 "0~59 min." 54 "0~59 min." 55 "0~59 min." 56 "0~59 min." 57 "0~59 min." 58 "0~59 min." 59 "0~59 min." 63 "Invalid" ;
VAL_ 290 HU_Play_time_Hour_New 0 "0~99 Hour" 1 "0~99 Hour" 2 "0~99 Hour" 3 "0~99 Hour" 4 "0~99 Hour" 5 "0~99 Hour" 6 "0~99 Hour" 7 "0~99 Hour" 8 "0~99 Hour" 9 "0~99 Hour" 10 "0~99 Hour" 11 "0~99 Hour" 12 "0~99 Hour" 13 "0~99 Hour" 14 "0~99 Hour" 15 "0~99 Hour" 16 "0~99 Hour" 17 "0~99 Hour" 18 "0~99 Hour" 19 "0~99 Hour" 20 "0~99 Hour" 21 "0~99 Hour" 22 "0~99 Hour" 23 "0~99 Hour" 24 "0~99 Hour" 25 "0~99 Hour" 26 "0~99 Hour" 27 "0~99 Hour" 28 "0~99 Hour" 29 "0~99 Hour" 30 "0~99 Hour" 31 "0~99 Hour" 32 "0~99 Hour" 33 "0~99 Hour" 34 "0~99 Hour" 35 "0~99 Hour" 36 "0~99 Hour" 37 "0~99 Hour" 38 "0~99 Hour" 39 "0~99 Hour" 40 "0~99 Hour" 41 "0~99 Hour" 42 "0~99 Hour" 43 "0~99 Hour" 44 "0~99 Hour" 45 "0~99 Hour" 46 "0~99 Hour" 47 "0~99 Hour" 48 "0~99 Hour" 49 "0~99 Hour" 50 "0~99 Hour" 51 "0~99 Hour" 52 "0~99 Hour" 53 "0~99 Hour" 54 "0~99 Hour" 55 "0~99 Hour" 56 "0~99 Hour" 57 "0~99 Hour" 58 "0~99 Hour" 59 "0~99 Hour" 60 "0~99 Hour" 61 "0~99 Hour" 62 "0~99 Hour" 63 "0~99 Hour" 64 "0~99 Hour" 65 "0~99 Hour" 66 "0~99 Hour" 67 "0~99 Hour" 68 "0~99 Hour" 69 "0~99 Hour" 70 "0~99 Hour" 71 "0~99 Hour" 72 "0~99 Hour" 73 "0~99 Hour" 74 "0~99 Hour" 75 "0~99 Hour" 76 "0~99 Hour" 77 "0~99 Hour" 78 "0~99 Hour" 79 "0~99 Hour" 80 "0~99 Hour" 81 "0~99 Hour" 82 "0~99 Hour" 83 "0~99 Hour" 84 "0~99 Hour" 85 "0~99 Hour" 86 "0~99 Hour" 87 "0~99 Hour" 88 "0~99 Hour" 89 "0~99 Hour" 90 "0~99 Hour" 91 "0~99 Hour" 92 "0~99 Hour" 93 "0~99 Hour" 94 "0~99 Hour" 95 "0~99 Hour" 96 "0~99 Hour" 97 "0~99 Hour" 98 "0~99 Hour" 99 "0~99 Hour" 127 "Invalid" ;
VAL_ 290 HU_Frequency_New 0 "0x0~0x1FFE:Refer to Signal Description" 8190 "0x0~0x1FFE:Refer to Signal Description" 8191 "invalid" ;
VAL_ 291 NV_Display_TG 0 "off" 1 "on" 2 "not used" 3 "invalid" ;
VAL_ 291 TBT_BarGraph100Level 0 "0x0~0x64:Physical value" 100 "0x0~0x64:Physical value" 254 "Not Displayed" 255 "initial value, invald" ;
VAL_ 286 Navi_WarnDist_OverDec 0 "0" 1 "0x1~0xFFFD:distance" 65533 "0x1~0xFFFD:distance" 65533 "no display over decimal point" 65535 "invalid" ;
VAL_ 286 Navi_WarnDist_UnderDec 0 "0" 1 "distance" 2 "distance" 3 "distance" 4 "distance" 5 "distance" 6 "distance" 7 "distance" 8 "distance" 9 "distance" 10 "reserved" 11 "reserved" 12 "reserved" 13 "reserved" 14 "no display under decimal point" 15 "invalid" ;
VAL_ 286 Navi_WarnDist_Scale 0 "m" 1 "km" 2 "mile" 3 "feet" 4 "yard" 5 "reserved" 6 "reserved" 7 "reserved" 8 "reserved" 9 "reserved" 10 "reserved" 11 "reserved" 12 "reserved" 13 "reserved" 14 "reserved" 15 "invalid" ;
VAL_ 52 HU_DATC_DrTempUpDn 0 "Reserved" 1 "Temp Up" 2 "Temp Down" 3 "Invalid" ;
VAL_ 52 HU_DATC_MainBlower 0 "DATC Off" 1 "0 level (Do not use)" 2 "1 level" 3 "2 level" 4 "3 level" 5 "4 level" 6 "5 level" 7 "6 level" 8 "7 level" 9 "8 level" 15 "Invalid" ;
VAL_ 52 HU_DATC_FrontModeSet 0 "Reserved" 1 "VENT" 2 "BL" 3 "FLOOR" 4 "MIX" 5 "reserved" 6 "reserved" 7 "reserved" 8 "reserved" 9 "reserved" 10 "reserved" 11 "reserved" 12 "reserved" 13 "reserved" 14 "reserved" 15 "Invalid" ;
VAL_ 52 HU_DATC_AutoSet 0 "reserved" 1 "AUTO ON" 2 "reserved" 3 "Invalid" ;
VAL_ 52 HU_DATC_IntakeSet 0 "REC Off (Fresh On)" 1 "REC ON (Fresh Off" 2 "reserved" 3 "Invalid" ;
VAL_ 52 HU_DATC_AcSet 0 "AC Off" 1 "AC ON" 2 "reserved" 3 "Invalid" ;
VAL_ 52 HU_DATC_FrontDefog 0 "Defog Off" 1 "Defog On" 2 "reserved" 3 "Invalid" ;
VAL_ 52 HU_DATC_MainBlowerUpDn 0 "Reserved" 1 "Up" 2 "Down" 3 "Invalid" ;
VAL_ 52 HU_DATC_AirCleaningSet 0 "Air Cleaning System Off" 1 "Air Cleaning System On" 2 "Air Cleaning System Not Support" 3 "Invalid" ;
VAL_ 54 HU_DATC_DrTempSetC 0 "Blank" 1 "LO" 2 "PHY=HEX*0.5 + 14" 3 "PHY=HEX*0.5 + 14" 4 "PHY=HEX*0.5 + 14" 5 "PHY=HEX*0.5 + 14" 6 "PHY=HEX*0.5 + 14" 7 "PHY=HEX*0.5 + 14" 8 "PHY=HEX*0.5 + 14" 9 "PHY=HEX*0.5 + 14" 10 "PHY=HEX*0.5 + 14" 11 "PHY=HEX*0.5 + 14" 12 "PHY=HEX*0.5 + 14" 13 "PHY=HEX*0.5 + 14" 14 "PHY=HEX*0.5 + 14" 15 "PHY=HEX*0.5 + 14" 16 "PHY=HEX*0.5 + 14" 17 "PHY=HEX*0.5 + 14" 18 "PHY=HEX*0.5 + 14" 19 "PHY=HEX*0.5 + 14" 20 "PHY=HEX*0.5 + 14" 21 "PHY=HEX*0.5 + 14" 22 "PHY=HEX*0.5 + 14" 23 "PHY=HEX*0.5 + 14" 24 "PHY=HEX*0.5 + 14" 25 "PHY=HEX*0.5 + 14" 26 "PHY=HEX*0.5 + 14" 27 "PHY=HEX*0.5 + 14" 28 "PHY=HEX*0.5 + 14" 29 "PHY=HEX*0.5 + 14" 30 "PHY=HEX*0.5 + 14" 31 "PHY=HEX*0.5 + 14" 32 "PHY=HEX*0.5 + 14" 33 "PHY=HEX*0.5 + 14" 34 "PHY=HEX*0.5 + 14" 35 "PHY=HEX*0.5 + 14" 36 "PHY=HEX*0.5 + 14" 37 "0x25~0xFD:Reserved" 253 "0x25~0xFD:Reserved" 254 "HI" 255 "Invalid" ;
VAL_ 54 HU_DATC_DrTempSetF 0 "Blank" 1 "LO" 2 "PHY=HEX*1 + 56" 3 "PHY=HEX*1 + 56" 4 "PHY=HEX*1 + 56" 5 "PHY=HEX*1 + 56" 6 "PHY=HEX*1 + 56" 7 "PHY=HEX*1 + 56" 8 "PHY=HEX*1 + 56" 9 "PHY=HEX*1 + 56" 10 "PHY=HEX*1 + 56" 11 "PHY=HEX*1 + 56" 12 "PHY=HEX*1 + 56" 13 "PHY=HEX*1 + 56" 14 "PHY=HEX*1 + 56" 15 "PHY=HEX*1 + 56" 16 "PHY=HEX*1 + 56" 17 "PHY=HEX*1 + 56" 18 "PHY=HEX*1 + 56" 19 "PHY=HEX*1 + 56" 20 "PHY=HEX*1 + 56" 21 "PHY=HEX*1 + 56" 22 "PHY=HEX*1 + 56" 23 "PHY=HEX*1 + 56" 24 "PHY=HEX*1 + 56" 25 "PHY=HEX*1 + 56" 26 "PHY=HEX*1 + 56" 27 "PHY=HEX*1 + 56" 28 "PHY=HEX*1 + 56" 29 "PHY=HEX*1 + 56" 30 "PHY=HEX*1 + 56" 31 "PHY=HEX*1 + 56" 32 "PHY=HEX*1 + 56" 33 "PHY=HEX*1 + 56" 34 "PHY=HEX*1 + 56" 35 "PHY=HEX*1 + 56" 36 "PHY=HEX*1 + 56" 37 "0x25~0xFD:Reserved" 253 "0x25~0xFD:Reserved" 254 "HI" 255 "Invalid" ;
VAL_ 54 C_DATC_DTC_Mode 0 "Off(Default)" 1 "Diagnosis Code Display" 2 "Reserved" 3 "Invalid" ;
VAL_ 270 C_TeleCrankingCmdIBOX 0 "default (off)" 1 "Cranking" 2 "stop" 3 "Invalid" ;
VAL_ 270 C_FLSeatHeaterSW 0 "Off" 1 "On" 2 "Reserved" 3 "Invalid" ;
VAL_ 270 C_FLSeatCoolerSW 0 "Off" 1 "On" 2 "Reserved" 3 "Invalid" ;
VAL_ 270 C_FRSeatHeaterSW 0 "Off" 1 "On" 2 "Reserved" 3 "Invalid" ;
VAL_ 270 C_FRSeatCoolerSW 0 "Off" 1 "On" 2 "Reserved" 3 "Invalid" ;
VAL_ 256 HU_Type 16 "AVN(Tuner DVD KOR)" 17 "AVN(Tuner DVD EUR)" 18 "AVN(Tuner DVD China)" 19 "AVN(Tuner DVD Japan)" 20 "AVN(Tuner DVD EUR)" 21 "AVN(Tuner CDP KOR)" 22 "AVN(Tuner CDP EUR)" 23 "AVN(Tuner CDP China)" 24 "AVN(Tuner CDP Japan)" 25 "AVN(Tuner CDP EUR)" 32 "AVNT (Open)" 33 "AVNT (Not open)" 48 "Economic Audio" 64 "Standard Audio (3.0 below)" 65 "Standard Audio 4.0" 66 "STD Audio-3.0Below,No interwork" 67 "Audio 4.0 Value" 80 "AV(Tuner DVD KOR)" 81 "AV(Tuner DVD EUR)" 82 "AV(Tuner DVD China)" 83 "AV(Tuner DVD Japan)" 84 "AV(Tuner DVD EUR)" 85 "AV(Tuner CDP KOR)" 86 "AV(Tuner CDP EUR)" 87 "AV(Tuner CDP China)" 88 "AV(Tuner CDP Japan)" 89 "AV(Tuner CDP EUR)" 96 "AVN 4.0" 97 "Premium AVN2.0" 98 "EU AVN 2.0" 99 "Super Premium w Navi" 100 "Super Premium w_o Navi" 101 "Premium w Navi" 102 "Premium w_o Navi" 103 "Display Audio w_o Navi" 104 "Integrated AVN 1.0 Mobis" 105 "Gen5 Standard Nav Wide" 112 "Compact AVN & Integrated AVN 1.0 LG" 128 "Premium Navi 5th Gen(w/Navi)" 129 "Premium Navi 5th Gen(w/o Navi)" 130 "Premium Navi 6th Gen(w/Navi)" 131 "Premium Navi 6th Gen(w/o Navi)" 250 "PIO AVN" 251 "China only OEM AV" 252 "China OPIO w/o CLU interface" 253 "China OPIO w/CLU interface" 255 "Invalid" ;
VAL_ 256 HU_DistributeInfo 0 "Default (Korea)" 1 "Korea" 2 "North America" 3 "Canada" 4 "East Europe" 5 "West Europe" 6 "China" 7 "India" 8 "Australia" 9 "Middle East" 10 "Africa" 11 "South America" 12 "Russia" 13 "Reserved" 14 "General" 15 "0x0F~0xFE:Reserved" 254 "0x0F~0xFE:Reserved" 255 "Invalid" ;
VAL_ 256 HU_OptionInfo 32768 "Invalid" ;
